VERSION ""

NS_ :

BS_:

BU_: SHVU_CCS_FD ARS_FD WPC_FD WPC2_FD SCM_FD SHVU_FRNT_FD FLLR_FD GW_SAU_DRV_FD ATS_FD PSB_FD GW_PSU_RR_FD SHVU_RL_FD RWPC_FD CGW_CCU OHCL_FD SHVU_REAR_FD BLTN_CAM_FD GW_PSU_DRV_FD FCS_FD GW_PSU_AST_FD GW_PSU_3RD_FD RCS_FD GW_PSU_RL_FD SHVU_3RD_FD SHVU_RR_FD RCM_FD DCM_FD SGU_FD vFD_B2

BO_ 977 BDC_FD_02_200ms: 32 CGW_CCU
 SG_ BCM_Ign2InSta_Copy_0 : 24|2@1+ (1,0) [0|0] ""  ARS_FD,ATS_FD,BLTN_CAM_FD,DCM_FD,FCS_FD,FLLR_FD,GW_PSU_3RD_FD,GW_PSU_AST_FD,GW_PSU_DRV_FD,GW_PSU_RL_FD,GW_PSU_RR_FD,GW_SAU_DRV_FD,OHCL_FD,PSB_FD,RCM_FD,RCS_FD,RWPC_FD,SCM_FD,SGU_FD,SHVU_3RD_FD,SHVU_CCS_FD,SHVU_FRNT_FD,SHVU_REAR_FD,SHVU_RL_FD,SHVU_RR_FD,vFD_B2,WPC2_FD,WPC_FD
 SG_ BCM_Ign1InSta_Copy_0 : 26|2@1+ (1,0) [0|0] ""  ARS_FD,ATS_FD,BLTN_CAM_FD,DCM_FD,FCS_FD,FLLR_FD,GW_PSU_3RD_FD,GW_PSU_AST_FD,GW_PSU_DRV_FD,GW_PSU_RL_FD,GW_PSU_RR_FD,GW_SAU_DRV_FD,OHCL_FD,PSB_FD,RCM_FD,RCS_FD,RWPC_FD,SCM_FD,SGU_FD,SHVU_3RD_FD,SHVU_CCS_FD,SHVU_FRNT_FD,SHVU_REAR_FD,SHVU_RL_FD,SHVU_RR_FD,vFD_B2,WPC2_FD,WPC_FD
 SG_ BCM_AccInSta_Copy_0 : 28|2@1+ (1,0) [0|0] ""  ARS_FD,ATS_FD,BLTN_CAM_FD,DCM_FD,FCS_FD,FLLR_FD,GW_PSU_3RD_FD,GW_PSU_AST_FD,GW_PSU_DRV_FD,GW_PSU_RL_FD,GW_PSU_RR_FD,GW_SAU_DRV_FD,OHCL_FD,PSB_FD,RCM_FD,RCS_FD,RWPC_FD,SCM_FD,SGU_FD,SHVU_3RD_FD,SHVU_CCS_FD,SHVU_FRNT_FD,SHVU_REAR_FD,SHVU_RL_FD,SHVU_RR_FD,vFD_B2,WPC2_FD,WPC_FD
 SG_ BCM_KeyInSta_Copy_0 : 30|2@1+ (1,0) [0|0] ""  ARS_FD,ATS_FD,BLTN_CAM_FD,DCM_FD,FCS_FD,FLLR_FD,GW_PSU_3RD_FD,GW_PSU_AST_FD,GW_PSU_DRV_FD,GW_PSU_RL_FD,GW_PSU_RR_FD,GW_SAU_DRV_FD,OHCL_FD,PSB_FD,RCM_FD,RCS_FD,RWPC_FD,SCM_FD,SGU_FD,SHVU_3RD_FD,SHVU_CCS_FD,SHVU_FRNT_FD,SHVU_REAR_FD,SHVU_RL_FD,SHVU_RR_FD,vFD_B2,WPC2_FD,WPC_FD

BO_ 1941 dummy_GST_BLTN_CAM: 8 CGW_CCU
 SG_ dummy_GST_BLTN_CAM_Byte : 0|64@1+ (1,0) [0|0] ""  BLTN_CAM_FD

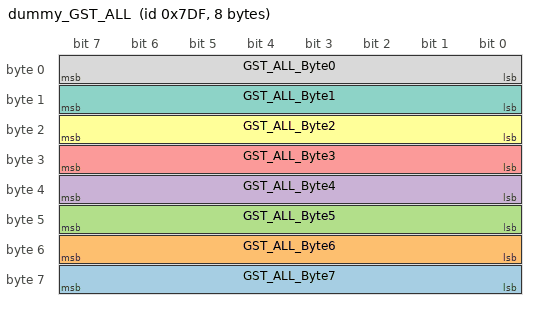
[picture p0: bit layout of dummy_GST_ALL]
BO_ 2015 dummy_GST_ALL: 8 CGW_CCU
 SG_ GST_ALL_Byte7 : 56|8@1+ (1,0) [0|0] ""  ARS_FD,ATS_FD,BLTN_CAM_FD,DCM_FD,FCS_FD,FLLR_FD,GW_PSU_3RD_FD,GW_PSU_AST_FD,GW_PSU_DRV_FD,GW_PSU_RL_FD,GW_PSU_RR_FD,GW_SAU_DRV_FD,OHCL_FD,PSB_FD,RCM_FD,RCS_FD,RWPC_FD,SCM_FD,SGU_FD,SHVU_3RD_FD,SHVU_CCS_FD,SHVU_FRNT_FD,SHVU_REAR_FD,SHVU_RL_FD,SHVU_RR_FD,vFD_B2,WPC2_FD,WPC_FD
 SG_ GST_ALL_Byte6 : 48|8@1+ (1,0) [0|0] ""  ARS_FD,ATS_FD,BLTN_CAM_FD,DCM_FD,FCS_FD,FLLR_FD,GW_PSU_3RD_FD,GW_PSU_AST_FD,GW_PSU_DRV_FD,GW_PSU_RL_FD,GW_PSU_RR_FD,GW_SAU_DRV_FD,OHCL_FD,PSB_FD,RCM_FD,RCS_FD,RWPC_FD,SCM_FD,SGU_FD,SHVU_3RD_FD,SHVU_CCS_FD,SHVU_FRNT_FD,SHVU_REAR_FD,SHVU_RL_FD,SHVU_RR_FD,vFD_B2,WPC2_FD,WPC_FD
 SG_ GST_ALL_Byte5 : 40|8@1+ (1,0) [0|0] ""  ARS_FD,ATS_FD,BLTN_CAM_FD,DCM_FD,FCS_FD,FLLR_FD,GW_PSU_3RD_FD,GW_PSU_AST_FD,GW_PSU_DRV_FD,GW_PSU_RL_FD,GW_PSU_RR_FD,GW_SAU_DRV_FD,OHCL_FD,PSB_FD,RCM_FD,RCS_FD,RWPC_FD,SCM_FD,SGU_FD,SHVU_3RD_FD,SHVU_CCS_FD,SHVU_FRNT_FD,SHVU_REAR_FD,SHVU_RL_FD,SHVU_RR_FD,vFD_B2,WPC2_FD,WPC_FD
 SG_ GST_ALL_Byte4 : 32|8@1+ (1,0) [0|0] ""  ARS_FD,ATS_FD,BLTN_CAM_FD,DCM_FD,FCS_FD,FLLR_FD,GW_PSU_3RD_FD,GW_PSU_AST_FD,GW_PSU_DRV_FD,GW_PSU_RL_FD,GW_PSU_RR_FD,GW_SAU_DRV_FD,OHCL_FD,PSB_FD,RCM_FD,RCS_FD,RWPC_FD,SCM_FD,SGU_FD,SHVU_3RD_FD,SHVU_CCS_FD,SHVU_FRNT_FD,SHVU_REAR_FD,SHVU_RL_FD,SHVU_RR_FD,vFD_B2,WPC2_FD,WPC_FD
 SG_ GST_ALL_Byte3 : 24|8@1+ (1,0) [0|0] ""  ARS_FD,ATS_FD,BLTN_CAM_FD,DCM_FD,FCS_FD,FLLR_FD,GW_PSU_3RD_FD,GW_PSU_AST_FD,GW_PSU_DRV_FD,GW_PSU_RL_FD,GW_PSU_RR_FD,GW_SAU_DRV_FD,OHCL_FD,PSB_FD,RCM_FD,RCS_FD,RWPC_FD,SCM_FD,SGU_FD,SHVU_3RD_FD,SHVU_CCS_FD,SHVU_FRNT_FD,SHVU_REAR_FD,SHVU_RL_FD,SHVU_RR_FD,vFD_B2,WPC2_FD,WPC_FD
 SG_ GST_ALL_Byte2 : 16|8@1+ (1,0) [0|0] ""  ARS_FD,ATS_FD,BLTN_CAM_FD,DCM_FD,FCS_FD,FLLR_FD,GW_PSU_3RD_FD,GW_PSU_AST_FD,GW_PSU_DRV_FD,GW_PSU_RL_FD,GW_PSU_RR_FD,GW_SAU_DRV_FD,OHCL_FD,PSB_FD,RCM_FD,RCS_FD,RWPC_FD,SCM_FD,SGU_FD,SHVU_3RD_FD,SHVU_CCS_FD,SHVU_FRNT_FD,SHVU_REAR_FD,SHVU_RL_FD,SHVU_RR_FD,vFD_B2,WPC2_FD,WPC_FD
 SG_ GST_ALL_Byte1 : 8|8@1+ (1,0) [0|0] ""  ARS_FD,ATS_FD,BLTN_CAM_FD,DCM_FD,FCS_FD,FLLR_FD,GW_PSU_3RD_FD,GW_PSU_AST_FD,GW_PSU_DRV_FD,GW_PSU_RL_FD,GW_PSU_RR_FD,GW_SAU_DRV_FD,OHCL_FD,PSB_FD,RCM_FD,RCS_FD,RWPC_FD,SCM_FD,SGU_FD,SHVU_3RD_FD,SHVU_CCS_FD,SHVU_FRNT_FD,SHVU_REAR_FD,SHVU_RL_FD,SHVU_RR_FD,vFD_B2,WPC2_FD,WPC_FD
 SG_ GST_ALL_Byte0 : 0|8@1+ (1,0) [0|0] ""  ARS_FD,ATS_FD,BLTN_CAM_FD,DCM_FD,FCS_FD,FLLR_FD,GW_PSU_3RD_FD,GW_PSU_AST_FD,GW_PSU_DRV_FD,GW_PSU_RL_FD,GW_PSU_RR_FD,GW_SAU_DRV_FD,OHCL_FD,PSB_FD,RCM_FD,RCS_FD,RWPC_FD,SCM_FD,SGU_FD,SHVU_3RD_FD,SHVU_CCS_FD,SHVU_FRNT_FD,SHVU_REAR_FD,SHVU_RL_FD,SHVU_RR_FD,vFD_B2,WPC2_FD,WPC_FD

BO_ 1949 dummy_BLTN_CAM_GST: 8 BLTN_CAM_FD
 SG_ dummy_BLTN_CAM_GST_Byte : 0|64@1- (1,0) [0|0] "" Vector__XXX

BO_ 956 BLTN_CAM_FD_02_200ms: 24 BLTN_CAM_FD
 SG_ BLTN_CAM_FD_Crc2Val : 0|16@1+ (1,0) [0|0] "" Vector__XXX
 SG_ BLTN_CAM_Set_EV_BfrTime : 102|5@1+ (1,0) [0|0] ""  CGW_CCU
 SG_ BLTN_CAM_Set_EV_AftTime : 107|5@1+ (1,0) [0|0] ""  CGW_CCU
 SG_ BLTN_CAM_Set_Drv_TML_Int : 112|4@1+ (1,0) [0|0] ""  CGW_CCU
 SG_ BLTN_CAM_SenSet_DEV : 116|4@1+ (1,0) [0|0] ""  CGW_CCU
 SG_ BLTN_CAM_SenSet_PEV : 120|4@1+ (1,0) [0|0] ""  CGW_CCU
 SG_ BLTN_CAM_Set_FR_Ver_Pos : 128|5@1+ (1,0) [0|0] ""  CGW_CCU
 SG_ BLTN_CAM_Set_RR_Ver_Pos : 133|5@1+ (1,0) [0|0] ""  CGW_CCU
 SG_ BLTN_CAM_Set_PEV_AppNoti : 138|2@1+ (1,0) [0|0] ""  CGW_CCU
 SG_ BLTN_CAM_Set_WiFi_AutoOn : 140|2@1+ (1,0) [0|0] ""  CGW_CCU
 SG_ BLTN_CAM_StrgPropSet : 142|4@1+ (1,0) [0|0] ""  CGW_CCU
 SG_ BLTN_CAM_File_DEL_CPY_Op_State : 146|4@1+ (1,0) [0|0] ""  CGW_CCU
 SG_ BLTN_CAM_File_DEL_CPY_NumTot : 150|16@1+ (1,0) [0|0] ""  CGW_CCU
 SG_ BLTN_CAM_FD_AlvCnt2Val : 16|8@1+ (1,0) [0|0] "" Vector__XXX
 SG_ BLTN_CAM_File_DEL_CPYed_Num : 166|16@1+ (1,0) [0|0] ""  CGW_CCU
 SG_ VAPI_BltnCamInsideSwEnable_Get : 182|2@1+ (1,0) [0|0] ""  CGW_CCU
 SG_ BLTN_CAM_Set_PMD : 24|2@1+ (1,0) [0|0] ""  CGW_CCU
 SG_ BLTN_CAM_Set_PMDEV : 26|2@1+ (1,0) [0|0] ""  CGW_CCU
 SG_ BLTN_CAM_RanSet_PMDR : 28|4@1+ (1,0) [0|0] ""  CGW_CCU
 SG_ BLTN_CAM_MaxRanSet_PMDR : 32|4@1+ (1,0) [0|0] ""  CGW_CCU
 SG_ BLTN_CAM_Set_PMDTime : 36|8@1+ (1,0) [0|0] ""  CGW_CCU
 SG_ BLTN_CAM_Set_BPR_TM : 44|3@1+ (1,0) [0|0] ""  CGW_CCU
 SG_ BLTN_CAM_Set_BPR_RE : 47|3@1+ (1,0) [0|0] ""  CGW_CCU
 SG_ BLTN_CAM_BPR_SndRec_Set : 50|2@1+ (1,0) [0|0] ""  CGW_CCU
 SG_ BLTN_CAM_BPR_AutRec_Set : 52|2@1+ (1,0) [0|0] ""  CGW_CCU
 SG_ BLTN_CAM_RecSet_LPE : 54|2@1+ (1,0) [0|0] ""  CGW_CCU
 SG_ BLTN_CAM_Set_Distort_Correct : 56|2@1+ (1,0) [0|0] ""  CGW_CCU
 SG_ BLTN_CAM_Set_Pollution_Warn : 58|2@1+ (1,0) [0|0] ""  CGW_CCU
 SG_ BLTN_CAM_Set_Crash_Pos : 60|2@1+ (1,0) [0|0] ""  CGW_CCU
 SG_ BLTN_CAM_Stm_all : 62|2@1+ (1,0) [0|0] ""  CGW_CCU
 SG_ BLTN_CAM_RecSet_OWD : 64|2@1+ (1,0) [0|0] ""  CGW_CCU
 SG_ BLTN_CAM_RecSet_DEV : 66|2@1+ (1,0) [0|0] ""  CGW_CCU
 SG_ BLTN_CAM_RecSet_OWP : 68|2@1+ (1,0) [0|0] ""  CGW_CCU
 SG_ BLTN_CAM_RecSet_PEV : 70|2@1+ (1,0) [0|0] ""  CGW_CCU
 SG_ BLTN_CAM_AudRec_Set : 72|2@1+ (1,0) [0|0] ""  CGW_CCU
 SG_ BLTN_CAM_Set_Tim_Stm : 74|2@1+ (1,0) [0|0] ""  CGW_CCU
 SG_ BLTN_CAM_Set_Spd_Stm : 76|2@1+ (1,0) [0|0] ""  CGW_CCU
 SG_ BLTN_CAM_Set_Locatn_Stm : 78|2@1+ (1,0) [0|0] ""  CGW_CCU
 SG_ BLTN_CAM_Set_TrnSig_Stm : 80|2@1+ (1,0) [0|0] ""  CGW_CCU
 SG_ BLTN_CAM_Set_AclBrk_Stm : 82|2@1+ (1,0) [0|0] ""  CGW_CCU
 SG_ BLTN_CAM_Set_GearPos_Stm : 84|2@1+ (1,0) [0|0] ""  CGW_CCU
 SG_ BLTN_CAM_Set_EVSen_Stm : 86|2@1+ (1,0) [0|0] ""  CGW_CCU
 SG_ BLTN_CAM_Set_StrAngl_Stm : 88|2@1+ (1,0) [0|0] ""  CGW_CCU
 SG_ BLTN_CAM_Set_EV_RecMaxTime : 90|2@1+ (1,0) [0|0] ""  CGW_CCU
 SG_ BLTN_CAM_RecSet_STRM : 92|2@1+ (1,0) [0|0] ""  CGW_CCU
 SG_ BLTN_CAM_Set_PrkTime : 94|8@1+ (1,0) [0|0] "Hour"  CGW_CCU

BO_ 957 BLTN_CAM_FD_STAT_01_200ms: 24 BLTN_CAM_FD
 SG_ BLTN_CAM_FD_STAT_Crc1Val : 0|16@1+ (1,0) [0|0] "" Vector__XXX
 SG_ BLTN_CAM_Prk_Oprable_Time : 100|8@1+ (1,0) [0|0] "Hour"  CGW_CCU
 SG_ BLTN_CAM_Prk_Oprable_Time_Max : 108|8@1+ (1,0) [0|0] "Hour"  CGW_CCU
 SG_ BLTN_CAM_AuxBat_Conn_State : 116|2@1+ (1,0) [0|0] ""  CGW_CCU
 SG_ BLTN_CAM_AuxBat_CapPer : 118|7@1+ (1,0) [0|0] "%"  CGW_CCU
 SG_ BLTN_CAM_ResetOpSta : 125|2@1+ (1,0) [0|0] "" Vector__XXX
 SG_ BLTN_CAM_SWVerMajor : 128|7@1+ (1,0) [0|0] ""  CGW_CCU
 SG_ BLTN_CAM_SWVerMinor1 : 136|7@1+ (1,0) [0|0] ""  CGW_CCU
 SG_ BLTN_CAM_SWVerMinor2 : 144|7@1+ (1,0) [0|0] ""  CGW_CCU
 SG_ BLTN_CAM_SWVerMinor3 : 152|7@1+ (1,0) [0|0] ""  CGW_CCU
 SG_ BLTN_CAM_FD_STAT_AlvCnt1Val : 16|8@1+ (1,0) [0|0] "" Vector__XXX
 SG_ BLTN_CAM_SD_Card_Manufacturer : 160|3@1+ (1,0) [0|0] ""  CGW_CCU
 SG_ BLTN_CAM_SD_Card_Cap_Class : 163|3@1+ (1,0) [0|0] ""  CGW_CCU
 SG_ BltnCamPlatformStatus : 166|4@1+ (1,0) [0|0] ""  CGW_CCU
 SG_ BLTN_CAM_CHInfo : 170|4@1+ (1,0) [0|0] ""  CGW_CCU
 SG_ BLTN_CAM_FoDInfo : 174|4@1+ (1,0) [0|0] ""  CGW_CCU
 SG_ BLTN_CAM_WiFi_Info_QR : 178|2@1+ (1,0) [0|0] ""  CGW_CCU
 SG_ BLTN_CAM_WiFi_Info_IP : 180|3@1+ (1,0) [0|0] ""  CGW_CCU
 SG_ BLTN_CAM_DistributeInfo1 : 183|5@1+ (1,0) [0|0] ""  CGW_CCU
 SG_ BltnCamSTRM_ServiceStatus : 188|3@1+ (1,0) [0|0] ""  CGW_CCU
 SG_ BLTN_CAM_PMD_Oprable_Time : 24|8@1+ (1,0) [0|0] ""  CGW_CCU
 SG_ BLTN_CAM_PMD_Oprable_Time_Max : 32|8@1+ (1,0) [0|0] ""  CGW_CCU
 SG_ BLTN_CAM_RecSta_PMD : 40|2@1+ (1,0) [0|0] ""  CGW_CCU
 SG_ BLTN_CAM_RecSta_BPR : 42|2@1+ (1,0) [0|0] ""  CGW_CCU
 SG_ BLTN_CAM_BPR_Spprt_Info : 44|2@1+ (1,0) [0|0] ""  CGW_CCU
 SG_ BLTN_CAM_PDC_Reset_Opt : 46|2@1+ (1,0) [0|0] ""  CGW_CCU
 SG_ BLTN_CAM_RecSta_LPE : 48|2@1+ (1,0) [0|0] ""  CGW_CCU
 SG_ BLTN_CAM_DistributeInfo : 50|6@1+ (1,0) [0|0] ""  CGW_CCU
 SG_ BLTN_CAM_Sta_STRM : 56|4@1+ (1,0) [0|0] ""  CGW_CCU
 SG_ BLTN_CAM_LPE_Option : 60|2@1+ (1,0) [0|0] ""  CGW_CCU
 SG_ BLTN_CAM_State : 64|4@1+ (1,0) [0|0] ""  CGW_CCU
 SG_ BLTN_CAM_SD_Card_State : 68|4@1+ (1,0) [0|0] ""  CGW_CCU
 SG_ BLTN_CAM_RecSta_OWD : 72|2@1+ (1,0) [0|0] ""  CGW_CCU
 SG_ BLTN_CAM_RecSta_DEV : 74|2@1+ (1,0) [0|0] ""  CGW_CCU
 SG_ BLTN_CAM_RecSta_MAR : 76|2@1+ (1,0) [0|0] ""  CGW_CCU
 SG_ BLTN_CAM_RecSta_TML : 78|2@1+ (1,0) [0|0] ""  CGW_CCU
 SG_ BLTN_CAM_RecSta_OWP : 80|2@1+ (1,0) [0|0] ""  CGW_CCU
 SG_ BLTN_CAM_RecSta_PEV : 82|2@1+ (1,0) [0|0] ""  CGW_CCU
 SG_ BLTN_CAM_Prk_EV_Cnt : 84|8@1+ (1,0) [0|0] ""  CGW_CCU
 SG_ BLTN_CAM_Prk_Oped_Time : 92|8@1+ (1,0) [0|0] "Hour"  CGW_CCU

BO_ 686 HU_Car_01_200ms: 16 CGW_CCU
 SG_ HU_Car_Crc1Val : 0|16@1+ (1,0) [0|0] "" Vector__XXX
 SG_ HU_Car_AlvCnt1Val : 16|8@1+ (1,0) [0|0] "" Vector__XXX
 SG_ HU_IncomingCallState : 24|3@1+ (1,0) [0|0] "" Vector__XXX
 SG_ HU_HardReset_Available : 27|1@1+ (1,0) [0|0] "" Vector__XXX
 SG_ HU_MKBD_ModeSwitch : 66|2@1+ (1,0) [0|0] "" Vector__XXX
 SG_ HU_VehiclePwr : 68|4@1+ (1,0) [0|0] ""  BLTN_CAM_FD,SGU_FD
 SG_ HU_BtnShowReq : 72|3@1+ (1,0) [0|0] "" Vector__XXX
 SG_ HU_ADMSettingState : 75|3@1+ (1,0) [0|0] "" Vector__XXX
 SG_ HU_PwrState : 80|4@1+ (1,0) [0|0] ""  BLTN_CAM_FD
 SG_ HU_LCDState : 84|3@1+ (1,0) [0|0] "" Vector__XXX

BO_ 274 HU_USM_02_00ms: 32 CGW_CCU
 SG_ HU_USM_Crc2Val : 0|16@1+ (1,0) [0|0] ""  GW_PSU_DRV_FD
 SG_ CF_AVN_CluRheostatLvl : 113|5@1+ (1,0) [0|0] "" Vector__XXX
 SG_ CF_AVN_EVReset : 118|2@1+ (1,0) [0|0] "" Vector__XXX
 SG_ CF_AVN_UnitReset : 120|2@1+ (1,0) [0|0] "" Vector__XXX
 SG_ CF_AVN_IcyRoadWarn : 122|2@1+ (1,0) [0|0] "" Vector__XXX
 SG_ CF_AVN_CluServiceReminderReset : 124|2@1+ (1,0) [0|0] "" Vector__XXX
 SG_ CF_AVN_CluUSMReset : 126|2@1+ (1,0) [0|0] ""  ARS_FD,ATS_FD,BLTN_CAM_FD,GW_PSU_3RD_FD,GW_PSU_AST_FD,GW_PSU_DRV_FD,GW_PSU_RL_FD,GW_PSU_RR_FD,GW_SAU_DRV_FD,RCM_FD,RWPC_FD,SGU_FD,SHVU_FRNT_FD,SHVU_REAR_FD,SHVU_RL_FD,SHVU_RR_FD,WPC2_FD,WPC_FD
 SG_ C_HCIMSWeightNValueSet : 128|4@1+ (1,0) [0|0] "" Vector__XXX
 SG_ C_HCIMSHeightNvalueSet : 132|4@1+ (1,0) [0|0] "" Vector__XXX
 SG_ CF_AVN_HCIMSButtonCommand : 136|4@1+ (1,0) [0|0] "" Vector__XXX
 SG_ C_HCIMSSitHeightNValueSet : 140|4@1+ (1,0) [0|0] "" Vector__XXX
 SG_ CF_AVN_BodySpprtSet : 152|2@1+ (1,0) [0|0] ""  GW_PSU_DRV_FD,GW_SAU_DRV_FD
 SG_ HU_USM_AlvCnt2Val : 16|8@1+ (1,0) [0|0] ""  GW_PSU_DRV_FD
 SG_ CF_AVN_AirSptTimeNValueSet : 161|3@1+ (1,0) [0|0] ""  GW_SAU_DRV_FD
 SG_ CF_AVN_AirSptStrNValue : 164|2@1+ (1,0) [0|0] ""  GW_SAU_DRV_FD
 SG_ CF_AVN_SeatDrvModNValueSet : 166|2@1+ (1,0) [0|0] ""  GW_PSU_DRV_FD,GW_SAU_DRV_FD
 SG_ C_SmrtSldngDrNValueSet : 176|3@1+ (1,0) [0|0] "" Vector__XXX
 SG_ CF_AVN_TurboPressureUnit : 179|3@1+ (1,0) [0|0] "" Vector__XXX
 SG_ CF_AVN_CluTorqueUnit : 182|2@1+ (1,0) [0|0] "" Vector__XXX
 SG_ CF_AVN_MoodLpRedNValueSet : 192|10@1+ (1,0) [0|0] "" Vector__XXX
 SG_ CF_AVN_MoodLpGreenNValueSet : 202|10@1+ (1,0) [0|0] "" Vector__XXX
 SG_ CF_AVN_MoodLpBlueNValueSet : 212|10@1+ (1,0) [0|0] "" Vector__XXX
 SG_ CF_AVN_MoodLpBrightNValueSet : 223|9@1+ (1,0) [0|0] "" Vector__XXX
 SG_ CF_AVN_HBANValueSet : 232|2@1+ (1,0) [0|0] "" Vector__XXX
 SG_ CF_AVN_IFSActVehSpd_Set : 234|4@1+ (1,0) [0|0] "" Vector__XXX
 SG_ C_MoodLpDrivingNValue : 238|2@1+ (1,0) [0|0] "" Vector__XXX
 SG_ HU_DrivingPostureAssistUSMSet : 24|4@1+ (1,0) [0|0] "" Vector__XXX
 SG_ C_MoodLPDrivemodeNValue : 240|2@1+ (1,0) [0|0] "" Vector__XXX
 SG_ CF_AVN_SVMAutoOnNvalueSet : 242|2@1+ (1,0) [0|0] "" Vector__XXX
 SG_ CF_AVN_DAW_LVDANValueSet : 244|2@1+ (1,0) [0|0] "" Vector__XXX
 SG_ CF_AVN_Clu3dDepthSet : 248|3@1+ (1,0) [0|0] "" Vector__XXX
 SG_ C_MoodLpFadeNValue : 251|2@1+ (1,0) [0|0] ""  ATS_FD
 SG_ HU_DrvCushAirSprtUSMSet : 28|3@1+ (1,0) [0|0] "" Vector__XXX
 SG_ HU_AstCushAirSprtUSMSet : 31|3@1+ (1,0) [0|0] "" Vector__XXX
 SG_ HU_DrvStrchMassageSwSet : 34|2@1+ (1,0) [0|0] "" Vector__XXX
 SG_ HU_DrvStrchMassageModeUSMSet : 36|3@1+ (1,0) [0|0] "" Vector__XXX
 SG_ HU_DrvStrchMassageStrengthUSMSet : 39|3@1+ (1,0) [0|0] "" Vector__XXX
 SG_ HU_DrvStrchMassageTimeUSMSet : 42|3@1+ (1,0) [0|0] "" Vector__XXX
 SG_ HU_AstStrchMassageSwSet : 45|2@1+ (1,0) [0|0] "" Vector__XXX
 SG_ HU_AstStrchMassageModeUSMSet : 47|3@1+ (1,0) [0|0] "" Vector__XXX
 SG_ HU_AstStrchMassageStrengthUSMSet : 50|3@1+ (1,0) [0|0] "" Vector__XXX
 SG_ HU_AstStrchMassageTimeUSMSet : 53|3@1+ (1,0) [0|0] "" Vector__XXX
 SG_ HU_DrvMsgPulseUSMSet : 56|2@1+ (1,0) [0|0] "" Vector__XXX
 SG_ HU_AstMsgPulseUSMSet : 58|2@1+ (1,0) [0|0] "" Vector__XXX
 SG_ HU_RLMsgPulseUSMSet : 60|2@1+ (1,0) [0|0] "" Vector__XXX
 SG_ HU_RRMsgPulseUSMSet : 62|2@1+ (1,0) [0|0] "" Vector__XXX
 SG_ CF_AVN_CluWelcomeSnd : 64|2@1+ (1,0) [0|0] "" Vector__XXX
 SG_ CF_AVN_CluServiceReminderSet : 72|2@1+ (1,0) [0|0] "" Vector__XXX
 SG_ CF_AVN_CluTransmissionDisp : 74|2@1+ (1,0) [0|0] "" Vector__XXX
 SG_ CF_AVN_CluWiperLight : 76|2@1+ (1,0) [0|0] "" Vector__XXX
 SG_ CF_AVN_CluRoadInfoGuide : 78|2@1+ (1,0) [0|0] "" Vector__XXX
 SG_ CF_AVN_CluUserSettingPeriod : 81|7@1+ (1,0) [0|0] "" Vector__XXX
 SG_ CF_AVN_CluFuelEconUnit_mi : 91|2@1+ (1,0) [0|0] "" Vector__XXX
 SG_ CF_AVN_CluFuelEconUnit_km : 93|2@1+ (1,0) [0|0] "" Vector__XXX
 SG_ CF_AVN_CluUserSettingDistance : 95|17@1+ (1,0) [0|0] "" Vector__XXX

BO_ 685 HU_BLTN_CAM_02_200ms: 16 CGW_CCU
 SG_ HU_BLTN_CAM_Crc2Val : 0|16@1+ (1,0) [0|0] "" Vector__XXX
 SG_ HU_BLTN_CAM_AlvCnt2Val : 16|8@1+ (1,0) [0|0] "" Vector__XXX
 SG_ HU_WiFi_State : 24|4@1+ (1,0) [0|0] ""  BLTN_CAM_FD
 SG_ HU_BLTN_CAM_UI_Mode : 64|4@1+ (1,0) [0|0] ""  BLTN_CAM_FD
 SG_ HU_BLTN_CAM_Display : 68|3@1+ (1,0) [0|0] ""  BLTN_CAM_FD

BO_ 138 HU_GW_01_00ms: 32 CGW_CCU
 SG_ HU_GW_Crc1Val : 0|16@1+ (1,0) [0|0] ""  GW_PSU_DRV_FD
 SG_ HU_TgSoc_QcChg_Set : 104|8@1+ (0.5,0) [0|100] "%" Vector__XXX
 SG_ HU_UserApproval : 120|4@1+ (1,0) [0|0] "" Vector__XXX
 SG_ HU_OtaInfomationReq : 124|4@1+ (1,0) [0|0] "" Vector__XXX
 SG_ HU_ICU_RearDefSet : 152|2@1+ (1,0) [0|0] "" Vector__XXX
 SG_ HU_CDMOpenCmd : 156|2@1+ (1,0) [0|0] "" Vector__XXX
 SG_ C_PreCrankReq : 158|2@1+ (1,0) [0|0] ""  BLTN_CAM_FD
 SG_ HU_GW_AlvCnt1Val : 16|8@1+ (1,0) [0|0] ""  GW_PSU_DRV_FD
 SG_ C_TeleAstSeatOpCmdIBOX : 160|4@1+ (1,0) [0|0] ""  GW_PSU_AST_FD,SHVU_FRNT_FD
 SG_ C_TeleDrvSeatOpCmdIBOX : 164|4@1+ (1,0) [0|0] ""  GW_PSU_AST_FD,GW_PSU_DRV_FD,SHVU_FRNT_FD
 SG_ C_TeleRRSeatOpCmdIBOX : 168|4@1+ (1,0) [0|0] ""  ATS_FD,GW_PSU_RL_FD,GW_PSU_RR_FD,SHVU_FRNT_FD,SHVU_REAR_FD,SHVU_RR_FD
 SG_ C_TeleRLSeatOpCmdIBOX : 172|4@1+ (1,0) [0|0] ""  ATS_FD,GW_PSU_RL_FD,GW_PSU_RR_FD,SHVU_FRNT_FD,SHVU_REAR_FD,SHVU_RL_FD
 SG_ C_DrvPSDCloseRlyIBOX : 184|2@1+ (1,0) [0|0] "" Vector__XXX
 SG_ C_DrvPSDOpenRlyIBOX : 186|2@1+ (1,0) [0|0] "" Vector__XXX
 SG_ C_AstPSDCloseRlyIBOX : 188|2@1+ (1,0) [0|0] "" Vector__XXX
 SG_ C_AstPSDOpenRlyIBOX : 190|2@1+ (1,0) [0|0] "" Vector__XXX
 SG_ HU_StrgWhlHeatingSet_VR : 195|3@1+ (1,0) [0|0] "" Vector__XXX
 SG_ AVN_VGS_SET : 200|2@1+ (1,0) [0|0] "" Vector__XXX
 SG_ MODE_VCU_SET2 : 202|3@1+ (1,0) [0|0] "" Vector__XXX
 SG_ AVN_DriftMode_SET : 205|3@1+ (1,0) [0|0] "" Vector__XXX
 SG_ AVN_NduranceRace_SET : 208|3@1+ (1,0) [0|0] "" Vector__XXX
 SG_ AVN_MaxRange_SET : 211|3@1+ (1,0) [0|0] "" Vector__XXX
 SG_ HU_MKBD_TouchSensSet : 217|3@1+ (1,0) [0|0] "" Vector__XXX
 SG_ AVN_NTDBalance_SET : 220|4@1+ (1,0) [0|0] "" Vector__XXX
 SG_ LaunchControl_Activate_EV : 224|2@1+ (1,0) [0|0] "" Vector__XXX
 SG_ LaunchControl_GripLevel_Reset : 226|2@1+ (1,0) [0|0] "" Vector__XXX
 SG_ LaunchControl_GripLevel_Set : 228|3@1+ (1,0) [0|0] "" Vector__XXX
 SG_ MODE_Drift_TCS_SET : 232|4@1+ (1,0) [0|0] "" Vector__XXX
 SG_ MODE_Drift_VDC_SET : 236|3@1+ (1,0) [0|0] "" Vector__XXX
 SG_ HU_Popupdown_Req : 24|2@1+ (1,0) [0|0] "" Vector__XXX
 SG_ MODE_Drift_MDPS_SET : 240|2@1+ (1,0) [0|0] "" Vector__XXX
 SG_ MODE_Drift_ECS_SET : 242|2@1+ (1,0) [0|0] "" Vector__XXX
 SG_ MODE_Drift_ELSD_SET : 244|2@1+ (1,0) [0|0] "" Vector__XXX
 SG_ HU_NCond_DragSet : 246|2@1+ (1,0) [0|0] "" Vector__XXX
 SG_ HU_NCond_TrackSet : 248|2@1+ (1,0) [0|0] "" Vector__XXX
 SG_ AVN_Npedal_SET : 250|3@1+ (1,0) [0|0] "" Vector__XXX
 SG_ AVN_NTD_SET : 253|3@1+ (1,0) [0|0] "" Vector__XXX
 SG_ HU_PopupAgreement_Push : 26|2@1+ (1,0) [0|0] "" Vector__XXX
 SG_ HU_StayModeStartReq : 30|3@1+ (1,0) [0|0] "" Vector__XXX
 SG_ HU_StayModeReservationReq : 33|3@1+ (1,0) [0|0] "" Vector__XXX
 SG_ HU_StayModeExtensionReq : 36|3@1+ (1,0) [0|0] "" Vector__XXX
 SG_ HU_StayModeSetReq : 39|3@1+ (1,0) [0|0] "" Vector__XXX
 SG_ HU_StayModeIdleTimeSetReq : 42|4@1+ (1,0) [0|0] "" Vector__XXX
 SG_ HU_StayModeMaxTimeSetReq : 46|4@1+ (1,0) [0|0] "" Vector__XXX
 SG_ MODE_Drift_VDC_Level_SET : 50|4@1+ (1,0) [0|0] "" Vector__XXX
 SG_ MODE_Drift_RTO_Level_SET : 54|3@1+ (1,0) [0|0] "" Vector__XXX
 SG_ HU_SafetyModeReq : 57|2@1+ (1,0) [0|0] "" Vector__XXX
 SG_ HU_DriveConfirmPopup : 59|2@1+ (1,0) [0|0] "" Vector__XXX
 SG_ HU_LghtDnSafetyModReq : 61|2@1+ (1,0) [0|0] "" Vector__XXX
 SG_ SWRC_Sensitivity_SET : 66|2@1+ (1,0) [0|0] "" Vector__XXX
 SG_ HU_ChgInCurrModSet : 75|3@1+ (1,0) [0|0] "" Vector__XXX
 SG_ HU_EV_WinterMode : 86|2@1+ (1,0) [0|0] "" Vector__XXX
 SG_ HU_TgSoc_ScChg_Set : 96|8@1+ (0.5,0) [0|100] "%" Vector__XXX

CM_ BO_ 956 "[PE] Periodic and On Event";
CM_ SG_ 956 BLTN_CAM_FD_Crc2Val "BLTN_CAM_FD_CyclicRedundancyCheck2Value";
CM_ SG_ 956 BLTN_CAM_Set_EV_BfrTime "Driving Event Time Setting - Before, Resolution : sec";
CM_ SG_ 956 BLTN_CAM_Set_EV_AftTime "Driving Event Time Setting - After, Resolution : sec";
CM_ SG_ 956 BLTN_CAM_Set_Drv_TML_Int "Record Set of Time-lapse Interval, Resolution : sec";
CM_ SG_ 956 BLTN_CAM_SenSet_DEV "Set of Event  Detection Sensitivity of Driving Mode";
CM_ SG_ 956 BLTN_CAM_SenSet_PEV "Set of Event  Detection Sensitivity of Parking Mode";
CM_ SG_ 956 BLTN_CAM_Set_FR_Ver_Pos "Front Camera Vertical position setting value.";
CM_ SG_ 956 BLTN_CAM_Set_RR_Ver_Pos "Rear Camera Vertical position setting value.";
CM_ SG_ 956 BLTN_CAM_Set_PEV_AppNoti "Parked Event notification to Connectivity Phone App. On/Off";
CM_ SG_ 956 BLTN_CAM_Set_WiFi_AutoOn "Wifi On/Off User setting";
CM_ SG_ 956 BLTN_CAM_StrgPropSet "Propotion of built-in Cam SD card Propotion set of the Recording Categories";
CM_ SG_ 956 BLTN_CAM_File_DEL_CPY_Op_State "Bulil in Cam Fily copy and delete operating state.";
CM_ SG_ 956 BLTN_CAM_File_DEL_CPY_NumTot "Number of Copied or Deleted files.";
CM_ SG_ 956 BLTN_CAM_FD_AlvCnt2Val "BLTN_CAM_FD_AliveCounter2Value";
CM_ SG_ 956 BLTN_CAM_File_DEL_CPYed_Num "Total number of the copy or delete file.";
CM_ SG_ 956 VAPI_BltnCamInsideSwEnable_Get "0x0:Default,0x1:Enable,0x2:Disable,0x3:Error indicator";
CM_ SG_ 956 BLTN_CAM_Set_PMD "Parked Motion Detection Record Mode On/Off Set";
CM_ SG_ 956 BLTN_CAM_Set_PMDEV "Parked Motion Detection Event Record On/Off Set";
CM_ SG_ 956 BLTN_CAM_RanSet_PMDR "Set of Range level of Parked Motion Detection Record Mode";
CM_ SG_ 956 BLTN_CAM_MaxRanSet_PMDR "Set Level Range of Parked Motion Detection Record Mode";
CM_ SG_ 956 BLTN_CAM_Set_PMDTime "Set the hours of Parked Motion Detection Mode";
CM_ SG_ 956 BLTN_CAM_Set_BPR_TM "Built-inCAM Performance Recorder Track Mode Set";
CM_ SG_ 956 BLTN_CAM_Set_BPR_RE "Built-inCAM Performance Recorder Resolution Set";
CM_ SG_ 956 BLTN_CAM_BPR_SndRec_Set "Built-inCAM Performance Recorder Sound Recording Set";
CM_ SG_ 956 BLTN_CAM_BPR_AutRec_Set "Built-inCAM Performance Recorder Automatic Record Set";
CM_ SG_ 956 BLTN_CAM_RecSet_LPE "Setting Information(On/Off) of Low Power Recording Mode";
CM_ SG_ 956 BLTN_CAM_Set_Distort_Correct "Setting Information(On/Off) of Side view Distortion Calibration";
CM_ SG_ 956 BLTN_CAM_Set_Pollution_Warn "Setting Information(On/Off) of CAM Lens Pollution Warning";
CM_ SG_ 956 BLTN_CAM_Set_Crash_Pos "Setting Information(On/Off) of Crashing Direction Display";
CM_ SG_ 956 BLTN_CAM_Stm_all "Setting Information(On/Off) of Stamping";
CM_ SG_ 956 BLTN_CAM_RecSet_OWD "Record On/Off Set of On While Driving";
CM_ SG_ 956 BLTN_CAM_RecSet_DEV "Record On/Off Set of Driving Event";
CM_ SG_ 956 BLTN_CAM_RecSet_OWP "Record On/Off Set of On While Parked, 0x0(Default) : Parking recording function not supported";
CM_ SG_ 956 BLTN_CAM_RecSet_PEV "Record Set of Parked Event, 0x0(Default) : Parking recording function not supported";
CM_ SG_ 956 BLTN_CAM_AudRec_Set "Audio Record On/Off Set";
CM_ SG_ 956 BLTN_CAM_Set_Tim_Stm "Record Set of Date and Time Stamp";
CM_ SG_ 956 BLTN_CAM_Set_Spd_Stm "Record Set of Speed Stamp";
CM_ SG_ 956 BLTN_CAM_Set_Locatn_Stm "Record Set of Location Stamp";
CM_ SG_ 956 BLTN_CAM_Set_TrnSig_Stm "Record Set of Turn Signal Stamp";
CM_ SG_ 956 BLTN_CAM_Set_AclBrk_Stm "Record Set of Accelerator Brake Stamp";
CM_ SG_ 956 BLTN_CAM_Set_GearPos_Stm "Record Set of Gear Position Stamp";
CM_ SG_ 956 BLTN_CAM_Set_EVSen_Stm "Record Set of Event Sensitivity Stamp";
CM_ SG_ 956 BLTN_CAM_Set_StrAngl_Stm "Record Set of Steering Angle Stamp";
CM_ SG_ 956 BLTN_CAM_Set_EV_RecMaxTime "Record Set of  EV Parking Rec Max Time On/Off";
CM_ SG_ 956 BLTN_CAM_RecSet_STRM "0x0:Default 0x1:Off 0x2:On 0x3:Invalid";
CM_ SG_ 956 BLTN_CAM_Set_PrkTime "Parking Operation Setting Time, Resolution : hr";
CM_ BO_ 957 "[PE] Periodic and On Event";
CM_ SG_ 957 BLTN_CAM_FD_STAT_Crc1Val "BLTN_CAM_FD_STAT_CyclicRedundancyCheck1Value";
CM_ SG_ 957 BLTN_CAM_Prk_Oprable_Time "The hours of Park Mode Operatable, the time is limited by user max oper. Set.";
CM_ SG_ 957 BLTN_CAM_Prk_Oprable_Time_Max "The hours of Park Mode Operatable, the time has no limit.";
CM_ SG_ 957 BLTN_CAM_AuxBat_Conn_State "0x0 : Default / 0x1 : Auxiliary Battery is connected.(P-LBM or B-LBM) / 0x2 : Auxiliary Battery Is not connected. - Auxiliary Battery applicable on this vehicle model / 0x3:  Auxiliary Battery is not connected. ? Auxiliary Battery not applicable on this vehicle model";
CM_ SG_ 957 BLTN_CAM_AuxBat_CapPer "The percentage of Aux. Bat.";
CM_ SG_ 957 BLTN_CAM_ResetOpSta "This signal indicates whether the reset operation has been completed or not";
CM_ SG_ 957 BLTN_CAM_SWVerMajor "First Word(ASCII) in Built-in Cam S/W Ver";
CM_ SG_ 957 BLTN_CAM_SWVerMinor1 "Minor1 in Built-in Cam S/W Ver";
CM_ SG_ 957 BLTN_CAM_SWVerMinor2 "Minor2 in Built-in Cam S/W Ver";
CM_ SG_ 957 BLTN_CAM_SWVerMinor3 "Minor3 in Built-in Cam S/W Ver";
CM_ SG_ 957 BLTN_CAM_FD_STAT_AlvCnt1Val "BLTN_CAM_FD_STAT_AliveCounter1Value";
CM_ SG_ 957 BLTN_CAM_SD_Card_Manufacturer "0x0(SD Card not found), 0x1(Micron-Genuine part), 0x2~0x5(Reserved), 0x6(Unknown), 0x7(Invalid)";
CM_ SG_ 957 BLTN_CAM_SD_Card_Cap_Class "0x0(SD Card not found), 0x1(64Gbyte Class), 0x2(128Gbyte Class), 0x3(256Gbyte Class), 0x4(512Gbyte Class), 0x5(1Tbyte Class), 0x6(2Tbyte Class), 0x7(Invalid)";
CM_ SG_ 957 BltnCamPlatformStatus "0x0 : DEFAULT // UNKNOWN status for initialization 0x1 : AVAILABLE - BLTN_CAM 2 or BLTN_CAM 2 Plus available 0x2 : AVAILABLE _BLTN_CAM 3 available 0x3 ~ 0xE : Reserved 0xF : Inavalid";
CM_ SG_ 957 BLTN_CAM_CHInfo "0x0:Default,  0x1:2CH Front, Rear,  0x2 : 4CH Fron,Rear,SideLeft,,SideRight,  0x3~0xE : Reserved.  0xF : Invalid";
CM_ SG_ 957 BLTN_CAM_FoDInfo "0x0:Default, 0x1:FoD Cloud Activated(Applied), 0x2 : FoD Deactivated(Not Applied), 0x2~ 0xE : Reserved, 0xF : Invalid";
CM_ SG_ 957 BLTN_CAM_WiFi_Info_QR "Default  = 0   // Unknown     QR_Not_Support = 1     QR_Support = 2";
CM_ SG_ 957 BLTN_CAM_WiFi_Info_IP "0x0: Unknown 0x1: IP: 192.168.x.1 (x : 1 or 2 or 3) 0x2: IP: 192.168.128.200 0x3 ~ 0x6: Reserved 0x7: Invalid";
CM_ SG_ 957 BLTN_CAM_DistributeInfo1 "DEFAULT = 0   // Default (Korea) Type     KOR = 1   // Korea (KOR) Type    GENERAL = 2 // General Type    MES = 3 //Middle East (MES) Type    EUR = 4 // Europe (EUR) Type    AUS = 5 //Australia (AUS) Type    CAN = 6 // Canada(CAN) Type    NA = 7 // North America?(NA) Type    CHN = 8 // China?(CHN) Type    JAP = 9 // Japan (JAP)";
CM_ SG_ 957 BltnCamSTRM_ServiceStatus "0x0 : Default, UNKNOWN status for initialization or NONE 0x1 : Standard Quality 0x2 : Premium Quility 0x3 ~ 0x6 : Reserved 0x7 : Inavlid";
CM_ SG_ 957 BLTN_CAM_PMD_Oprable_Time "the hours of Parked Motion Detection Mode Operatable";
CM_ SG_ 957 BLTN_CAM_PMD_Oprable_Time_Max "the hours of Parked Motion Detection Mode Operatable Max";
CM_ SG_ 957 BLTN_CAM_RecSta_PMD "This Signal inform recording status of Parked Motion Detection.";
CM_ SG_ 957 BLTN_CAM_RecSta_BPR "Record Status of Built-inCAM Performance Recorder";
CM_ SG_ 957 BLTN_CAM_BPR_Spprt_Info "Built-inCAM Performance Record Support information";
CM_ SG_ 957 BLTN_CAM_PDC_Reset_Opt "0x0:NotApplied/0x1:Applied /0x2: RESERVED /0x3:Invalid";
CM_ SG_ 957 BLTN_CAM_RecSta_LPE "Operation status of Low Power Event Recording mode while parking";
CM_ SG_ 957 BLTN_CAM_DistributeInfo "0x00:Default (Korea) 0x01:Korea (KOR) Type 0x02:General Type 0x03:Middle East (MES) Type 0x04:Europe (EUR) Type 0x05:Australia (AUS) Type 0x06:Canada Type 0x07:North America?(NA) Type  0x08:China?(CHN) Type 0x09:Japan (JAP) Type 0x0A:Russia?(RUS) Type 0x0B~0x3E:RESERVED 0x3F:Invalid";
CM_ SG_ 957 BLTN_CAM_Sta_STRM "0x0 : Not Support 0x1 : Available 0x2 : Sessioning (세션닝 중)  0x3 : Streaming (스트리밍 중) 0x4 ~ 0x9 : Reserved 0xA : Not Available - DashCam Error 0xB: Not Available - Daily time of use exceeded 0xC: Not Available - Daily Number of uses exceeded 0xD: Not Available - Monthly time of use exceeded 0xE: Not Available - Monthly Number of use";
CM_ SG_ 957 BLTN_CAM_LPE_Option "0x0:Default, 0x1:Applied(ICE/HEV), 0x2 : Not Applied(EV or No LPE Function), 0x3 : Invalid";
CM_ SG_ 957 BLTN_CAM_State "This Signal is for cluster warning popup.";
CM_ SG_ 957 BLTN_CAM_SD_Card_State "This Signal is for SD card Status in Built-in App menu and CCS Phone App.";
CM_ SG_ 957 BLTN_CAM_RecSta_OWD "This Signal inform recording status of On While Driving.";
CM_ SG_ 957 BLTN_CAM_RecSta_DEV "This Signal inform recording status of Driving Event.";
CM_ SG_ 957 BLTN_CAM_RecSta_MAR "This Signal inform recording status of Manual Recording.";
CM_ SG_ 957 BLTN_CAM_RecSta_TML "This Signal inform recording status of Time-lapse.";
CM_ SG_ 957 BLTN_CAM_RecSta_OWP "This Signal inform recording status of On While Parked.";
CM_ SG_ 957 BLTN_CAM_RecSta_PEV "This Signal inform recording status of Parked Event.";
CM_ SG_ 957 BLTN_CAM_Prk_EV_Cnt "The count number of a parked Event.";
CM_ SG_ 957 BLTN_CAM_Prk_Oped_Time "The Parked Opreated time ingormation";
CM_ BO_ 686 "[PE] Periodic and On Event";
CM_ SG_ 686 HU_Car_Crc1Val "HU_Car_CyclicRedundancyCheck1Value";
CM_ SG_ 686 HU_Car_AlvCnt1Val "HU_Car_AliveCounter1Value";
CM_ SG_ 686 HU_MKBD_ModeSwitch "This signal is used for the 'AVNT/Climate Switching Keyboard' to switch the display of buttons.";
CM_ SG_ 686 HU_VehiclePwr "Information for the H/U power status for ADM(Accessary Delay Mode)";
CM_ SG_ 686 HU_ADMSettingState "Information for ADM(Accessry Delay Mode) Setting Vaule in HU / Made at 2021.1.25";
CM_ BO_ 274 "[EC] On Event and On Change";
CM_ SG_ 274 HU_USM_Crc2Val "HU_USM_CyclicRedundancyCheck2Value";
CM_ SG_ 274 CF_AVN_CluRheostatLvl "Request to set CLU rheostat level";
CM_ SG_ 274 CF_AVN_EVReset "Request to reset EV Service (0x1 : EV USM Reset)";
CM_ SG_ 274 CF_AVN_UnitReset "Request to reset Unit setting";
CM_ SG_ 274 CF_AVN_IcyRoadWarn "Request to set CLU icy road warning";
CM_ SG_ 274 CF_AVN_CluServiceReminderReset "Request to reset CLU service reminder";
CM_ SG_ 274 CF_AVN_CluUSMReset "Request to reset all USM service";
CM_ SG_ 274 C_HCIMSWeightNValueSet "This signal is used for Healthcare IMS to input user's weight";
CM_ SG_ 274 C_HCIMSHeightNvalueSet "This signal is used for Healthcare IMS to input user's height";
CM_ SG_ 274 CF_AVN_HCIMSButtonCommand "User's input value in healthcare IMS mode";
CM_ SG_ 274 C_HCIMSSitHeightNValueSet "This signal is used for Healthcare IMS to input user's sitting height";
CM_ SG_ 274 CF_AVN_BodySpprtSet "This signal is for the seat body support USM";
CM_ SG_ 274 HU_USM_AlvCnt2Val "HU_USM_AliveCounter2Value";
CM_ SG_ 274 CF_AVN_AirSptTimeNValueSet "This signal is for the seat massage function time setting";
CM_ SG_ 274 CF_AVN_AirSptStrNValue "This signal is for the seat massage intensity USM";
CM_ SG_ 274 CF_AVN_SeatDrvModNValueSet "This signal is for the auto seat-drivemode user setting menu";
CM_ SG_ 274 CF_AVN_MoodLpRedNValueSet "Request for mood lamp color(Red)";
CM_ SG_ 274 CF_AVN_MoodLpGreenNValueSet "Request for mood lamp color(Green)";
CM_ SG_ 274 CF_AVN_MoodLpBlueNValueSet "Request for mood lamp color(Blue)";
CM_ SG_ 274 CF_AVN_MoodLpBrightNValueSet "Request for mood lamp bright";
CM_ SG_ 274 CF_AVN_HBANValueSet "USM Request for High Beam Assist";
CM_ SG_ 274 CF_AVN_IFSActVehSpd_Set "USM Request for Intelligent Front Lighting System";
CM_ SG_ 274 C_MoodLpDrivingNValue "USM Request value for mood lamp drivng interlock";
CM_ SG_ 274 C_MoodLPDrivemodeNValue "USM request for Mood Lamp color with Drive Mode";
CM_ SG_ 274 CF_AVN_SVMAutoOnNvalueSet "Request for SVM Auto On";
CM_ SG_ 274 CF_AVN_DAW_LVDANValueSet "Request for Front Vehicle Departure Alert";
CM_ SG_ 274 CF_AVN_Clu3dDepthSet "This signal is used for request to set the depth of 3D";
CM_ SG_ 274 C_MoodLpFadeNValue "This signal indicates MLM Fade in/out control.";
CM_ SG_ 274 CF_AVN_CluWelcomeSnd "Request to set CLU welcome soun";
CM_ SG_ 274 CF_AVN_CluServiceReminderSet "Request to set CLU service notification";
CM_ SG_ 274 CF_AVN_CluTransmissionDisp "Request to set CLU transmission display";
CM_ SG_ 274 CF_AVN_CluWiperLight "Request to set CLU wiper & light mode";
CM_ SG_ 274 CF_AVN_CluRoadInfoGuide "Request to set CLU road info guidance";
CM_ SG_ 274 CF_AVN_CluUserSettingPeriod "Request to set CLU sservice period set by user";
CM_ SG_ 274 CF_AVN_CluFuelEconUnit_mi "Cluster setting status for cluster Fuel Economy Unit (mile)";
CM_ SG_ 274 CF_AVN_CluFuelEconUnit_km "Cluster setting status for cluster Fuel Economy unit (km)";
CM_ SG_ 274 CF_AVN_CluUserSettingDistance "Request to set CLU service distance set by user";
CM_ BO_ 685 "[PE] Periodic and On Event";
CM_ SG_ 685 HU_BLTN_CAM_Crc2Val "HU_BLTN_CAM_CyclicRedundancyCheck2Value";
CM_ SG_ 685 HU_BLTN_CAM_AlvCnt2Val "HU_BLTN_CAM_AliveCounter2Value";
CM_ SG_ 685 HU_WiFi_State "Send HU Wifi Connection State to Built-in CAM";
CM_ SG_ 685 HU_BLTN_CAM_UI_Mode "Display control of Built-in Cam UI mode. This Signal for Ethernet Type Built-in Cam.";
CM_ SG_ 685 HU_BLTN_CAM_Display "Display control of Built-in Cam UI mode. This Signal for CAN Type Built-in Cam.(with Standard 5th Wide AVNT)";
CM_ BO_ 138 "[EC] On Event and On Change";
CM_ SG_ 138 HU_GW_Crc1Val "HU_GW_CyclicRedundancyCheck1Value";
CM_ SG_ 138 HU_TgSoc_QcChg_Set "<For after OS/DE/SK3 EV>
Target SOC user setting value for fast charger(QC/DC).
- For EV only";
CM_ SG_ 138 HU_ICU_RearDefSet "Rear window defog control";
CM_ SG_ 138 HU_CDMOpenCmd "Command for CDM open/close";
CM_ SG_ 138 C_PreCrankReq "Command for B-CAN wake up signal
(Need to send this signal before other remote commands)";
CM_ SG_ 138 HU_GW_AlvCnt1Val "HU_GW_AliveCounter1Value";
CM_ SG_ 138 C_TeleAstSeatOpCmdIBOX "Command for Remote Seat Heat/Vent control (Passenger)";
CM_ SG_ 138 C_TeleDrvSeatOpCmdIBOX "Command for Remote Seat Heat/Vent control (Driver)";
CM_ SG_ 138 C_TeleRRSeatOpCmdIBOX "Command for Remote Seat Heat/Vent control (Rear Right)";
CM_ SG_ 138 C_TeleRLSeatOpCmdIBOX "Command for Remote Seat Heat/Vent control (Rear Left)";
CM_ SG_ 138 HU_StrgWhlHeatingSet_VR "Command for VR Heating Control (Steering Wheel 1/2step)";
CM_ SG_ 138 MODE_VCU_SET2 "Set the VCU setting in custom mode 2";
CM_ SG_ 138 HU_SafetyModeReq "Safety Mode On/Off Request";
CM_ SG_ 138 HU_DriveConfirmPopup "Drive Ready Confirm Signal";
CM_ SG_ 138 SWRC_Sensitivity_SET "SWRC_OpticalSwtich_Sensitivity_Setting";
CM_ SG_ 138 HU_ChgInCurrModSet "Charge current set signal";
CM_ SG_ 138 HU_EV_WinterMode "<For after OS/DE/SK3 EV/AE PE EV>

EV Battery temp. up setting on/off 
- setting signal : CR_Bms_WinterMode";
CM_ SG_ 138 HU_TgSoc_ScChg_Set "<For after OS/DE/SK3 EV>
Target SOC user setting value for slow charger(SC/AC).
- For EV only";
BA_DEF_ BO_  "GenMsgEVName" STRING ;
BA_DEF_ BU_  "NmAsrNodeIdentifier" HEX 0 255;
BA_DEF_ BU_  "NmAsrCanMsgReducedTime" INT 0 1000;
BA_DEF_  "NmAsrWaitBusSleepTime" INT 0 100000;
BA_DEF_  "NmAsrTimeoutTime" INT 0 100000;
BA_DEF_  "NmAsrRepeatMessageTime" INT 0 100000;
BA_DEF_  "NmAsrMessageCount" INT 0 255;
BA_DEF_  "NmAsrCanMsgCycleTime" INT 0 100;
BA_DEF_  "NmAsrBaseAddress" HEX 0 536870911;
BA_DEF_ BO_  "NmAsrMessage" ENUM  "No","Yes";
BA_DEF_ BO_  "DiagState" ENUM  "No","Yes";
BA_DEF_ BO_  "DiagRequest" ENUM  "No","Yes";
BA_DEF_ BO_  "TpMessage" ENUM  "No","Yes";
BA_DEF_ BO_  "UsrMsgIDSforwardDeviation" INT 0 100;
BA_DEF_ BO_  "UsrMsgIDSbackwardDeviation" INT 50 1000;
BA_DEF_  "BusType" STRING ;
BA_DEF_  "DBName" STRING ;
BA_DEF_  "Baudrate" INT 50000 1000000;
BA_DEF_  "BRS" INT 0 1;
BA_DEF_  "GenEnvVarEndingDsp" STRING ;
BA_DEF_  "GenEnvVarEndingSnd" STRING ;
BA_DEF_  "GenEnvVarPrefix" STRING ;
BA_DEF_  "GenNWMApBusSleep" STRING ;
BA_DEF_  "GenNWMApCanNormal" STRING ;
BA_DEF_  "GenNWMApCanOff" STRING ;
BA_DEF_  "GenNWMApCanOn" STRING ;
BA_DEF_  "GenNWMApCanSleep" STRING ;
BA_DEF_  "GenNWMApCanWakeUp" STRING ;
BA_DEF_  "GenNWMGotoMode_Awake" STRING ;
BA_DEF_  "GenNWMGotoMode_BusSleep" STRING ;
BA_DEF_  "GenNWMSleepTime" INT 1375 1650;
BA_DEF_  "GenNWMTalkNM" STRING ;
BA_DEF_  "Manufacturer" STRING ;
BA_DEF_  "NmBaseAddress" HEX 0 2047;
BA_DEF_  "NmMessageCount" INT 0 128;
BA_DEF_  "NmType" STRING ;
BA_DEF_  "SamplePointMax" INT 50 85;
BA_DEF_  "SamplePointMin" INT 55 85;
BA_DEF_  "SyncJumpWidthMax" INT 1 8;
BA_DEF_  "SyncJumpWidthMin" INT 1 4;
BA_DEF_  "VersionDay" INT 1 31;
BA_DEF_  "VersionMonth" INT 1 12;
BA_DEF_  "VersionNumber" INT 0 999999;
BA_DEF_  "VersionNumberInternal" INT 0 9999;
BA_DEF_  "VersionWeek" INT 1 53;
BA_DEF_  "VersionYear" INT 0 9999;
BA_DEF_ BU_  "NmStationAddress" HEX 0 255;
BA_DEF_ BU_  "NmNode" ENUM  "No","Yes";
BA_DEF_ BU_  "GenNodSleepTime" INT 1375 1650;
BA_DEF_ BU_  "ILUsed" ENUM  "No","Yes";
BA_DEF_ BU_  "NmCAN" INT 1 2;
BA_DEF_ BU_  "NodeLayerModules" STRING ;
BA_DEF_ BU_  "NWM_Knoten" ENUM  "No","Yes";
BA_DEF_ BO_  "GenMsgCycleTime" INT 0 2000;
BA_DEF_ BO_  "GenMsgStartDelayTime" INT 0 2000;
BA_DEF_ BO_  "GenMsgSendType" ENUM  "Cyclic","NoMsgSendType";
BA_DEF_ BO_  "GenMsgCycleTimeFast" INT 0 500;
BA_DEF_ BO_  "GenMsgDelayTime" INT 0 20;
BA_DEF_ BO_  "GenMsgILSupport" ENUM  "No","Yes";
BA_DEF_ BO_  "GenMsgNrOfRepetition" INT 0 3;
BA_DEF_ BO_  "VFrameFormat" ENUM  "StandardCAN","ExtendedCAN","reserved","reserved","reserved","reserved","reserved","reserved","reserved","reserved","reserved","reserved","reserved","reserved","StandardCAN_FD","ExtendedCAN_FD";
BA_DEF_ SG_  "UserSigValidity" ENUM  "B+","ACC","IG","IG1","IG2","IG3","IG1 or IG2","IG1 or IG3","Undef";
BA_DEF_ SG_  "TimeoutValue" STRING ;
BA_DEF_ SG_  "UsrSigPurpose" ENUM  "Undef","FN","DIAG","DIAG(Req)","DIAG(Res)","DIAG(Func)","DEV","CCP","NM","TP";
BA_DEF_ SG_  "GenSigStartValue" INT 0 1215752192;
BA_DEF_ SG_  "NetworkRequest" ENUM  "Yes","No";
BA_DEF_ SG_  "NetworkRequestHoldingTime" INT 0 65535;
BA_DEF_ SG_  "Description" STRING ;
BA_DEF_ SG_  "Version" STRING ;
BA_DEF_ SG_  "GenSigEnvVarType" ENUM  "Int","Float","Undef";
BA_DEF_ SG_  "GenSigSendType" ENUM  "Cyclic","OnWrite","OnWriteWithRepetition","OnChange","OnChangeWithRepetition","IfActive","IfActiveWithRepetition","NoSigSendType","OnChangeAndIfActive","OnChangeAndIfActiveWithRepetition";
BA_DEF_ SG_  "GwSigLatencyTime" INT 0 65536;
BA_DEF_ SG_  "GwSigMissingSourceType" ENUM  "Undef","OldValue","DefaultValue","InitialValue";
BA_DEF_ SG_  "NWM-WakeupAllowed" ENUM  "<n.a.>";
BA_DEF_ SG_  "RoutingFactor" INT 1 1215752192;
BA_DEF_  "Datarate" INT 1000000 8000000;
BA_DEF_ SG_  "SystemSignalLongSymbol" STRING ;
BA_DEF_REL_ BU_SG_REL_  "GenSigTimeoutTime" INT 0 7000;
BA_DEF_DEF_  "GenMsgEVName" "@Signame";
BA_DEF_DEF_  "NmAsrNodeIdentifier" 0;
BA_DEF_DEF_  "NmAsrCanMsgReducedTime" 1000;
BA_DEF_DEF_  "NmAsrWaitBusSleepTime" 1500;
BA_DEF_DEF_  "NmAsrTimeoutTime" 1000;
BA_DEF_DEF_  "NmAsrRepeatMessageTime" 1200;
BA_DEF_DEF_  "NmAsrMessageCount" 255;
BA_DEF_DEF_  "NmAsrCanMsgCycleTime" 100;
BA_DEF_DEF_  "NmAsrBaseAddress" 402391040;
BA_DEF_DEF_  "NmAsrMessage" "No";
BA_DEF_DEF_  "DiagState" "No";
BA_DEF_DEF_  "DiagRequest" "No";
BA_DEF_DEF_  "TpMessage" "No";
BA_DEF_DEF_  "UsrMsgIDSforwardDeviation" 10;
BA_DEF_DEF_  "UsrMsgIDSbackwardDeviation" 100;
BA_DEF_DEF_  "BusType" "CAN FD";
BA_DEF_DEF_  "DBName" "";
BA_DEF_DEF_  "Baudrate" 500000;
BA_DEF_DEF_  "BRS" 1;
BA_DEF_DEF_  "GenEnvVarEndingDsp" "Dsp_";
BA_DEF_DEF_  "GenEnvVarEndingSnd" "_";
BA_DEF_DEF_  "GenEnvVarPrefix" "Env";
BA_DEF_DEF_  "GenNWMApBusSleep" "AppNmCanBusSleep()";
BA_DEF_DEF_  "GenNWMApCanNormal" "AppNmCanNormal()";
BA_DEF_DEF_  "GenNWMApCanOff" "ApplCanOffline()";
BA_DEF_DEF_  "GenNWMApCanOn" "ApplCanOnline()";
BA_DEF_DEF_  "GenNWMApCanSleep" "ApplNmCanSleep()";
BA_DEF_DEF_  "GenNWMApCanWakeUp" "ApplCanWakeUp()";
BA_DEF_DEF_  "GenNWMGotoMode_Awake" "GotoMode_Awake()";
BA_DEF_DEF_  "GenNWMGotoMode_BusSleep" "GotoMode_BusSleep()";
BA_DEF_DEF_  "GenNWMSleepTime" 1500;
BA_DEF_DEF_  "GenNWMTalkNM" "TalkNM()";
BA_DEF_DEF_  "Manufacturer" "HMC";
BA_DEF_DEF_  "NmBaseAddress" 1280;
BA_DEF_DEF_  "NmMessageCount" 128;
BA_DEF_DEF_  "NmType" "AsrNm";
BA_DEF_DEF_  "SamplePointMax" 80;
BA_DEF_DEF_  "SamplePointMin" 80;
BA_DEF_DEF_  "SyncJumpWidthMax" 3;
BA_DEF_DEF_  "SyncJumpWidthMin" 2;
BA_DEF_DEF_  "VersionDay" 1;
BA_DEF_DEF_  "VersionMonth" 1;
BA_DEF_DEF_  "VersionNumber" 0;
BA_DEF_DEF_  "VersionNumberInternal" 0;
BA_DEF_DEF_  "VersionWeek" 1;
BA_DEF_DEF_  "VersionYear" 0;
BA_DEF_DEF_  "NmStationAddress" 0;
BA_DEF_DEF_  "NmNode" "No";
BA_DEF_DEF_  "GenNodSleepTime" 1500;
BA_DEF_DEF_  "ILUsed" "Yes";
BA_DEF_DEF_  "NmCAN" 1;
BA_DEF_DEF_  "NodeLayerModules" "AsrNM33.DLL,CANoeILNLVector.DLL";
BA_DEF_DEF_  "NWM_Knoten" "Yes";
BA_DEF_DEF_  "GenMsgCycleTime" 200;
BA_DEF_DEF_  "GenMsgStartDelayTime" 0;
BA_DEF_DEF_  "GenMsgSendType" "NoMsgSendType";
BA_DEF_DEF_  "GenMsgCycleTimeFast" 40;
BA_DEF_DEF_  "GenMsgDelayTime" 20;
BA_DEF_DEF_  "GenMsgILSupport" "Yes";
BA_DEF_DEF_  "GenMsgNrOfRepetition" 3;
BA_DEF_DEF_  "VFrameFormat" "StandardCAN";
BA_DEF_DEF_  "UserSigValidity" "IG";
BA_DEF_DEF_  "TimeoutValue" "";
BA_DEF_DEF_  "UsrSigPurpose" "FN";
BA_DEF_DEF_  "GenSigStartValue" 0;
BA_DEF_DEF_  "NetworkRequest" "No";
BA_DEF_DEF_  "NetworkRequestHoldingTime" 0;
BA_DEF_DEF_  "Description" "";
BA_DEF_DEF_  "Version" "";
BA_DEF_DEF_  "GenSigEnvVarType" "Undef";
BA_DEF_DEF_  "GenSigSendType" "NoSigSendType";
BA_DEF_DEF_  "GwSigLatencyTime" 40;
BA_DEF_DEF_  "GwSigMissingSourceType" "Undef";
BA_DEF_DEF_  "NWM-WakeupAllowed" "<n.a.>";
BA_DEF_DEF_  "RoutingFactor" 1;
BA_DEF_DEF_  "Datarate" 1000000;
BA_DEF_DEF_REL_ "GenSigTimeoutTime" 500;
BA_DEF_DEF_  "SystemSignalLongSymbol" "";
BA_ "VersionYear" 1;
BA_ "VersionNumber" 250801;
BA_ "DBName" "FD_B2";
BA_ "NmStationAddress" BU_ SHVU_CCS_FD 101;
BA_ "NmNode" BU_ SHVU_CCS_FD 1;
BA_ "NmAsrNodeIdentifier" BU_ SHVU_CCS_FD 101;
BA_ "NmStationAddress" BU_ ARS_FD 138;
BA_ "NmNode" BU_ ARS_FD 1;
BA_ "NmAsrNodeIdentifier" BU_ ARS_FD 138;
BA_ "NmStationAddress" BU_ WPC_FD 158;
BA_ "NmNode" BU_ WPC_FD 1;
BA_ "NmAsrNodeIdentifier" BU_ WPC_FD 158;
BA_ "NmStationAddress" BU_ WPC2_FD 149;
BA_ "NmNode" BU_ WPC2_FD 1;
BA_ "NmAsrNodeIdentifier" BU_ WPC2_FD 149;
BA_ "NmStationAddress" BU_ SCM_FD 135;
BA_ "NmNode" BU_ SCM_FD 1;
BA_ "NmAsrNodeIdentifier" BU_ SCM_FD 135;
BA_ "NmStationAddress" BU_ SHVU_FRNT_FD 170;
BA_ "NmNode" BU_ SHVU_FRNT_FD 1;
BA_ "NmAsrNodeIdentifier" BU_ SHVU_FRNT_FD 170;
BA_ "NmStationAddress" BU_ FLLR_FD 62;
BA_ "NmNode" BU_ FLLR_FD 1;
BA_ "NmAsrNodeIdentifier" BU_ FLLR_FD 62;
BA_ "NmStationAddress" BU_ GW_SAU_DRV_FD 217;
BA_ "NmNode" BU_ GW_SAU_DRV_FD 1;
BA_ "NmAsrNodeIdentifier" BU_ GW_SAU_DRV_FD 217;
BA_ "NmStationAddress" BU_ ATS_FD 208;
BA_ "NmNode" BU_ ATS_FD 1;
BA_ "NmAsrNodeIdentifier" BU_ ATS_FD 208;
BA_ "NmStationAddress" BU_ PSB_FD 193;
BA_ "NmNode" BU_ PSB_FD 1;
BA_ "NmAsrNodeIdentifier" BU_ PSB_FD 193;
BA_ "NmStationAddress" BU_ GW_PSU_RR_FD 157;
BA_ "NmNode" BU_ GW_PSU_RR_FD 1;
BA_ "NmAsrNodeIdentifier" BU_ GW_PSU_RR_FD 157;
BA_ "NmStationAddress" BU_ SHVU_RL_FD 180;
BA_ "NmNode" BU_ SHVU_RL_FD 1;
BA_ "NmAsrNodeIdentifier" BU_ SHVU_RL_FD 180;
BA_ "NmStationAddress" BU_ RWPC_FD 159;
BA_ "NmNode" BU_ RWPC_FD 1;
BA_ "NmAsrNodeIdentifier" BU_ RWPC_FD 159;
BA_ "NmStationAddress" BU_ CGW_CCU 112;
BA_ "NmNode" BU_ CGW_CCU 1;
BA_ "NmAsrNodeIdentifier" BU_ CGW_CCU 112;
BA_ "NmStationAddress" BU_ OHCL_FD 212;
BA_ "NmNode" BU_ OHCL_FD 1;
BA_ "NmAsrNodeIdentifier" BU_ OHCL_FD 212;
BA_ "NmStationAddress" BU_ SHVU_REAR_FD 171;
BA_ "NmNode" BU_ SHVU_REAR_FD 1;
BA_ "NmAsrNodeIdentifier" BU_ SHVU_REAR_FD 171;
BA_ "NmStationAddress" BU_ BLTN_CAM_FD 200;
BA_ "NmNode" BU_ BLTN_CAM_FD 1;
BA_ "NmAsrNodeIdentifier" BU_ BLTN_CAM_FD 200;
BA_ "NmStationAddress" BU_ GW_PSU_DRV_FD 184;
BA_ "NmNode" BU_ GW_PSU_DRV_FD 1;
BA_ "NmAsrNodeIdentifier" BU_ GW_PSU_DRV_FD 184;
BA_ "NmStationAddress" BU_ FCS_FD 161;
BA_ "NmNode" BU_ FCS_FD 1;
BA_ "NmAsrNodeIdentifier" BU_ FCS_FD 161;
BA_ "NmStationAddress" BU_ GW_PSU_AST_FD 177;
BA_ "NmNode" BU_ GW_PSU_AST_FD 1;
BA_ "NmAsrNodeIdentifier" BU_ GW_PSU_AST_FD 177;
BA_ "NmStationAddress" BU_ GW_PSU_3RD_FD 173;
BA_ "NmNode" BU_ GW_PSU_3RD_FD 1;
BA_ "NmAsrNodeIdentifier" BU_ GW_PSU_3RD_FD 173;
BA_ "NmStationAddress" BU_ RCS_FD 198;
BA_ "NmNode" BU_ RCS_FD 1;
BA_ "NmAsrNodeIdentifier" BU_ RCS_FD 198;
BA_ "NmStationAddress" BU_ GW_PSU_RL_FD 156;
BA_ "NmNode" BU_ GW_PSU_RL_FD 1;
BA_ "NmAsrNodeIdentifier" BU_ GW_PSU_RL_FD 156;
BA_ "NmStationAddress" BU_ SHVU_3RD_FD 82;
BA_ "NmNode" BU_ SHVU_3RD_FD 1;
BA_ "NmAsrNodeIdentifier" BU_ SHVU_3RD_FD 82;
BA_ "NmStationAddress" BU_ SHVU_RR_FD 181;
BA_ "NmNode" BU_ SHVU_RR_FD 1;
BA_ "NmAsrNodeIdentifier" BU_ SHVU_RR_FD 181;
BA_ "NmStationAddress" BU_ RCM_FD 189;
BA_ "NmNode" BU_ RCM_FD 1;
BA_ "NmAsrNodeIdentifier" BU_ RCM_FD 189;
BA_ "NmStationAddress" BU_ DCM_FD 41;
BA_ "NmNode" BU_ DCM_FD 1;
BA_ "NmAsrNodeIdentifier" BU_ DCM_FD 41;
BA_ "NmStationAddress" BU_ SGU_FD 190;
BA_ "NmNode" BU_ SGU_FD 1;
BA_ "NmAsrNodeIdentifier" BU_ SGU_FD 190;
BA_ "GenMsgSendType" BO_ 977 0;
BA_ "VFrameFormat" BO_ 977 14;
BA_ "VFrameFormat" BO_ 1941 14;
BA_ "DiagState" BO_ 2015 1;
BA_ "TpMessage" BO_ 2015 1;
BA_ "GenMsgCycleTime" BO_ 2015 0;
BA_ "GenMsgCycleTimeFast" BO_ 2015 0;
BA_ "GenMsgILSupport" BO_ 2015 0;
BA_ "VFrameFormat" BO_ 2015 14;
BA_ "DiagRequest" BO_ 1949 1;
BA_ "TpMessage" BO_ 1949 1;
BA_ "GenMsgCycleTime" BO_ 1949 0;
BA_ "GenMsgCycleTimeFast" BO_ 1949 0;
BA_ "GenMsgILSupport" BO_ 1949 0;
BA_ "GenMsgNrOfRepetition" BO_ 1949 0;
BA_ "VFrameFormat" BO_ 1949 14;
BA_ "GenMsgSendType" BO_ 956 0;
BA_ "VFrameFormat" BO_ 956 14;
BA_ "GenMsgSendType" BO_ 957 0;
BA_ "GenMsgStartDelayTime" BO_ 957 10;
BA_ "VFrameFormat" BO_ 957 14;
BA_ "GenMsgSendType" BO_ 686 0;
BA_ "GenMsgStartDelayTime" BO_ 686 30;
BA_ "VFrameFormat" BO_ 686 14;
BA_ "GenMsgCycleTime" BO_ 274 0;
BA_ "VFrameFormat" BO_ 274 14;
BA_ "GenMsgSendType" BO_ 685 0;
BA_ "GenMsgStartDelayTime" BO_ 685 30;
BA_ "VFrameFormat" BO_ 685 14;
BA_ "GenMsgCycleTime" BO_ 138 0;
BA_ "VFrameFormat" BO_ 138 14;
BA_ "GenSigSendType" SG_ 977 BCM_Ign2InSta_Copy_0 4;
BA_ "NetworkRequestHoldingTime" SG_ 977 BCM_Ign2InSta_Copy_0 5000;
BA_ "NetworkRequest" SG_ 977 BCM_Ign2InSta_Copy_0 0;
BA_ "UserSigValidity" SG_ 977 BCM_Ign2InSta_Copy_0 0;
BA_ "GenSigSendType" SG_ 977 BCM_Ign1InSta_Copy_0 4;
BA_ "NetworkRequestHoldingTime" SG_ 977 BCM_Ign1InSta_Copy_0 5000;
BA_ "NetworkRequest" SG_ 977 BCM_Ign1InSta_Copy_0 0;
BA_ "UserSigValidity" SG_ 977 BCM_Ign1InSta_Copy_0 0;
BA_ "GenSigSendType" SG_ 977 BCM_AccInSta_Copy_0 4;
BA_ "NetworkRequestHoldingTime" SG_ 977 BCM_AccInSta_Copy_0 5000;
BA_ "NetworkRequest" SG_ 977 BCM_AccInSta_Copy_0 0;
BA_ "UserSigValidity" SG_ 977 BCM_AccInSta_Copy_0 0;
BA_ "GenSigSendType" SG_ 977 BCM_KeyInSta_Copy_0 4;
BA_ "NetworkRequestHoldingTime" SG_ 977 BCM_KeyInSta_Copy_0 5000;
BA_ "NetworkRequest" SG_ 977 BCM_KeyInSta_Copy_0 0;
BA_ "UserSigValidity" SG_ 977 BCM_KeyInSta_Copy_0 0;
BA_ "UserSigValidity" SG_ 2015 GST_ALL_Byte7 0;
BA_ "UsrSigPurpose" SG_ 2015 GST_ALL_Byte7 5;
BA_ "NetworkRequest" SG_ 2015 GST_ALL_Byte7 0;
BA_ "NetworkRequestHoldingTime" SG_ 2015 GST_ALL_Byte7 5000;
BA_ "Description" SG_ 2015 GST_ALL_Byte7 "TP Index : 0";
BA_ "Version" SG_ 2015 GST_ALL_Byte7 "22.06.01";
BA_ "UserSigValidity" SG_ 2015 GST_ALL_Byte6 0;
BA_ "UsrSigPurpose" SG_ 2015 GST_ALL_Byte6 5;
BA_ "NetworkRequest" SG_ 2015 GST_ALL_Byte6 0;
BA_ "NetworkRequestHoldingTime" SG_ 2015 GST_ALL_Byte6 5000;
BA_ "Description" SG_ 2015 GST_ALL_Byte6 "TP Index : 0";
BA_ "Version" SG_ 2015 GST_ALL_Byte6 "22.06.01";
BA_ "UserSigValidity" SG_ 2015 GST_ALL_Byte5 0;
BA_ "UsrSigPurpose" SG_ 2015 GST_ALL_Byte5 5;
BA_ "NetworkRequest" SG_ 2015 GST_ALL_Byte5 0;
BA_ "NetworkRequestHoldingTime" SG_ 2015 GST_ALL_Byte5 5000;
BA_ "Description" SG_ 2015 GST_ALL_Byte5 "TP Index : 0";
BA_ "Version" SG_ 2015 GST_ALL_Byte5 "22.06.01";
BA_ "UserSigValidity" SG_ 2015 GST_ALL_Byte4 0;
BA_ "UsrSigPurpose" SG_ 2015 GST_ALL_Byte4 5;
BA_ "NetworkRequest" SG_ 2015 GST_ALL_Byte4 0;
BA_ "NetworkRequestHoldingTime" SG_ 2015 GST_ALL_Byte4 5000;
BA_ "Description" SG_ 2015 GST_ALL_Byte4 "TP Index : 0";
BA_ "Version" SG_ 2015 GST_ALL_Byte4 "22.06.01";
BA_ "UserSigValidity" SG_ 2015 GST_ALL_Byte3 0;
BA_ "UsrSigPurpose" SG_ 2015 GST_ALL_Byte3 5;
BA_ "NetworkRequest" SG_ 2015 GST_ALL_Byte3 0;
BA_ "NetworkRequestHoldingTime" SG_ 2015 GST_ALL_Byte3 5000;
BA_ "Description" SG_ 2015 GST_ALL_Byte3 "TP Index : 0";
BA_ "Version" SG_ 2015 GST_ALL_Byte3 "22.06.01";
BA_ "UserSigValidity" SG_ 2015 GST_ALL_Byte2 0;
BA_ "UsrSigPurpose" SG_ 2015 GST_ALL_Byte2 5;
BA_ "NetworkRequest" SG_ 2015 GST_ALL_Byte2 0;
BA_ "NetworkRequestHoldingTime" SG_ 2015 GST_ALL_Byte2 5000;
BA_ "Description" SG_ 2015 GST_ALL_Byte2 "TP Index : 0";
BA_ "Version" SG_ 2015 GST_ALL_Byte2 "22.06.01";
BA_ "UserSigValidity" SG_ 2015 GST_ALL_Byte1 0;
BA_ "UsrSigPurpose" SG_ 2015 GST_ALL_Byte1 5;
BA_ "NetworkRequest" SG_ 2015 GST_ALL_Byte1 0;
BA_ "NetworkRequestHoldingTime" SG_ 2015 GST_ALL_Byte1 5000;
BA_ "Description" SG_ 2015 GST_ALL_Byte1 "TP Index : 0";
BA_ "Version" SG_ 2015 GST_ALL_Byte1 "22.06.01";
BA_ "UserSigValidity" SG_ 2015 GST_ALL_Byte0 0;
BA_ "UsrSigPurpose" SG_ 2015 GST_ALL_Byte0 5;
BA_ "NetworkRequest" SG_ 2015 GST_ALL_Byte0 0;
BA_ "NetworkRequestHoldingTime" SG_ 2015 GST_ALL_Byte0 5000;
BA_ "Description" SG_ 2015 GST_ALL_Byte0 "TP Index : 0";
BA_ "Version" SG_ 2015 GST_ALL_Byte0 "22.06.01";
BA_ "Description" SG_ 956 BLTN_CAM_FD_Crc2Val "The data area for CRC calculation is based on the data length (DLC) of the message DB.

The CRC shall be calculated over the entire data block (excluding the CRC bytes) including the user data, alive counter and Data ID



- CRC Polynomial (0x1021) , Ini";
BA_ "GenSigSendType" SG_ 956 BLTN_CAM_FD_Crc2Val 4;
BA_ "GenSigStartValue" SG_ 956 BLTN_CAM_FD_Crc2Val 65535;
BA_ "UserSigValidity" SG_ 956 BLTN_CAM_FD_Crc2Val 3;
BA_ "Version" SG_ 956 BLTN_CAM_FD_Crc2Val "22.11.04";
BA_ "Description" SG_ 956 BLTN_CAM_Set_EV_BfrTime "Driving Event Time Setting - Before, Resolution : sec";
BA_ "GenSigSendType" SG_ 956 BLTN_CAM_Set_EV_BfrTime 4;
BA_ "UserSigValidity" SG_ 956 BLTN_CAM_Set_EV_BfrTime 0;
BA_ "Version" SG_ 956 BLTN_CAM_Set_EV_BfrTime "21.05.02";
BA_ "Description" SG_ 956 BLTN_CAM_Set_EV_AftTime "Driving Event Time Setting - After, Resolution : sec";
BA_ "GenSigSendType" SG_ 956 BLTN_CAM_Set_EV_AftTime 4;
BA_ "UserSigValidity" SG_ 956 BLTN_CAM_Set_EV_AftTime 0;
BA_ "Version" SG_ 956 BLTN_CAM_Set_EV_AftTime "21.05.02";
BA_ "Description" SG_ 956 BLTN_CAM_Set_Drv_TML_Int "Record Set of Time-lapse Interval, Resolution : sec";
BA_ "GenSigSendType" SG_ 956 BLTN_CAM_Set_Drv_TML_Int 4;
BA_ "UserSigValidity" SG_ 956 BLTN_CAM_Set_Drv_TML_Int 0;
BA_ "Version" SG_ 956 BLTN_CAM_Set_Drv_TML_Int "21.05.02";
BA_ "Description" SG_ 956 BLTN_CAM_SenSet_DEV "Set of Event  Detection Sensitivity of Driving Mode";
BA_ "GenSigSendType" SG_ 956 BLTN_CAM_SenSet_DEV 4;
BA_ "UserSigValidity" SG_ 956 BLTN_CAM_SenSet_DEV 0;
BA_ "Version" SG_ 956 BLTN_CAM_SenSet_DEV "21.05.02";
BA_ "Description" SG_ 956 BLTN_CAM_SenSet_PEV "Set of Event  Detection Sensitivity of Parking Mode";
BA_ "GenSigSendType" SG_ 956 BLTN_CAM_SenSet_PEV 4;
BA_ "UserSigValidity" SG_ 956 BLTN_CAM_SenSet_PEV 0;
BA_ "Version" SG_ 956 BLTN_CAM_SenSet_PEV "21.05.02";
BA_ "Description" SG_ 956 BLTN_CAM_Set_FR_Ver_Pos "Front Camera Vertical position setting value.";
BA_ "GenSigSendType" SG_ 956 BLTN_CAM_Set_FR_Ver_Pos 4;
BA_ "UserSigValidity" SG_ 956 BLTN_CAM_Set_FR_Ver_Pos 0;
BA_ "Version" SG_ 956 BLTN_CAM_Set_FR_Ver_Pos "22.07.06";
BA_ "Description" SG_ 956 BLTN_CAM_Set_RR_Ver_Pos "Rear Camera Vertical position setting value.";
BA_ "GenSigSendType" SG_ 956 BLTN_CAM_Set_RR_Ver_Pos 4;
BA_ "UserSigValidity" SG_ 956 BLTN_CAM_Set_RR_Ver_Pos 0;
BA_ "Version" SG_ 956 BLTN_CAM_Set_RR_Ver_Pos "22.07.06";
BA_ "Description" SG_ 956 BLTN_CAM_Set_PEV_AppNoti "Parked Event notification to Connectivity Phone App. On/Off";
BA_ "GenSigSendType" SG_ 956 BLTN_CAM_Set_PEV_AppNoti 4;
BA_ "UserSigValidity" SG_ 956 BLTN_CAM_Set_PEV_AppNoti 0;
BA_ "Version" SG_ 956 BLTN_CAM_Set_PEV_AppNoti "21.05.02";
BA_ "Description" SG_ 956 BLTN_CAM_Set_WiFi_AutoOn "Wifi On/Off User setting";
BA_ "GenSigSendType" SG_ 956 BLTN_CAM_Set_WiFi_AutoOn 4;
BA_ "UserSigValidity" SG_ 956 BLTN_CAM_Set_WiFi_AutoOn 0;
BA_ "Version" SG_ 956 BLTN_CAM_Set_WiFi_AutoOn "21.05.02";
BA_ "Description" SG_ 956 BLTN_CAM_StrgPropSet "Propotion of built-in Cam SD card Propotion set of the Recording Categories";
BA_ "GenSigSendType" SG_ 956 BLTN_CAM_StrgPropSet 4;
BA_ "UserSigValidity" SG_ 956 BLTN_CAM_StrgPropSet 0;
BA_ "Version" SG_ 956 BLTN_CAM_StrgPropSet "21.05.02";
BA_ "Description" SG_ 956 BLTN_CAM_File_DEL_CPY_Op_State "Bulil in Cam Fily copy and delete operating state.";
BA_ "GenSigSendType" SG_ 956 BLTN_CAM_File_DEL_CPY_Op_State 4;
BA_ "UserSigValidity" SG_ 956 BLTN_CAM_File_DEL_CPY_Op_State 0;
BA_ "Version" SG_ 956 BLTN_CAM_File_DEL_CPY_Op_State "21.05.02";
BA_ "Description" SG_ 956 BLTN_CAM_File_DEL_CPY_NumTot "Number of Copied or Deleted files.";
BA_ "GenSigSendType" SG_ 956 BLTN_CAM_File_DEL_CPY_NumTot 4;
BA_ "UserSigValidity" SG_ 956 BLTN_CAM_File_DEL_CPY_NumTot 0;
BA_ "Version" SG_ 956 BLTN_CAM_File_DEL_CPY_NumTot "21.05.02";
BA_ "Description" SG_ 956 BLTN_CAM_FD_AlvCnt2Val "For the first transmission request for a data element the counter shall be initialized with 0 and shall be incremented by 1 for every subsequent send request. 

When the counter reaches the maximum value(0xFF), then it shall restart with 0 for the next s";
BA_ "GenSigSendType" SG_ 956 BLTN_CAM_FD_AlvCnt2Val 4;
BA_ "UserSigValidity" SG_ 956 BLTN_CAM_FD_AlvCnt2Val 3;
BA_ "Version" SG_ 956 BLTN_CAM_FD_AlvCnt2Val "22.11.04";
BA_ "Description" SG_ 956 BLTN_CAM_File_DEL_CPYed_Num "Total number of the copy or delete file.";
BA_ "GenSigSendType" SG_ 956 BLTN_CAM_File_DEL_CPYed_Num 4;
BA_ "UserSigValidity" SG_ 956 BLTN_CAM_File_DEL_CPYed_Num 0;
BA_ "Version" SG_ 956 BLTN_CAM_File_DEL_CPYed_Num "21.05.02";
BA_ "Description" SG_ 956 VAPI_BltnCamInsideSwEnable_Get "Built-in Cam Manual Button Status";
BA_ "GenSigSendType" SG_ 956 VAPI_BltnCamInsideSwEnable_Get 4;
BA_ "UserSigValidity" SG_ 956 VAPI_BltnCamInsideSwEnable_Get 0;
BA_ "Version" SG_ 956 VAPI_BltnCamInsideSwEnable_Get "25.07.04";
BA_ "Description" SG_ 956 BLTN_CAM_Set_PMD "Parked Motion Detection Record Mode On/Off Set";
BA_ "GenSigSendType" SG_ 956 BLTN_CAM_Set_PMD 4;
BA_ "UserSigValidity" SG_ 956 BLTN_CAM_Set_PMD 0;
BA_ "Version" SG_ 956 BLTN_CAM_Set_PMD "24.01.05";
BA_ "Description" SG_ 956 BLTN_CAM_Set_PMDEV "Parked Motion Detection Event Record On/Off Set";
BA_ "GenSigSendType" SG_ 956 BLTN_CAM_Set_PMDEV 4;
BA_ "UserSigValidity" SG_ 956 BLTN_CAM_Set_PMDEV 0;
BA_ "Version" SG_ 956 BLTN_CAM_Set_PMDEV "24.01.05";
BA_ "Description" SG_ 956 BLTN_CAM_RanSet_PMDR "Set of Range level of Parked Motion Detection Record Mode";
BA_ "GenSigSendType" SG_ 956 BLTN_CAM_RanSet_PMDR 4;
BA_ "UserSigValidity" SG_ 956 BLTN_CAM_RanSet_PMDR 0;
BA_ "Version" SG_ 956 BLTN_CAM_RanSet_PMDR "24.01.05";
BA_ "Description" SG_ 956 BLTN_CAM_MaxRanSet_PMDR "Set Level Range of Parked Motion Detection Record Mode";
BA_ "GenSigSendType" SG_ 956 BLTN_CAM_MaxRanSet_PMDR 4;
BA_ "UserSigValidity" SG_ 956 BLTN_CAM_MaxRanSet_PMDR 0;
BA_ "Version" SG_ 956 BLTN_CAM_MaxRanSet_PMDR "24.01.05";
BA_ "Description" SG_ 956 BLTN_CAM_Set_PMDTime "Set the hours of Parked Motion Detection Mode";
BA_ "GenSigSendType" SG_ 956 BLTN_CAM_Set_PMDTime 4;
BA_ "GenSigStartValue" SG_ 956 BLTN_CAM_Set_PMDTime 1;
BA_ "UserSigValidity" SG_ 956 BLTN_CAM_Set_PMDTime 0;
BA_ "Version" SG_ 956 BLTN_CAM_Set_PMDTime "24.01.05";
BA_ "Description" SG_ 956 BLTN_CAM_Set_BPR_TM "Built-inCAM Performance Recorder Track Mode Set";
BA_ "GenSigSendType" SG_ 956 BLTN_CAM_Set_BPR_TM 4;
BA_ "UserSigValidity" SG_ 956 BLTN_CAM_Set_BPR_TM 0;
BA_ "Version" SG_ 956 BLTN_CAM_Set_BPR_TM "24.04.03";
BA_ "Description" SG_ 956 BLTN_CAM_Set_BPR_RE "Built-inCAM Performance Recorder Resolution Set";
BA_ "GenSigSendType" SG_ 956 BLTN_CAM_Set_BPR_RE 4;
BA_ "UserSigValidity" SG_ 956 BLTN_CAM_Set_BPR_RE 0;
BA_ "Version" SG_ 956 BLTN_CAM_Set_BPR_RE "24.04.03";
BA_ "Description" SG_ 956 BLTN_CAM_BPR_SndRec_Set "Built-inCAM Performance Recorder Sound Recording Set";
BA_ "GenSigSendType" SG_ 956 BLTN_CAM_BPR_SndRec_Set 4;
BA_ "UserSigValidity" SG_ 956 BLTN_CAM_BPR_SndRec_Set 0;
BA_ "Version" SG_ 956 BLTN_CAM_BPR_SndRec_Set "24.04.03";
BA_ "Description" SG_ 956 BLTN_CAM_BPR_AutRec_Set "Built-inCAM Performance Recorder Automatic Record Set";
BA_ "GenSigSendType" SG_ 956 BLTN_CAM_BPR_AutRec_Set 4;
BA_ "UserSigValidity" SG_ 956 BLTN_CAM_BPR_AutRec_Set 0;
BA_ "Version" SG_ 956 BLTN_CAM_BPR_AutRec_Set "24.04.03";
BA_ "Description" SG_ 956 BLTN_CAM_RecSet_LPE "Setting Information(On/Off) of Low Power Recording Mode";
BA_ "GenSigSendType" SG_ 956 BLTN_CAM_RecSet_LPE 4;
BA_ "UserSigValidity" SG_ 956 BLTN_CAM_RecSet_LPE 0;
BA_ "Version" SG_ 956 BLTN_CAM_RecSet_LPE "25.01.00";
BA_ "Description" SG_ 956 BLTN_CAM_Set_Distort_Correct "Setting Information(On/Off) of Side view Distortion Calibration";
BA_ "GenSigSendType" SG_ 956 BLTN_CAM_Set_Distort_Correct 4;
BA_ "UserSigValidity" SG_ 956 BLTN_CAM_Set_Distort_Correct 0;
BA_ "Version" SG_ 956 BLTN_CAM_Set_Distort_Correct "25.01.00";
BA_ "Description" SG_ 956 BLTN_CAM_Set_Pollution_Warn "Setting Information(On/Off) of CAM Lens Pollution Warning";
BA_ "GenSigSendType" SG_ 956 BLTN_CAM_Set_Pollution_Warn 4;
BA_ "UserSigValidity" SG_ 956 BLTN_CAM_Set_Pollution_Warn 0;
BA_ "Version" SG_ 956 BLTN_CAM_Set_Pollution_Warn "25.01.00";
BA_ "Description" SG_ 956 BLTN_CAM_Set_Crash_Pos "Setting Information(On/Off) of Crashing Direction Display";
BA_ "GenSigSendType" SG_ 956 BLTN_CAM_Set_Crash_Pos 4;
BA_ "UserSigValidity" SG_ 956 BLTN_CAM_Set_Crash_Pos 0;
BA_ "Version" SG_ 956 BLTN_CAM_Set_Crash_Pos "25.01.00";
BA_ "Description" SG_ 956 BLTN_CAM_Stm_all "Setting Information(On/Off) of Stamping";
BA_ "GenSigSendType" SG_ 956 BLTN_CAM_Stm_all 4;
BA_ "UserSigValidity" SG_ 956 BLTN_CAM_Stm_all 0;
BA_ "Version" SG_ 956 BLTN_CAM_Stm_all "25.01.00";
BA_ "Description" SG_ 956 BLTN_CAM_RecSet_OWD "Record On/Off Set of On While Driving";
BA_ "GenSigSendType" SG_ 956 BLTN_CAM_RecSet_OWD 4;
BA_ "UserSigValidity" SG_ 956 BLTN_CAM_RecSet_OWD 0;
BA_ "Version" SG_ 956 BLTN_CAM_RecSet_OWD "21.05.02";
BA_ "Description" SG_ 956 BLTN_CAM_RecSet_DEV "Record On/Off Set of Driving Event";
BA_ "GenSigSendType" SG_ 956 BLTN_CAM_RecSet_DEV 4;
BA_ "UserSigValidity" SG_ 956 BLTN_CAM_RecSet_DEV 0;
BA_ "Version" SG_ 956 BLTN_CAM_RecSet_DEV "21.05.02";
BA_ "Description" SG_ 956 BLTN_CAM_RecSet_OWP "Record On/Off Set of On While Parked, 0x0(Default) : Parking recording function not supported";
BA_ "GenSigSendType" SG_ 956 BLTN_CAM_RecSet_OWP 4;
BA_ "UserSigValidity" SG_ 956 BLTN_CAM_RecSet_OWP 0;
BA_ "Version" SG_ 956 BLTN_CAM_RecSet_OWP "21.05.02";
BA_ "Description" SG_ 956 BLTN_CAM_RecSet_PEV "Record Set of Parked Event, 0x0(Default) : Parking recording function not supported";
BA_ "GenSigSendType" SG_ 956 BLTN_CAM_RecSet_PEV 4;
BA_ "UserSigValidity" SG_ 956 BLTN_CAM_RecSet_PEV 0;
BA_ "Version" SG_ 956 BLTN_CAM_RecSet_PEV "21.05.02";
BA_ "Description" SG_ 956 BLTN_CAM_AudRec_Set "Audio Record On/Off Set";
BA_ "GenSigSendType" SG_ 956 BLTN_CAM_AudRec_Set 4;
BA_ "UserSigValidity" SG_ 956 BLTN_CAM_AudRec_Set 0;
BA_ "Version" SG_ 956 BLTN_CAM_AudRec_Set "21.05.02";
BA_ "Description" SG_ 956 BLTN_CAM_Set_Tim_Stm "Record Set of Date and Time Stamp";
BA_ "GenSigSendType" SG_ 956 BLTN_CAM_Set_Tim_Stm 4;
BA_ "UserSigValidity" SG_ 956 BLTN_CAM_Set_Tim_Stm 0;
BA_ "Version" SG_ 956 BLTN_CAM_Set_Tim_Stm "21.05.02";
BA_ "Description" SG_ 956 BLTN_CAM_Set_Spd_Stm "Record Set of Speed Stamp";
BA_ "GenSigSendType" SG_ 956 BLTN_CAM_Set_Spd_Stm 4;
BA_ "UserSigValidity" SG_ 956 BLTN_CAM_Set_Spd_Stm 0;
BA_ "Version" SG_ 956 BLTN_CAM_Set_Spd_Stm "21.11.07";
BA_ "Description" SG_ 956 BLTN_CAM_Set_Locatn_Stm "Record Set of Location Stamp";
BA_ "GenSigSendType" SG_ 956 BLTN_CAM_Set_Locatn_Stm 4;
BA_ "UserSigValidity" SG_ 956 BLTN_CAM_Set_Locatn_Stm 0;
BA_ "Version" SG_ 956 BLTN_CAM_Set_Locatn_Stm "21.05.02";
BA_ "Description" SG_ 956 BLTN_CAM_Set_TrnSig_Stm "Record Set of Turn Signal Stamp";
BA_ "GenSigSendType" SG_ 956 BLTN_CAM_Set_TrnSig_Stm 4;
BA_ "UserSigValidity" SG_ 956 BLTN_CAM_Set_TrnSig_Stm 0;
BA_ "Version" SG_ 956 BLTN_CAM_Set_TrnSig_Stm "21.05.02";
BA_ "Description" SG_ 956 BLTN_CAM_Set_AclBrk_Stm "Record Set of Accelerator Brake Stamp";
BA_ "GenSigSendType" SG_ 956 BLTN_CAM_Set_AclBrk_Stm 4;
BA_ "UserSigValidity" SG_ 956 BLTN_CAM_Set_AclBrk_Stm 0;
BA_ "Version" SG_ 956 BLTN_CAM_Set_AclBrk_Stm "21.11.07";
BA_ "Description" SG_ 956 BLTN_CAM_Set_GearPos_Stm "Record Set of Gear Position Stamp";
BA_ "GenSigSendType" SG_ 956 BLTN_CAM_Set_GearPos_Stm 4;
BA_ "UserSigValidity" SG_ 956 BLTN_CAM_Set_GearPos_Stm 0;
BA_ "Version" SG_ 956 BLTN_CAM_Set_GearPos_Stm "21.05.02";
BA_ "Description" SG_ 956 BLTN_CAM_Set_EVSen_Stm "Record Set of Event Sensitivity Stamp";
BA_ "GenSigSendType" SG_ 956 BLTN_CAM_Set_EVSen_Stm 4;
BA_ "UserSigValidity" SG_ 956 BLTN_CAM_Set_EVSen_Stm 0;
BA_ "Version" SG_ 956 BLTN_CAM_Set_EVSen_Stm "21.05.02";
BA_ "Description" SG_ 956 BLTN_CAM_Set_StrAngl_Stm "Record Set of Steering Angle Stamp";
BA_ "GenSigSendType" SG_ 956 BLTN_CAM_Set_StrAngl_Stm 4;
BA_ "UserSigValidity" SG_ 956 BLTN_CAM_Set_StrAngl_Stm 0;
BA_ "Version" SG_ 956 BLTN_CAM_Set_StrAngl_Stm "21.07.05";
BA_ "Description" SG_ 956 BLTN_CAM_Set_EV_RecMaxTime "BLTN_CAM Set EV Parking Rec Max Time";
BA_ "GenSigSendType" SG_ 956 BLTN_CAM_Set_EV_RecMaxTime 4;
BA_ "UserSigValidity" SG_ 956 BLTN_CAM_Set_EV_RecMaxTime 0;
BA_ "Version" SG_ 956 BLTN_CAM_Set_EV_RecMaxTime "23.02.02";
BA_ "Description" SG_ 956 BLTN_CAM_RecSet_STRM "Built-in Cam Live Video Streaming On/Off Set";
BA_ "GenSigSendType" SG_ 956 BLTN_CAM_RecSet_STRM 4;
BA_ "UserSigValidity" SG_ 956 BLTN_CAM_RecSet_STRM 0;
BA_ "Version" SG_ 956 BLTN_CAM_RecSet_STRM "25.04.01";
BA_ "Description" SG_ 956 BLTN_CAM_Set_PrkTime "Parking Operation Setting Time, Resolution : hr";
BA_ "GenSigSendType" SG_ 956 BLTN_CAM_Set_PrkTime 4;
BA_ "UserSigValidity" SG_ 956 BLTN_CAM_Set_PrkTime 0;
BA_ "Version" SG_ 956 BLTN_CAM_Set_PrkTime "25.01.01";
BA_ "Description" SG_ 957 BLTN_CAM_FD_STAT_Crc1Val "The data area for CRC calculation is based on the data length (DLC) of the message DB.

The CRC shall be calculated over the entire data block (excluding the CRC bytes) including the user data, alive counter and Data ID



- CRC Polynomial (0x1021) , Ini";
BA_ "GenSigSendType" SG_ 957 BLTN_CAM_FD_STAT_Crc1Val 4;
BA_ "GenSigStartValue" SG_ 957 BLTN_CAM_FD_STAT_Crc1Val 65535;
BA_ "UserSigValidity" SG_ 957 BLTN_CAM_FD_STAT_Crc1Val 3;
BA_ "Version" SG_ 957 BLTN_CAM_FD_STAT_Crc1Val "22.11.04";
BA_ "Description" SG_ 957 BLTN_CAM_Prk_Oprable_Time "The hours of Park Mode Operatable, the time is limited by user max oper. Set.";
BA_ "GenSigSendType" SG_ 957 BLTN_CAM_Prk_Oprable_Time 4;
BA_ "UserSigValidity" SG_ 957 BLTN_CAM_Prk_Oprable_Time 1;
BA_ "Version" SG_ 957 BLTN_CAM_Prk_Oprable_Time "25.01.01";
BA_ "Description" SG_ 957 BLTN_CAM_Prk_Oprable_Time_Max "The hours of Park Mode Operatable, the time has no limit.";
BA_ "GenSigSendType" SG_ 957 BLTN_CAM_Prk_Oprable_Time_Max 4;
BA_ "UserSigValidity" SG_ 957 BLTN_CAM_Prk_Oprable_Time_Max 1;
BA_ "Version" SG_ 957 BLTN_CAM_Prk_Oprable_Time_Max "24.07.05";
BA_ "Description" SG_ 957 BLTN_CAM_AuxBat_Conn_State "The auxiliary Battery conntction information.";
BA_ "GenSigSendType" SG_ 957 BLTN_CAM_AuxBat_Conn_State 4;
BA_ "UserSigValidity" SG_ 957 BLTN_CAM_AuxBat_Conn_State 0;
BA_ "Version" SG_ 957 BLTN_CAM_AuxBat_Conn_State "24.07.05";
BA_ "Description" SG_ 957 BLTN_CAM_AuxBat_CapPer "The percentage of Aux. Bat.";
BA_ "GenSigSendType" SG_ 957 BLTN_CAM_AuxBat_CapPer 4;
BA_ "UserSigValidity" SG_ 957 BLTN_CAM_AuxBat_CapPer 1;
BA_ "Version" SG_ 957 BLTN_CAM_AuxBat_CapPer "21.05.02";
BA_ "Description" SG_ 957 BLTN_CAM_ResetOpSta "This signal indicates whether the reset operation has been completed or not";
BA_ "GenSigSendType" SG_ 957 BLTN_CAM_ResetOpSta 4;
BA_ "UserSigValidity" SG_ 957 BLTN_CAM_ResetOpSta 0;
BA_ "Version" SG_ 957 BLTN_CAM_ResetOpSta "24.05.04";
BA_ "Description" SG_ 957 BLTN_CAM_SWVerMajor "Indicate the Built-in Cam software version as follows:

- The software version is displayed in seven digits.

- The Major, Minor1, Minor2, Minor3 digits are separated by '.'

- Major Signal value is transmitted to ASCII codes.

- Minor1/Minor2/Minor2 Sig";
BA_ "GenSigSendType" SG_ 957 BLTN_CAM_SWVerMajor 4;
BA_ "UserSigValidity" SG_ 957 BLTN_CAM_SWVerMajor 0;
BA_ "Version" SG_ 957 BLTN_CAM_SWVerMajor "21.07.05";
BA_ "Description" SG_ 957 BLTN_CAM_SWVerMinor1 "Indicate the Built-in Cam software version as follows:

- The software version is displayed in seven digits.

- The Major, Minor1, Minor2, Minor3 digits are separated by '.'

- Major Signal value is transmitted to ASCII codes.

- Minor1/Minor2/Minor2 Sig";
BA_ "GenSigSendType" SG_ 957 BLTN_CAM_SWVerMinor1 4;
BA_ "UserSigValidity" SG_ 957 BLTN_CAM_SWVerMinor1 0;
BA_ "Version" SG_ 957 BLTN_CAM_SWVerMinor1 "21.07.05";
BA_ "Description" SG_ 957 BLTN_CAM_SWVerMinor2 "Indicate the Built-in Cam software version as follows:

- The software version is displayed in seven digits.

- The Major, Minor1, Minor2, Minor3 digits are separated by '.'

- Major Signal value is transmitted to ASCII codes.

- Minor1/Minor2/Minor2 Sig";
BA_ "GenSigSendType" SG_ 957 BLTN_CAM_SWVerMinor2 4;
BA_ "UserSigValidity" SG_ 957 BLTN_CAM_SWVerMinor2 0;
BA_ "Version" SG_ 957 BLTN_CAM_SWVerMinor2 "21.07.05";
BA_ "Description" SG_ 957 BLTN_CAM_SWVerMinor3 "Indicate the Built-in Cam software version as follows:

- The software version is displayed in seven digits.

- The Major, Minor1, Minor2, Minor3 digits are separated by '.'

- Major Signal value is transmitted to ASCII codes.

- Minor1/Minor2/Minor2 Sig";
BA_ "GenSigSendType" SG_ 957 BLTN_CAM_SWVerMinor3 4;
BA_ "UserSigValidity" SG_ 957 BLTN_CAM_SWVerMinor3 0;
BA_ "Version" SG_ 957 BLTN_CAM_SWVerMinor3 "21.07.05";
BA_ "Description" SG_ 957 BLTN_CAM_FD_STAT_AlvCnt1Val "For the first transmission request for a data element the counter shall be initialized with 0 and shall be incremented by 1 for every subsequent send request. 

When the counter reaches the maximum value(0xFF), then it shall restart with 0 for the next s";
BA_ "GenSigSendType" SG_ 957 BLTN_CAM_FD_STAT_AlvCnt1Val 4;
BA_ "UserSigValidity" SG_ 957 BLTN_CAM_FD_STAT_AlvCnt1Val 3;
BA_ "Version" SG_ 957 BLTN_CAM_FD_STAT_AlvCnt1Val "22.11.04";
BA_ "Description" SG_ 957 BLTN_CAM_SD_Card_Manufacturer "Built-in Cam SD Card Manufacturer Information";
BA_ "GenSigSendType" SG_ 957 BLTN_CAM_SD_Card_Manufacturer 4;
BA_ "UserSigValidity" SG_ 957 BLTN_CAM_SD_Card_Manufacturer 0;
BA_ "Version" SG_ 957 BLTN_CAM_SD_Card_Manufacturer "22.07.05";
BA_ "Description" SG_ 957 BLTN_CAM_SD_Card_Cap_Class "SD Card Storage Capacity Class";
BA_ "GenSigSendType" SG_ 957 BLTN_CAM_SD_Card_Cap_Class 4;
BA_ "UserSigValidity" SG_ 957 BLTN_CAM_SD_Card_Cap_Class 0;
BA_ "Version" SG_ 957 BLTN_CAM_SD_Card_Cap_Class "25.03.01";
BA_ "Description" SG_ 957 BltnCamPlatformStatus "Provides Built-in Cam Platform generation information.

 ‘AVAILABLE’ and ‘AVAILABLE_BLTN_CAM_2 are same meaning.";
BA_ "GenSigSendType" SG_ 957 BltnCamPlatformStatus 4;
BA_ "UserSigValidity" SG_ 957 BltnCamPlatformStatus 0;
BA_ "Version" SG_ 957 BltnCamPlatformStatus "25.07.05";
BA_ "Description" SG_ 957 BLTN_CAM_CHInfo "Provides Built-in Cam Camera record channel information.";
BA_ "GenSigSendType" SG_ 957 BLTN_CAM_CHInfo 4;
BA_ "UserSigValidity" SG_ 957 BLTN_CAM_CHInfo 0;
BA_ "Version" SG_ 957 BLTN_CAM_CHInfo "25.07.04";
BA_ "Description" SG_ 957 BLTN_CAM_FoDInfo "Provides Built-in Cam FoD information";
BA_ "GenSigSendType" SG_ 957 BLTN_CAM_FoDInfo 4;
BA_ "UserSigValidity" SG_ 957 BLTN_CAM_FoDInfo 0;
BA_ "Version" SG_ 957 BLTN_CAM_FoDInfo "25.07.04";
BA_ "Description" SG_ 957 BLTN_CAM_WiFi_Info_QR "Provides Built-in Cam WiFi QR information.";
BA_ "GenSigSendType" SG_ 957 BLTN_CAM_WiFi_Info_QR 4;
BA_ "UserSigValidity" SG_ 957 BLTN_CAM_WiFi_Info_QR 0;
BA_ "Version" SG_ 957 BLTN_CAM_WiFi_Info_QR "25.07.05";
BA_ "Description" SG_ 957 BLTN_CAM_WiFi_Info_IP "Provides Built-in Cam WiFi IP information";
BA_ "GenSigSendType" SG_ 957 BLTN_CAM_WiFi_Info_IP 4;
BA_ "UserSigValidity" SG_ 957 BLTN_CAM_WiFi_Info_IP 0;
BA_ "Version" SG_ 957 BLTN_CAM_WiFi_Info_IP "25.07.05";
BA_ "Description" SG_ 957 BLTN_CAM_DistributeInfo1 "Provides Built-in Cam Distribution information.";
BA_ "GenSigSendType" SG_ 957 BLTN_CAM_DistributeInfo1 4;
BA_ "UserSigValidity" SG_ 957 BLTN_CAM_DistributeInfo1 0;
BA_ "Version" SG_ 957 BLTN_CAM_DistributeInfo1 "25.07.04";
BA_ "Description" SG_ 957 BltnCamSTRM_ServiceStatus "Provides Built-in Cam Streaming information";
BA_ "GenSigSendType" SG_ 957 BltnCamSTRM_ServiceStatus 4;
BA_ "UserSigValidity" SG_ 957 BltnCamSTRM_ServiceStatus 0;
BA_ "Version" SG_ 957 BltnCamSTRM_ServiceStatus "25.07.04";
BA_ "Description" SG_ 957 BLTN_CAM_PMD_Oprable_Time "the hours of Parked Motion Detection Mode Operatable";
BA_ "GenSigSendType" SG_ 957 BLTN_CAM_PMD_Oprable_Time 4;
BA_ "UserSigValidity" SG_ 957 BLTN_CAM_PMD_Oprable_Time 0;
BA_ "Version" SG_ 957 BLTN_CAM_PMD_Oprable_Time "24.01.05";
BA_ "Description" SG_ 957 BLTN_CAM_PMD_Oprable_Time_Max "the hours of Parked Motion Detection Mode Operatable Max";
BA_ "GenSigSendType" SG_ 957 BLTN_CAM_PMD_Oprable_Time_Max 4;
BA_ "UserSigValidity" SG_ 957 BLTN_CAM_PMD_Oprable_Time_Max 0;
BA_ "Version" SG_ 957 BLTN_CAM_PMD_Oprable_Time_Max "24.01.05";
BA_ "Description" SG_ 957 BLTN_CAM_RecSta_PMD "This Signal inform recording status of Parked Motion Detection.";
BA_ "GenSigSendType" SG_ 957 BLTN_CAM_RecSta_PMD 4;
BA_ "UserSigValidity" SG_ 957 BLTN_CAM_RecSta_PMD 0;
BA_ "Version" SG_ 957 BLTN_CAM_RecSta_PMD "25.07.04";
BA_ "Description" SG_ 957 BLTN_CAM_RecSta_BPR "Record Status of Built-inCAM Performance Recorder";
BA_ "GenSigSendType" SG_ 957 BLTN_CAM_RecSta_BPR 4;
BA_ "UserSigValidity" SG_ 957 BLTN_CAM_RecSta_BPR 0;
BA_ "Version" SG_ 957 BLTN_CAM_RecSta_BPR "24.04.03";
BA_ "Description" SG_ 957 BLTN_CAM_BPR_Spprt_Info "Built-inCAM Performance Record Support information";
BA_ "GenSigSendType" SG_ 957 BLTN_CAM_BPR_Spprt_Info 4;
BA_ "UserSigValidity" SG_ 957 BLTN_CAM_BPR_Spprt_Info 0;
BA_ "Version" SG_ 957 BLTN_CAM_BPR_Spprt_Info "24.04.03";
BA_ "Description" SG_ 957 BLTN_CAM_PDC_Reset_Opt "Built-in Cam PDC Reset Option Information";
BA_ "GenSigSendType" SG_ 957 BLTN_CAM_PDC_Reset_Opt 4;
BA_ "UserSigValidity" SG_ 957 BLTN_CAM_PDC_Reset_Opt 0;
BA_ "Version" SG_ 957 BLTN_CAM_PDC_Reset_Opt "24.07.01";
BA_ "Description" SG_ 957 BLTN_CAM_RecSta_LPE "Operation status of Low Power Event Recording mode while parking";
BA_ "GenSigSendType" SG_ 957 BLTN_CAM_RecSta_LPE 4;
BA_ "UserSigValidity" SG_ 957 BLTN_CAM_RecSta_LPE 0;
BA_ "Version" SG_ 957 BLTN_CAM_RecSta_LPE "25.07.04";
BA_ "Description" SG_ 957 BLTN_CAM_DistributeInfo "Information is required to classify the specifications of the related controller according to the occurrence of spec derivation by country in which the built-in cam is deployed (AVN, etc.)";
BA_ "GenSigSendType" SG_ 957 BLTN_CAM_DistributeInfo 4;
BA_ "UserSigValidity" SG_ 957 BLTN_CAM_DistributeInfo 0;
BA_ "Version" SG_ 957 BLTN_CAM_DistributeInfo "25.03.01";
BA_ "Description" SG_ 957 BLTN_CAM_Sta_STRM "Built-in Cam Live Video Streaming state";
BA_ "GenSigSendType" SG_ 957 BLTN_CAM_Sta_STRM 4;
BA_ "UserSigValidity" SG_ 957 BLTN_CAM_Sta_STRM 0;
BA_ "Version" SG_ 957 BLTN_CAM_Sta_STRM "25.04.01";
BA_ "Description" SG_ 957 BLTN_CAM_LPE_Option "Provides Built-in Cam Low Power Event function information.

enumeration";
BA_ "GenSigSendType" SG_ 957 BLTN_CAM_LPE_Option 4;
BA_ "UserSigValidity" SG_ 957 BLTN_CAM_LPE_Option 0;
BA_ "Version" SG_ 957 BLTN_CAM_LPE_Option "25.07.04";
BA_ "Description" SG_ 957 BLTN_CAM_State "This Signal is for cluster warning popup.";
BA_ "GenSigSendType" SG_ 957 BLTN_CAM_State 4;
BA_ "UserSigValidity" SG_ 957 BLTN_CAM_State 1;
BA_ "Version" SG_ 957 BLTN_CAM_State "21.05.02";
BA_ "Description" SG_ 957 BLTN_CAM_SD_Card_State "This Signal is for SD card Status in Built-in App menu and CCS Phone App.



0x4: Insufficient SD card capacity spec (BLTN_CAM 2/2.5 : 64GB or higher, BLTN_CAM 3 : 128GB or higher)";
BA_ "GenSigSendType" SG_ 957 BLTN_CAM_SD_Card_State 4;
BA_ "UserSigValidity" SG_ 957 BLTN_CAM_SD_Card_State 0;
BA_ "NetworkRequest" SG_ 957 BLTN_CAM_SD_Card_State 0;
BA_ "NetworkRequestHoldingTime" SG_ 957 BLTN_CAM_SD_Card_State 1000;
BA_ "Version" SG_ 957 BLTN_CAM_SD_Card_State "25.04.01";
BA_ "Description" SG_ 957 BLTN_CAM_RecSta_OWD "This Signal inform recording status of On While Driving.";
BA_ "GenSigSendType" SG_ 957 BLTN_CAM_RecSta_OWD 4;
BA_ "UserSigValidity" SG_ 957 BLTN_CAM_RecSta_OWD 1;
BA_ "Version" SG_ 957 BLTN_CAM_RecSta_OWD "21.05.02";
BA_ "Description" SG_ 957 BLTN_CAM_RecSta_DEV "This Signal inform recording status of Driving Event.";
BA_ "GenSigSendType" SG_ 957 BLTN_CAM_RecSta_DEV 4;
BA_ "UserSigValidity" SG_ 957 BLTN_CAM_RecSta_DEV 1;
BA_ "Version" SG_ 957 BLTN_CAM_RecSta_DEV "21.05.02";
BA_ "Description" SG_ 957 BLTN_CAM_RecSta_MAR "This Signal inform recording status of Manual Recording.";
BA_ "GenSigSendType" SG_ 957 BLTN_CAM_RecSta_MAR 4;
BA_ "UserSigValidity" SG_ 957 BLTN_CAM_RecSta_MAR 1;
BA_ "Version" SG_ 957 BLTN_CAM_RecSta_MAR "21.05.02";
BA_ "Description" SG_ 957 BLTN_CAM_RecSta_TML "This Signal inform recording status of Time-lapse.";
BA_ "GenSigSendType" SG_ 957 BLTN_CAM_RecSta_TML 4;
BA_ "UserSigValidity" SG_ 957 BLTN_CAM_RecSta_TML 1;
BA_ "Version" SG_ 957 BLTN_CAM_RecSta_TML "21.05.02";
BA_ "Description" SG_ 957 BLTN_CAM_RecSta_OWP "This Signal inform recording status of On While Parked.";
BA_ "GenSigSendType" SG_ 957 BLTN_CAM_RecSta_OWP 4;
BA_ "UserSigValidity" SG_ 957 BLTN_CAM_RecSta_OWP 1;
BA_ "Version" SG_ 957 BLTN_CAM_RecSta_OWP "21.05.02";
BA_ "Description" SG_ 957 BLTN_CAM_RecSta_PEV "This Signal inform recording status of Parked Event.";
BA_ "GenSigSendType" SG_ 957 BLTN_CAM_RecSta_PEV 4;
BA_ "UserSigValidity" SG_ 957 BLTN_CAM_RecSta_PEV 1;
BA_ "Version" SG_ 957 BLTN_CAM_RecSta_PEV "21.05.02";
BA_ "Description" SG_ 957 BLTN_CAM_Prk_EV_Cnt "The count number of a parked Event.";
BA_ "GenSigSendType" SG_ 957 BLTN_CAM_Prk_EV_Cnt 4;
BA_ "UserSigValidity" SG_ 957 BLTN_CAM_Prk_EV_Cnt 1;
BA_ "Version" SG_ 957 BLTN_CAM_Prk_EV_Cnt "21.05.02";
BA_ "Description" SG_ 957 BLTN_CAM_Prk_Oped_Time "The Parked Opreated time ingormation";
BA_ "GenSigSendType" SG_ 957 BLTN_CAM_Prk_Oped_Time 4;
BA_ "UserSigValidity" SG_ 957 BLTN_CAM_Prk_Oped_Time 1;
BA_ "Version" SG_ 957 BLTN_CAM_Prk_Oped_Time "22.07.05";
BA_ "Description" SG_ 686 HU_Car_Crc1Val "The data area for CRC calculation is based on the data length (DLC) of the message DB.

The CRC shall be calculated over the entire data block (excluding the CRC bytes) including the user data, alive counter and Data ID



- CRC Polynomial (0x1021) , Ini";
BA_ "GenSigSendType" SG_ 686 HU_Car_Crc1Val 4;
BA_ "GenSigStartValue" SG_ 686 HU_Car_Crc1Val 65535;
BA_ "UserSigValidity" SG_ 686 HU_Car_Crc1Val 3;
BA_ "Version" SG_ 686 HU_Car_Crc1Val "22.10.20";
BA_ "Description" SG_ 686 HU_Car_AlvCnt1Val "For the first transmission request for a data element the counter shall be initialized with 0 and shall be incremented by 1 for every subsequent send request. 

When the counter reaches the maximum value(0xFF), then it shall restart with 0 for the next s";
BA_ "GenSigSendType" SG_ 686 HU_Car_AlvCnt1Val 4;
BA_ "UserSigValidity" SG_ 686 HU_Car_AlvCnt1Val 3;
BA_ "Version" SG_ 686 HU_Car_AlvCnt1Val "22.10.20";
BA_ "GenSigSendType" SG_ 686 HU_IncomingCallState 4;
BA_ "GenSigStartValue" SG_ 686 HU_IncomingCallState 7;
BA_ "UserSigValidity" SG_ 686 HU_IncomingCallState 3;
BA_ "Version" SG_ 686 HU_IncomingCallState "24.05.04";
BA_ "Description" SG_ 686 HU_HardReset_Available "send signal whether hardware reset is available or not.";
BA_ "GenSigSendType" SG_ 686 HU_HardReset_Available 4;
BA_ "UserSigValidity" SG_ 686 HU_HardReset_Available 0;
BA_ "Version" SG_ 686 HU_HardReset_Available "24.10.03";
BA_ "Description" SG_ 686 HU_MKBD_ModeSwitch "This signal is used for the 'AVNT/Climate Switching Keyboard' to switch the display of buttons.";
BA_ "GenSigSendType" SG_ 686 HU_MKBD_ModeSwitch 4;
BA_ "GenSigStartValue" SG_ 686 HU_MKBD_ModeSwitch 3;
BA_ "UserSigValidity" SG_ 686 HU_MKBD_ModeSwitch 1;
BA_ "Version" SG_ 686 HU_MKBD_ModeSwitch "20.12.04";
BA_ "Description" SG_ 686 HU_VehiclePwr "* Use HU_PwrState (@HU_Car_PE_01) in new ECU or Logic related with HU power state";
BA_ "GenSigSendType" SG_ 686 HU_VehiclePwr 4;
BA_ "UserSigValidity" SG_ 686 HU_VehiclePwr 0;
BA_ "NetworkRequest" SG_ 686 HU_VehiclePwr 0;
BA_ "NetworkRequestHoldingTime" SG_ 686 HU_VehiclePwr 5000;
BA_ "Version" SG_ 686 HU_VehiclePwr "22.05.02";
BA_ "Description" SG_ 686 HU_BtnShowReq "This signal indicates requesting turn on/off button light for H/Unit related buttons.";
BA_ "GenSigSendType" SG_ 686 HU_BtnShowReq 4;
BA_ "GenSigStartValue" SG_ 686 HU_BtnShowReq 7;
BA_ "UserSigValidity" SG_ 686 HU_BtnShowReq 0;
BA_ "NetworkRequest" SG_ 686 HU_BtnShowReq 0;
BA_ "NetworkRequestHoldingTime" SG_ 686 HU_BtnShowReq 5000;
BA_ "Version" SG_ 686 HU_BtnShowReq "19.11.01";
BA_ "Description" SG_ 686 HU_ADMSettingState "The signal transfers ADM Setting Value(On/Off) from HU to other module.";
BA_ "GenSigSendType" SG_ 686 HU_ADMSettingState 4;
BA_ "UserSigValidity" SG_ 686 HU_ADMSettingState 0;
BA_ "NetworkRequest" SG_ 686 HU_ADMSettingState 0;
BA_ "NetworkRequestHoldingTime" SG_ 686 HU_ADMSettingState 5000;
BA_ "Version" SG_ 686 HU_ADMSettingState "21.01.07";
BA_ "Description" SG_ 686 HU_PwrState "Information for the H/U power status



* Do not use HU_VehiclePwr (@HU_Car_PE_01) in new ECU or Logic related with HU power state";
BA_ "GenSigSendType" SG_ 686 HU_PwrState 4;
BA_ "UserSigValidity" SG_ 686 HU_PwrState 0;
BA_ "Version" SG_ 686 HU_PwrState "22.05.02";
BA_ "Description" SG_ 686 HU_LCDState "Information for H/U LCD (Monitor) On/Off Status";
BA_ "GenSigSendType" SG_ 686 HU_LCDState 4;
BA_ "UserSigValidity" SG_ 686 HU_LCDState 0;
BA_ "Version" SG_ 686 HU_LCDState "22.05.02";
BA_ "Description" SG_ 274 HU_USM_Crc2Val "The data area for CRC calculation is based on the data length (DLC) of the message DB.

The CRC shall be calculated over the entire data block (excluding the CRC bytes) including the user data, alive counter and Data ID



- CRC Polynomial (0x1021) , Ini";
BA_ "GenSigSendType" SG_ 274 HU_USM_Crc2Val 4;
BA_ "GenSigStartValue" SG_ 274 HU_USM_Crc2Val 65535;
BA_ "UserSigValidity" SG_ 274 HU_USM_Crc2Val 3;
BA_ "Version" SG_ 274 HU_USM_Crc2Val "22.10.20";
BA_ "GenSigSendType" SG_ 274 CF_AVN_CluRheostatLvl 4;
BA_ "GenSigStartValue" SG_ 274 CF_AVN_CluRheostatLvl 31;
BA_ "UserSigValidity" SG_ 274 CF_AVN_CluRheostatLvl 3;
BA_ "Version" SG_ 274 CF_AVN_CluRheostatLvl "18.06.04";
BA_ "GenSigSendType" SG_ 274 CF_AVN_EVReset 4;
BA_ "UserSigValidity" SG_ 274 CF_AVN_EVReset 7;
BA_ "Version" SG_ 274 CF_AVN_EVReset "18.09.04";
BA_ "GenSigSendType" SG_ 274 CF_AVN_UnitReset 4;
BA_ "UserSigValidity" SG_ 274 CF_AVN_UnitReset 3;
BA_ "Version" SG_ 274 CF_AVN_UnitReset "18.09.04";
BA_ "GenSigSendType" SG_ 274 CF_AVN_IcyRoadWarn 4;
BA_ "UserSigValidity" SG_ 274 CF_AVN_IcyRoadWarn 3;
BA_ "Version" SG_ 274 CF_AVN_IcyRoadWarn "18.04.02";
BA_ "GenSigSendType" SG_ 274 CF_AVN_CluServiceReminderReset 4;
BA_ "UserSigValidity" SG_ 274 CF_AVN_CluServiceReminderReset 3;
BA_ "Version" SG_ 274 CF_AVN_CluServiceReminderReset "18.04.02";
BA_ "GenSigSendType" SG_ 274 CF_AVN_CluUSMReset 4;
BA_ "UserSigValidity" SG_ 274 CF_AVN_CluUSMReset 3;
BA_ "Version" SG_ 274 CF_AVN_CluUSMReset "21.01.08";
BA_ "GenSigSendType" SG_ 274 C_HCIMSWeightNValueSet 4;
BA_ "UserSigValidity" SG_ 274 C_HCIMSWeightNValueSet 3;
BA_ "Version" SG_ 274 C_HCIMSWeightNValueSet "18.09.04";
BA_ "GenSigSendType" SG_ 274 C_HCIMSHeightNvalueSet 4;
BA_ "UserSigValidity" SG_ 274 C_HCIMSHeightNvalueSet 3;
BA_ "Version" SG_ 274 C_HCIMSHeightNvalueSet "18.09.04";
BA_ "GenSigSendType" SG_ 274 CF_AVN_HCIMSButtonCommand 4;
BA_ "UserSigValidity" SG_ 274 CF_AVN_HCIMSButtonCommand 3;
BA_ "Version" SG_ 274 CF_AVN_HCIMSButtonCommand "18.09.04";
BA_ "GenSigSendType" SG_ 274 C_HCIMSSitHeightNValueSet 4;
BA_ "UserSigValidity" SG_ 274 C_HCIMSSitHeightNValueSet 3;
BA_ "Version" SG_ 274 C_HCIMSSitHeightNValueSet "18.09.04";
BA_ "GenSigSendType" SG_ 274 CF_AVN_BodySpprtSet 4;
BA_ "GenSigStartValue" SG_ 274 CF_AVN_BodySpprtSet 3;
BA_ "UserSigValidity" SG_ 274 CF_AVN_BodySpprtSet 3;
BA_ "Version" SG_ 274 CF_AVN_BodySpprtSet "18.11.01";
BA_ "Description" SG_ 274 HU_USM_AlvCnt2Val "For the first transmission request for a data element the counter shall be initialized with 0 and shall be incremented by 1 for every subsequent send request. 

When the counter reaches the maximum value(0xFF), then it shall restart with 0 for the next s";
BA_ "GenSigSendType" SG_ 274 HU_USM_AlvCnt2Val 4;
BA_ "UserSigValidity" SG_ 274 HU_USM_AlvCnt2Val 3;
BA_ "Version" SG_ 274 HU_USM_AlvCnt2Val "22.10.20";
BA_ "GenSigSendType" SG_ 274 CF_AVN_AirSptTimeNValueSet 4;
BA_ "GenSigStartValue" SG_ 274 CF_AVN_AirSptTimeNValueSet 7;
BA_ "UserSigValidity" SG_ 274 CF_AVN_AirSptTimeNValueSet 3;
BA_ "Version" SG_ 274 CF_AVN_AirSptTimeNValueSet "18.09.04";
BA_ "GenSigSendType" SG_ 274 CF_AVN_AirSptStrNValue 4;
BA_ "GenSigStartValue" SG_ 274 CF_AVN_AirSptStrNValue 3;
BA_ "UserSigValidity" SG_ 274 CF_AVN_AirSptStrNValue 3;
BA_ "Version" SG_ 274 CF_AVN_AirSptStrNValue "18.09.04";
BA_ "GenSigSendType" SG_ 274 CF_AVN_SeatDrvModNValueSet 4;
BA_ "GenSigStartValue" SG_ 274 CF_AVN_SeatDrvModNValueSet 3;
BA_ "UserSigValidity" SG_ 274 CF_AVN_SeatDrvModNValueSet 3;
BA_ "Version" SG_ 274 CF_AVN_SeatDrvModNValueSet "18.09.04";
BA_ "Description" SG_ 274 C_SmrtSldngDrNValueSet "USM request for Smart Sliding Door";
BA_ "GenSigSendType" SG_ 274 C_SmrtSldngDrNValueSet 4;
BA_ "UserSigValidity" SG_ 274 C_SmrtSldngDrNValueSet 3;
BA_ "Version" SG_ 274 C_SmrtSldngDrNValueSet "19.01.10";
BA_ "Description" SG_ 274 CF_AVN_TurboPressureUnit "USM Request for Turbo Boost Pressure Unit";
BA_ "GenSigSendType" SG_ 274 CF_AVN_TurboPressureUnit 4;
BA_ "UserSigValidity" SG_ 274 CF_AVN_TurboPressureUnit 3;
BA_ "Version" SG_ 274 CF_AVN_TurboPressureUnit "19.06.02";
BA_ "Description" SG_ 274 CF_AVN_CluTorqueUnit "USM Request for Torque Unit Setting";
BA_ "GenSigSendType" SG_ 274 CF_AVN_CluTorqueUnit 4;
BA_ "UserSigValidity" SG_ 274 CF_AVN_CluTorqueUnit 3;
BA_ "Version" SG_ 274 CF_AVN_CluTorqueUnit "19.06.02";
BA_ "GenSigSendType" SG_ 274 CF_AVN_MoodLpRedNValueSet 4;
BA_ "GenSigStartValue" SG_ 274 CF_AVN_MoodLpRedNValueSet 512;
BA_ "UserSigValidity" SG_ 274 CF_AVN_MoodLpRedNValueSet 3;
BA_ "NetworkRequest" SG_ 274 CF_AVN_MoodLpRedNValueSet 0;
BA_ "NetworkRequestHoldingTime" SG_ 274 CF_AVN_MoodLpRedNValueSet 200;
BA_ "Version" SG_ 274 CF_AVN_MoodLpRedNValueSet "20.08.06";
BA_ "GenSigSendType" SG_ 274 CF_AVN_MoodLpGreenNValueSet 4;
BA_ "GenSigStartValue" SG_ 274 CF_AVN_MoodLpGreenNValueSet 512;
BA_ "UserSigValidity" SG_ 274 CF_AVN_MoodLpGreenNValueSet 3;
BA_ "NetworkRequest" SG_ 274 CF_AVN_MoodLpGreenNValueSet 0;
BA_ "NetworkRequestHoldingTime" SG_ 274 CF_AVN_MoodLpGreenNValueSet 200;
BA_ "Version" SG_ 274 CF_AVN_MoodLpGreenNValueSet "20.08.06";
BA_ "GenSigSendType" SG_ 274 CF_AVN_MoodLpBlueNValueSet 4;
BA_ "GenSigStartValue" SG_ 274 CF_AVN_MoodLpBlueNValueSet 512;
BA_ "UserSigValidity" SG_ 274 CF_AVN_MoodLpBlueNValueSet 3;
BA_ "NetworkRequest" SG_ 274 CF_AVN_MoodLpBlueNValueSet 0;
BA_ "NetworkRequestHoldingTime" SG_ 274 CF_AVN_MoodLpBlueNValueSet 200;
BA_ "Version" SG_ 274 CF_AVN_MoodLpBlueNValueSet "20.08.06";
BA_ "GenSigSendType" SG_ 274 CF_AVN_MoodLpBrightNValueSet 4;
BA_ "UserSigValidity" SG_ 274 CF_AVN_MoodLpBrightNValueSet 3;
BA_ "NetworkRequest" SG_ 274 CF_AVN_MoodLpBrightNValueSet 0;
BA_ "NetworkRequestHoldingTime" SG_ 274 CF_AVN_MoodLpBrightNValueSet 200;
BA_ "Version" SG_ 274 CF_AVN_MoodLpBrightNValueSet "20.08.06";
BA_ "GenSigSendType" SG_ 274 CF_AVN_HBANValueSet 4;
BA_ "UserSigValidity" SG_ 274 CF_AVN_HBANValueSet 3;
BA_ "Version" SG_ 274 CF_AVN_HBANValueSet "18.09.04";
BA_ "GenSigSendType" SG_ 274 CF_AVN_IFSActVehSpd_Set 4;
BA_ "UserSigValidity" SG_ 274 CF_AVN_IFSActVehSpd_Set 3;
BA_ "Version" SG_ 274 CF_AVN_IFSActVehSpd_Set "18.09.04";
BA_ "GenSigSendType" SG_ 274 C_MoodLpDrivingNValue 4;
BA_ "UserSigValidity" SG_ 274 C_MoodLpDrivingNValue 3;
BA_ "Version" SG_ 274 C_MoodLpDrivingNValue "18.09.04";
BA_ "Description" SG_ 274 HU_DrivingPostureAssistUSMSet "Driving Posture Assist - USM set on/off Request (R2.0)";
BA_ "GenSigSendType" SG_ 274 HU_DrivingPostureAssistUSMSet 4;
BA_ "GenSigStartValue" SG_ 274 HU_DrivingPostureAssistUSMSet 15;
BA_ "UserSigValidity" SG_ 274 HU_DrivingPostureAssistUSMSet 1;
BA_ "Version" SG_ 274 HU_DrivingPostureAssistUSMSet "23.07.03";
BA_ "GenSigSendType" SG_ 274 C_MoodLPDrivemodeNValue 4;
BA_ "UserSigValidity" SG_ 274 C_MoodLPDrivemodeNValue 3;
BA_ "Version" SG_ 274 C_MoodLPDrivemodeNValue "18.12.03";
BA_ "GenSigSendType" SG_ 274 CF_AVN_SVMAutoOnNvalueSet 4;
BA_ "UserSigValidity" SG_ 274 CF_AVN_SVMAutoOnNvalueSet 3;
BA_ "Version" SG_ 274 CF_AVN_SVMAutoOnNvalueSet "18.09.04";
BA_ "GenSigSendType" SG_ 274 CF_AVN_DAW_LVDANValueSet 4;
BA_ "UserSigValidity" SG_ 274 CF_AVN_DAW_LVDANValueSet 3;
BA_ "Version" SG_ 274 CF_AVN_DAW_LVDANValueSet "18.09.04";
BA_ "Description" SG_ 274 CF_AVN_Clu3dDepthSet "This signal is used for request to set the depth of 3D";
BA_ "GenSigSendType" SG_ 274 CF_AVN_Clu3dDepthSet 4;
BA_ "UserSigValidity" SG_ 274 CF_AVN_Clu3dDepthSet 3;
BA_ "Version" SG_ 274 CF_AVN_Clu3dDepthSet "19.03.08";
BA_ "Description" SG_ 274 C_MoodLpFadeNValue "This signal is for Navigation speed warning related ambient light(MLM) control fucntion.

This signal indicates MLM Fade in/out control.";
BA_ "GenSigSendType" SG_ 274 C_MoodLpFadeNValue 4;
BA_ "UserSigValidity" SG_ 274 C_MoodLpFadeNValue 3;
BA_ "Version" SG_ 274 C_MoodLpFadeNValue "20.01.01";
BA_ "Description" SG_ 274 HU_DrvCushAirSprtUSMSet "Driver seat Cushion air support set On/Off request (R2.0)";
BA_ "GenSigSendType" SG_ 274 HU_DrvCushAirSprtUSMSet 4;
BA_ "GenSigStartValue" SG_ 274 HU_DrvCushAirSprtUSMSet 7;
BA_ "UserSigValidity" SG_ 274 HU_DrvCushAirSprtUSMSet 1;
BA_ "Version" SG_ 274 HU_DrvCushAirSprtUSMSet "23.07.03";
BA_ "Description" SG_ 274 HU_AstCushAirSprtUSMSet "Assist seat Cushion air support set On/Off request (R2.0)";
BA_ "GenSigSendType" SG_ 274 HU_AstCushAirSprtUSMSet 4;
BA_ "GenSigStartValue" SG_ 274 HU_AstCushAirSprtUSMSet 7;
BA_ "UserSigValidity" SG_ 274 HU_AstCushAirSprtUSMSet 1;
BA_ "Version" SG_ 274 HU_AstCushAirSprtUSMSet "23.07.03";
BA_ "Description" SG_ 274 HU_DrvStrchMassageSwSet "Driver Seat massage operation set on/off request (R2.0)";
BA_ "GenSigSendType" SG_ 274 HU_DrvStrchMassageSwSet 4;
BA_ "GenSigStartValue" SG_ 274 HU_DrvStrchMassageSwSet 3;
BA_ "UserSigValidity" SG_ 274 HU_DrvStrchMassageSwSet 1;
BA_ "Version" SG_ 274 HU_DrvStrchMassageSwSet "23.07.03";
BA_ "Description" SG_ 274 HU_DrvStrchMassageModeUSMSet "Driver Seat massage Mode set request (R2.0)";
BA_ "GenSigSendType" SG_ 274 HU_DrvStrchMassageModeUSMSet 4;
BA_ "GenSigStartValue" SG_ 274 HU_DrvStrchMassageModeUSMSet 7;
BA_ "UserSigValidity" SG_ 274 HU_DrvStrchMassageModeUSMSet 1;
BA_ "Version" SG_ 274 HU_DrvStrchMassageModeUSMSet "23.07.03";
BA_ "Description" SG_ 274 HU_DrvStrchMassageStrengthUSMSet "Driver Seat massage Strength set request (R2.0)";
BA_ "GenSigSendType" SG_ 274 HU_DrvStrchMassageStrengthUSMSet 4;
BA_ "GenSigStartValue" SG_ 274 HU_DrvStrchMassageStrengthUSMSet 7;
BA_ "UserSigValidity" SG_ 274 HU_DrvStrchMassageStrengthUSMSet 1;
BA_ "Version" SG_ 274 HU_DrvStrchMassageStrengthUSMSet "23.07.03";
BA_ "Description" SG_ 274 HU_DrvStrchMassageTimeUSMSet "Driver Seat massage Time set request (R2.0)";
BA_ "GenSigSendType" SG_ 274 HU_DrvStrchMassageTimeUSMSet 4;
BA_ "GenSigStartValue" SG_ 274 HU_DrvStrchMassageTimeUSMSet 7;
BA_ "UserSigValidity" SG_ 274 HU_DrvStrchMassageTimeUSMSet 1;
BA_ "Version" SG_ 274 HU_DrvStrchMassageTimeUSMSet "23.07.03";
BA_ "Description" SG_ 274 HU_AstStrchMassageSwSet "Assist Seat massage operation set on/off request (R2.0)";
BA_ "GenSigSendType" SG_ 274 HU_AstStrchMassageSwSet 4;
BA_ "GenSigStartValue" SG_ 274 HU_AstStrchMassageSwSet 3;
BA_ "UserSigValidity" SG_ 274 HU_AstStrchMassageSwSet 1;
BA_ "Version" SG_ 274 HU_AstStrchMassageSwSet "23.07.03";
BA_ "Description" SG_ 274 HU_AstStrchMassageModeUSMSet "Assit Seat massage Mode set request (R2.0)";
BA_ "GenSigSendType" SG_ 274 HU_AstStrchMassageModeUSMSet 4;
BA_ "GenSigStartValue" SG_ 274 HU_AstStrchMassageModeUSMSet 7;
BA_ "UserSigValidity" SG_ 274 HU_AstStrchMassageModeUSMSet 1;
BA_ "Version" SG_ 274 HU_AstStrchMassageModeUSMSet "23.07.03";
BA_ "Description" SG_ 274 HU_AstStrchMassageStrengthUSMSet "Assist Seat massage Strength set request (R2.0)";
BA_ "GenSigSendType" SG_ 274 HU_AstStrchMassageStrengthUSMSet 4;
BA_ "GenSigStartValue" SG_ 274 HU_AstStrchMassageStrengthUSMSet 7;
BA_ "UserSigValidity" SG_ 274 HU_AstStrchMassageStrengthUSMSet 1;
BA_ "Version" SG_ 274 HU_AstStrchMassageStrengthUSMSet "23.07.03";
BA_ "Description" SG_ 274 HU_AstStrchMassageTimeUSMSet "Assist Seat massage Time set request (R2.0)";
BA_ "GenSigSendType" SG_ 274 HU_AstStrchMassageTimeUSMSet 4;
BA_ "GenSigStartValue" SG_ 274 HU_AstStrchMassageTimeUSMSet 7;
BA_ "UserSigValidity" SG_ 274 HU_AstStrchMassageTimeUSMSet 1;
BA_ "Version" SG_ 274 HU_AstStrchMassageTimeUSMSet "23.07.03";
BA_ "Description" SG_ 274 HU_DrvMsgPulseUSMSet "Request to set Diver Seat Massage Pulse";
BA_ "GenSigSendType" SG_ 274 HU_DrvMsgPulseUSMSet 4;
BA_ "UserSigValidity" SG_ 274 HU_DrvMsgPulseUSMSet 3;
BA_ "Version" SG_ 274 HU_DrvMsgPulseUSMSet "24.03.03";
BA_ "Description" SG_ 274 HU_AstMsgPulseUSMSet "Request to set Assit Seat Massage Pulse";
BA_ "GenSigSendType" SG_ 274 HU_AstMsgPulseUSMSet 4;
BA_ "UserSigValidity" SG_ 274 HU_AstMsgPulseUSMSet 3;
BA_ "Version" SG_ 274 HU_AstMsgPulseUSMSet "24.03.03";
BA_ "Description" SG_ 274 HU_RLMsgPulseUSMSet "Request to set Rear Left Seat Massage Pulse";
BA_ "GenSigSendType" SG_ 274 HU_RLMsgPulseUSMSet 4;
BA_ "UserSigValidity" SG_ 274 HU_RLMsgPulseUSMSet 3;
BA_ "Version" SG_ 274 HU_RLMsgPulseUSMSet "24.03.03";
BA_ "Description" SG_ 274 HU_RRMsgPulseUSMSet "Requset to set Rear Right Seat Massage Pulse";
BA_ "GenSigSendType" SG_ 274 HU_RRMsgPulseUSMSet 4;
BA_ "UserSigValidity" SG_ 274 HU_RRMsgPulseUSMSet 3;
BA_ "Version" SG_ 274 HU_RRMsgPulseUSMSet "24.03.03";
BA_ "GenSigSendType" SG_ 274 CF_AVN_CluWelcomeSnd 4;
BA_ "UserSigValidity" SG_ 274 CF_AVN_CluWelcomeSnd 3;
BA_ "Version" SG_ 274 CF_AVN_CluWelcomeSnd "18.04.02";
BA_ "GenSigSendType" SG_ 274 CF_AVN_CluServiceReminderSet 4;
BA_ "UserSigValidity" SG_ 274 CF_AVN_CluServiceReminderSet 3;
BA_ "Version" SG_ 274 CF_AVN_CluServiceReminderSet "18.04.02";
BA_ "GenSigSendType" SG_ 274 CF_AVN_CluTransmissionDisp 4;
BA_ "UserSigValidity" SG_ 274 CF_AVN_CluTransmissionDisp 3;
BA_ "Version" SG_ 274 CF_AVN_CluTransmissionDisp "18.04.02";
BA_ "GenSigSendType" SG_ 274 CF_AVN_CluWiperLight 4;
BA_ "UserSigValidity" SG_ 274 CF_AVN_CluWiperLight 3;
BA_ "Version" SG_ 274 CF_AVN_CluWiperLight "18.04.02";
BA_ "GenSigSendType" SG_ 274 CF_AVN_CluRoadInfoGuide 4;
BA_ "UserSigValidity" SG_ 274 CF_AVN_CluRoadInfoGuide 3;
BA_ "Version" SG_ 274 CF_AVN_CluRoadInfoGuide "18.04.02";
BA_ "GenSigSendType" SG_ 274 CF_AVN_CluUserSettingPeriod 4;
BA_ "GenSigStartValue" SG_ 274 CF_AVN_CluUserSettingPeriod 127;
BA_ "UserSigValidity" SG_ 274 CF_AVN_CluUserSettingPeriod 3;
BA_ "Version" SG_ 274 CF_AVN_CluUserSettingPeriod "19.01.10";
BA_ "GenSigSendType" SG_ 274 CF_AVN_CluFuelEconUnit_mi 4;
BA_ "UserSigValidity" SG_ 274 CF_AVN_CluFuelEconUnit_mi 3;
BA_ "Version" SG_ 274 CF_AVN_CluFuelEconUnit_mi "18.09.04";
BA_ "GenSigSendType" SG_ 274 CF_AVN_CluFuelEconUnit_km 4;
BA_ "UserSigValidity" SG_ 274 CF_AVN_CluFuelEconUnit_km 3;
BA_ "Version" SG_ 274 CF_AVN_CluFuelEconUnit_km "20.08.02";
BA_ "GenSigSendType" SG_ 274 CF_AVN_CluUserSettingDistance 4;
BA_ "GenSigStartValue" SG_ 274 CF_AVN_CluUserSettingDistance 131071;
BA_ "UserSigValidity" SG_ 274 CF_AVN_CluUserSettingDistance 3;
BA_ "Version" SG_ 274 CF_AVN_CluUserSettingDistance "19.01.10";
BA_ "Description" SG_ 685 HU_BLTN_CAM_Crc2Val "The data area for CRC calculation is based on the data length (DLC) of the message DB.

The CRC shall be calculated over the entire data block (excluding the CRC bytes) including the user data, alive counter and Data ID



- CRC Polynomial (0x1021) , Ini";
BA_ "GenSigSendType" SG_ 685 HU_BLTN_CAM_Crc2Val 4;
BA_ "GenSigStartValue" SG_ 685 HU_BLTN_CAM_Crc2Val 65535;
BA_ "UserSigValidity" SG_ 685 HU_BLTN_CAM_Crc2Val 3;
BA_ "Version" SG_ 685 HU_BLTN_CAM_Crc2Val "22.10.20";
BA_ "Description" SG_ 685 HU_BLTN_CAM_AlvCnt2Val "For the first transmission request for a data element the counter shall be initialized with 0 and shall be incremented by 1 for every subsequent send request. 

When the counter reaches the maximum value(0xFF), then it shall restart with 0 for the next s";
BA_ "GenSigSendType" SG_ 685 HU_BLTN_CAM_AlvCnt2Val 4;
BA_ "UserSigValidity" SG_ 685 HU_BLTN_CAM_AlvCnt2Val 3;
BA_ "Version" SG_ 685 HU_BLTN_CAM_AlvCnt2Val "22.10.20";
BA_ "Description" SG_ 685 HU_WiFi_State "Send HU Wifi Connection State to Built-in CAM";
BA_ "GenSigSendType" SG_ 685 HU_WiFi_State 4;
BA_ "UserSigValidity" SG_ 685 HU_WiFi_State 0;
BA_ "Version" SG_ 685 HU_WiFi_State "24.04.06";
BA_ "Description" SG_ 685 HU_BLTN_CAM_UI_Mode "Display control of Built-in Cam UI mode. This Signal for Ethernet Type Built-in Cam.";
BA_ "GenSigSendType" SG_ 685 HU_BLTN_CAM_UI_Mode 4;
BA_ "UserSigValidity" SG_ 685 HU_BLTN_CAM_UI_Mode 0;
BA_ "Version" SG_ 685 HU_BLTN_CAM_UI_Mode "24.04.03";
BA_ "Description" SG_ 685 HU_BLTN_CAM_Display "Display control of Built-in Cam UI mode. This Signal for CAN Type Built-in Cam.(with Standard 5th Wide AVNT)";
BA_ "GenSigSendType" SG_ 685 HU_BLTN_CAM_Display 4;
BA_ "UserSigValidity" SG_ 685 HU_BLTN_CAM_Display 1;
BA_ "Version" SG_ 685 HU_BLTN_CAM_Display "22.07.05";
BA_ "Description" SG_ 138 HU_GW_Crc1Val "The data area for CRC calculation is based on the data length (DLC) of the message DB.

The CRC shall be calculated over the entire data block (excluding the CRC bytes) including the user data, alive counter and Data ID



- CRC Polynomial (0x1021) , Ini";
BA_ "GenSigSendType" SG_ 138 HU_GW_Crc1Val 4;
BA_ "GenSigStartValue" SG_ 138 HU_GW_Crc1Val 65535;
BA_ "UserSigValidity" SG_ 138 HU_GW_Crc1Val 3;
BA_ "Version" SG_ 138 HU_GW_Crc1Val "22.10.20";
BA_ "GenSigSendType" SG_ 138 HU_TgSoc_QcChg_Set 4;
BA_ "GenSigStartValue" SG_ 138 HU_TgSoc_QcChg_Set 255;
BA_ "UserSigValidity" SG_ 138 HU_TgSoc_QcChg_Set 7;
BA_ "Version" SG_ 138 HU_TgSoc_QcChg_Set "18.09.04";
BA_ "Description" SG_ 138 HU_UserApproval "Signal to send user decision on OTA approval.";
BA_ "GenSigSendType" SG_ 138 HU_UserApproval 4;
BA_ "UserSigValidity" SG_ 138 HU_UserApproval 0;
BA_ "Version" SG_ 138 HU_UserApproval "23.02.02";
BA_ "Description" SG_ 138 HU_OtaInfomationReq "제어기 OTA 관련 필요 정보를 요청하는 신호 (SW 버전, What's New, Download 진행율, Update 진행율)";
BA_ "GenSigSendType" SG_ 138 HU_OtaInfomationReq 4;
BA_ "UserSigValidity" SG_ 138 HU_OtaInfomationReq 0;
BA_ "Version" SG_ 138 HU_OtaInfomationReq "19.12.01";
BA_ "Description" SG_ 138 HU_ICU_RearDefSet "Rear window defog control";
BA_ "GenSigSendType" SG_ 138 HU_ICU_RearDefSet 4;
BA_ "GenSigStartValue" SG_ 138 HU_ICU_RearDefSet 3;
BA_ "UserSigValidity" SG_ 138 HU_ICU_RearDefSet 3;
BA_ "Version" SG_ 138 HU_ICU_RearDefSet "20.01.02";
BA_ "Description" SG_ 138 HU_CDMOpenCmd "Command for CDM open/close";
BA_ "GenSigSendType" SG_ 138 HU_CDMOpenCmd 4;
BA_ "UserSigValidity" SG_ 138 HU_CDMOpenCmd 7;
BA_ "Version" SG_ 138 HU_CDMOpenCmd "20.01.02";
BA_ "GenSigSendType" SG_ 138 C_PreCrankReq 4;
BA_ "UserSigValidity" SG_ 138 C_PreCrankReq 0;
BA_ "NetworkRequest" SG_ 138 C_PreCrankReq 0;
BA_ "Version" SG_ 138 C_PreCrankReq "18.09.04";
BA_ "Description" SG_ 138 HU_GW_AlvCnt1Val "For the first transmission request for a data element the counter shall be initialized with 0 and shall be incremented by 1 for every subsequent send request. 

When the counter reaches the maximum value(0xFF), then it shall restart with 0 for the next s";
BA_ "GenSigSendType" SG_ 138 HU_GW_AlvCnt1Val 4;
BA_ "UserSigValidity" SG_ 138 HU_GW_AlvCnt1Val 3;
BA_ "Version" SG_ 138 HU_GW_AlvCnt1Val "22.10.20";
BA_ "GenSigSendType" SG_ 138 C_TeleAstSeatOpCmdIBOX 4;
BA_ "UserSigValidity" SG_ 138 C_TeleAstSeatOpCmdIBOX 3;
BA_ "Version" SG_ 138 C_TeleAstSeatOpCmdIBOX "18.09.04";
BA_ "GenSigSendType" SG_ 138 C_TeleDrvSeatOpCmdIBOX 4;
BA_ "UserSigValidity" SG_ 138 C_TeleDrvSeatOpCmdIBOX 3;
BA_ "Version" SG_ 138 C_TeleDrvSeatOpCmdIBOX "18.09.04";
BA_ "GenSigSendType" SG_ 138 C_TeleRRSeatOpCmdIBOX 4;
BA_ "UserSigValidity" SG_ 138 C_TeleRRSeatOpCmdIBOX 3;
BA_ "Version" SG_ 138 C_TeleRRSeatOpCmdIBOX "18.09.04";
BA_ "GenSigSendType" SG_ 138 C_TeleRLSeatOpCmdIBOX 4;
BA_ "UserSigValidity" SG_ 138 C_TeleRLSeatOpCmdIBOX 3;
BA_ "Version" SG_ 138 C_TeleRLSeatOpCmdIBOX "18.09.04";
BA_ "Description" SG_ 138 C_DrvPSDCloseRlyIBOX "Remote control left PSD close command";
BA_ "GenSigSendType" SG_ 138 C_DrvPSDCloseRlyIBOX 4;
BA_ "GenSigStartValue" SG_ 138 C_DrvPSDCloseRlyIBOX 3;
BA_ "UserSigValidity" SG_ 138 C_DrvPSDCloseRlyIBOX 0;
BA_ "NetworkRequest" SG_ 138 C_DrvPSDCloseRlyIBOX 0;
BA_ "NetworkRequestHoldingTime" SG_ 138 C_DrvPSDCloseRlyIBOX 2000;
BA_ "Version" SG_ 138 C_DrvPSDCloseRlyIBOX "19.12.08";
BA_ "Description" SG_ 138 C_DrvPSDOpenRlyIBOX "Remote control left PSD open command";
BA_ "GenSigSendType" SG_ 138 C_DrvPSDOpenRlyIBOX 4;
BA_ "GenSigStartValue" SG_ 138 C_DrvPSDOpenRlyIBOX 3;
BA_ "UserSigValidity" SG_ 138 C_DrvPSDOpenRlyIBOX 0;
BA_ "NetworkRequest" SG_ 138 C_DrvPSDOpenRlyIBOX 0;
BA_ "NetworkRequestHoldingTime" SG_ 138 C_DrvPSDOpenRlyIBOX 2000;
BA_ "Version" SG_ 138 C_DrvPSDOpenRlyIBOX "19.12.08";
BA_ "Description" SG_ 138 C_AstPSDCloseRlyIBOX "Remote control right PSD close command";
BA_ "GenSigSendType" SG_ 138 C_AstPSDCloseRlyIBOX 4;
BA_ "GenSigStartValue" SG_ 138 C_AstPSDCloseRlyIBOX 3;
BA_ "UserSigValidity" SG_ 138 C_AstPSDCloseRlyIBOX 0;
BA_ "NetworkRequest" SG_ 138 C_AstPSDCloseRlyIBOX 0;
BA_ "NetworkRequestHoldingTime" SG_ 138 C_AstPSDCloseRlyIBOX 2000;
BA_ "Version" SG_ 138 C_AstPSDCloseRlyIBOX "19.12.08";
BA_ "Description" SG_ 138 C_AstPSDOpenRlyIBOX "Remote control right PSD open command";
BA_ "GenSigSendType" SG_ 138 C_AstPSDOpenRlyIBOX 4;
BA_ "GenSigStartValue" SG_ 138 C_AstPSDOpenRlyIBOX 3;
BA_ "UserSigValidity" SG_ 138 C_AstPSDOpenRlyIBOX 0;
BA_ "NetworkRequest" SG_ 138 C_AstPSDOpenRlyIBOX 0;
BA_ "NetworkRequestHoldingTime" SG_ 138 C_AstPSDOpenRlyIBOX 2000;
BA_ "Version" SG_ 138 C_AstPSDOpenRlyIBOX "19.12.08";
BA_ "Description" SG_ 138 HU_StrgWhlHeatingSet_VR "Command for VR Heating Control (Steering Wheel 1/2step)";
BA_ "GenSigSendType" SG_ 138 HU_StrgWhlHeatingSet_VR 4;
BA_ "GenSigStartValue" SG_ 138 HU_StrgWhlHeatingSet_VR 7;
BA_ "UserSigValidity" SG_ 138 HU_StrgWhlHeatingSet_VR 7;
BA_ "NetworkRequest" SG_ 138 HU_StrgWhlHeatingSet_VR 0;
BA_ "NetworkRequestHoldingTime" SG_ 138 HU_StrgWhlHeatingSet_VR 2000;
BA_ "Version" SG_ 138 HU_StrgWhlHeatingSet_VR "21.12.00";
BA_ "Description" SG_ 138 AVN_VGS_SET "on/off setting of VGS";
BA_ "GenSigSendType" SG_ 138 AVN_VGS_SET 4;
BA_ "UserSigValidity" SG_ 138 AVN_VGS_SET 3;
BA_ "Version" SG_ 138 AVN_VGS_SET "21.11.07";
BA_ "Description" SG_ 138 MODE_VCU_SET2 "Set the VCU setting in custom mode 2";
BA_ "GenSigSendType" SG_ 138 MODE_VCU_SET2 4;
BA_ "GenSigStartValue" SG_ 138 MODE_VCU_SET2 7;
BA_ "UserSigValidity" SG_ 138 MODE_VCU_SET2 3;
BA_ "Version" SG_ 138 MODE_VCU_SET2 "25.01.00";
BA_ "Description" SG_ 138 AVN_DriftMode_SET "on/off setting of Drift Mode";
BA_ "GenSigSendType" SG_ 138 AVN_DriftMode_SET 4;
BA_ "UserSigValidity" SG_ 138 AVN_DriftMode_SET 3;
BA_ "Version" SG_ 138 AVN_DriftMode_SET "21.12.00";
BA_ "Description" SG_ 138 AVN_NduranceRace_SET "Track Optimizer on/off setting";
BA_ "GenSigSendType" SG_ 138 AVN_NduranceRace_SET 4;
BA_ "UserSigValidity" SG_ 138 AVN_NduranceRace_SET 3;
BA_ "Version" SG_ 138 AVN_NduranceRace_SET "23.02.02";
BA_ "Description" SG_ 138 AVN_MaxRange_SET "AVNT Performance Limit Extender on/off setting";
BA_ "GenSigSendType" SG_ 138 AVN_MaxRange_SET 4;
BA_ "UserSigValidity" SG_ 138 AVN_MaxRange_SET 3;
BA_ "Version" SG_ 138 AVN_MaxRange_SET "23.02.02";
BA_ "Description" SG_ 138 HU_MKBD_TouchSensSet "MKBD touch sensitivity set signal";
BA_ "GenSigSendType" SG_ 138 HU_MKBD_TouchSensSet 4;
BA_ "UserSigValidity" SG_ 138 HU_MKBD_TouchSensSet 1;
BA_ "Version" SG_ 138 HU_MKBD_TouchSensSet "23.02.10";
BA_ "Description" SG_ 138 AVN_NTDBalance_SET "Power balance setting. This value means front wheel power.";
BA_ "GenSigSendType" SG_ 138 AVN_NTDBalance_SET 4;
BA_ "UserSigValidity" SG_ 138 AVN_NTDBalance_SET 3;
BA_ "Version" SG_ 138 AVN_NTDBalance_SET "23.02.02";
BA_ "Description" SG_ 138 LaunchControl_Activate_EV "Launch control on/off setting for EV N vehicles";
BA_ "GenSigSendType" SG_ 138 LaunchControl_Activate_EV 4;
BA_ "UserSigValidity" SG_ 138 LaunchControl_Activate_EV 3;
BA_ "Version" SG_ 138 LaunchControl_Activate_EV "22.01.06";
BA_ "Description" SG_ 138 LaunchControl_GripLevel_Reset "Initialize grip level reset. When 0x2 value is transmitted from HU, VCU changes grip level setting to default value.";
BA_ "GenSigSendType" SG_ 138 LaunchControl_GripLevel_Reset 4;
BA_ "UserSigValidity" SG_ 138 LaunchControl_GripLevel_Reset 3;
BA_ "Version" SG_ 138 LaunchControl_GripLevel_Reset "22.01.06";
BA_ "Description" SG_ 138 LaunchControl_GripLevel_Set "Launch control grip level setting";
BA_ "GenSigSendType" SG_ 138 LaunchControl_GripLevel_Set 4;
BA_ "UserSigValidity" SG_ 138 LaunchControl_GripLevel_Set 3;
BA_ "Version" SG_ 138 LaunchControl_GripLevel_Set "22.01.06";
BA_ "Description" SG_ 138 MODE_Drift_TCS_SET "setting value for TCS of drift optimizer";
BA_ "GenSigSendType" SG_ 138 MODE_Drift_TCS_SET 4;
BA_ "UserSigValidity" SG_ 138 MODE_Drift_TCS_SET 3;
BA_ "Version" SG_ 138 MODE_Drift_TCS_SET "22.06.04";
BA_ "Description" SG_ 138 MODE_Drift_VDC_SET "setting value for VDC of drift optimizer";
BA_ "GenSigSendType" SG_ 138 MODE_Drift_VDC_SET 4;
BA_ "UserSigValidity" SG_ 138 MODE_Drift_VDC_SET 3;
BA_ "Version" SG_ 138 MODE_Drift_VDC_SET "22.06.04";
BA_ "Description" SG_ 138 HU_Popupdown_Req "Request for Monitor Pop-up/down control";
BA_ "GenSigSendType" SG_ 138 HU_Popupdown_Req 4;
BA_ "UserSigValidity" SG_ 138 HU_Popupdown_Req 1;
BA_ "Version" SG_ 138 HU_Popupdown_Req "23.07.02";
BA_ "Description" SG_ 138 MODE_Drift_MDPS_SET "setting value for MDPS of drift optimizer";
BA_ "GenSigSendType" SG_ 138 MODE_Drift_MDPS_SET 4;
BA_ "UserSigValidity" SG_ 138 MODE_Drift_MDPS_SET 3;
BA_ "Version" SG_ 138 MODE_Drift_MDPS_SET "22.06.04";
BA_ "Description" SG_ 138 MODE_Drift_ECS_SET "setting value for ECS of drift optimizer";
BA_ "GenSigSendType" SG_ 138 MODE_Drift_ECS_SET 4;
BA_ "UserSigValidity" SG_ 138 MODE_Drift_ECS_SET 3;
BA_ "Version" SG_ 138 MODE_Drift_ECS_SET "22.06.04";
BA_ "Description" SG_ 138 MODE_Drift_ELSD_SET "setting value for ELSD of drift optimizer";
BA_ "GenSigSendType" SG_ 138 MODE_Drift_ELSD_SET 4;
BA_ "UserSigValidity" SG_ 138 MODE_Drift_ELSD_SET 3;
BA_ "Version" SG_ 138 MODE_Drift_ELSD_SET "22.06.04";
BA_ "Description" SG_ 138 HU_NCond_DragSet "N conditioning drag on/off setting value";
BA_ "GenSigSendType" SG_ 138 HU_NCond_DragSet 4;
BA_ "UserSigValidity" SG_ 138 HU_NCond_DragSet 3;
BA_ "Version" SG_ 138 HU_NCond_DragSet "22.07.05";
BA_ "Description" SG_ 138 HU_NCond_TrackSet "N conditioning track on/off setting value";
BA_ "GenSigSendType" SG_ 138 HU_NCond_TrackSet 4;
BA_ "UserSigValidity" SG_ 138 HU_NCond_TrackSet 3;
BA_ "Version" SG_ 138 HU_NCond_TrackSet "22.07.05";
BA_ "Description" SG_ 138 AVN_Npedal_SET "N pedal on/off setting";
BA_ "GenSigSendType" SG_ 138 AVN_Npedal_SET 4;
BA_ "UserSigValidity" SG_ 138 AVN_Npedal_SET 3;
BA_ "Version" SG_ 138 AVN_Npedal_SET "22.10.20";
BA_ "Description" SG_ 138 AVN_NTD_SET "on/off setting of NTC";
BA_ "GenSigSendType" SG_ 138 AVN_NTD_SET 4;
BA_ "UserSigValidity" SG_ 138 AVN_NTD_SET 3;
BA_ "Version" SG_ 138 AVN_NTD_SET "23.02.02";
BA_ "Description" SG_ 138 HU_PopupAgreement_Push "Information for user agreement of monitor popup";
BA_ "GenSigSendType" SG_ 138 HU_PopupAgreement_Push 4;
BA_ "UserSigValidity" SG_ 138 HU_PopupAgreement_Push 1;
BA_ "Version" SG_ 138 HU_PopupAgreement_Push "23.07.02";
BA_ "Description" SG_ 138 HU_StayModeStartReq "Stay Mode Start Request";
BA_ "GenSigSendType" SG_ 138 HU_StayModeStartReq 4;
BA_ "GenSigStartValue" SG_ 138 HU_StayModeStartReq 7;
BA_ "UserSigValidity" SG_ 138 HU_StayModeStartReq 1;
BA_ "Version" SG_ 138 HU_StayModeStartReq "24.04.06";
BA_ "Description" SG_ 138 HU_StayModeReservationReq "Stay Mode Reservation Request";
BA_ "GenSigSendType" SG_ 138 HU_StayModeReservationReq 4;
BA_ "GenSigStartValue" SG_ 138 HU_StayModeReservationReq 7;
BA_ "UserSigValidity" SG_ 138 HU_StayModeReservationReq 1;
BA_ "Version" SG_ 138 HU_StayModeReservationReq "24.04.06";
BA_ "Description" SG_ 138 HU_StayModeExtensionReq "Stay Mode Extension Request";
BA_ "GenSigSendType" SG_ 138 HU_StayModeExtensionReq 4;
BA_ "GenSigStartValue" SG_ 138 HU_StayModeExtensionReq 7;
BA_ "UserSigValidity" SG_ 138 HU_StayModeExtensionReq 1;
BA_ "Version" SG_ 138 HU_StayModeExtensionReq "24.04.06";
BA_ "Description" SG_ 138 HU_StayModeSetReq "Stay Mode Setting Request";
BA_ "GenSigSendType" SG_ 138 HU_StayModeSetReq 4;
BA_ "GenSigStartValue" SG_ 138 HU_StayModeSetReq 7;
BA_ "UserSigValidity" SG_ 138 HU_StayModeSetReq 1;
BA_ "Version" SG_ 138 HU_StayModeSetReq "24.04.06";
BA_ "Description" SG_ 138 HU_StayModeIdleTimeSetReq "Stay Mode Idle Time Setting Request";
BA_ "GenSigSendType" SG_ 138 HU_StayModeIdleTimeSetReq 4;
BA_ "GenSigStartValue" SG_ 138 HU_StayModeIdleTimeSetReq 15;
BA_ "UserSigValidity" SG_ 138 HU_StayModeIdleTimeSetReq 1;
BA_ "Version" SG_ 138 HU_StayModeIdleTimeSetReq "24.04.06";
BA_ "Description" SG_ 138 HU_StayModeMaxTimeSetReq "Stay Mode Maximum Time Setting Request";
BA_ "GenSigSendType" SG_ 138 HU_StayModeMaxTimeSetReq 4;
BA_ "GenSigStartValue" SG_ 138 HU_StayModeMaxTimeSetReq 15;
BA_ "UserSigValidity" SG_ 138 HU_StayModeMaxTimeSetReq 1;
BA_ "Version" SG_ 138 HU_StayModeMaxTimeSetReq "24.04.06";
BA_ "Description" SG_ 138 MODE_Drift_VDC_Level_SET "VDC Level SET";
BA_ "GenSigSendType" SG_ 138 MODE_Drift_VDC_Level_SET 4;
BA_ "GenSigStartValue" SG_ 138 MODE_Drift_VDC_Level_SET 1;
BA_ "UserSigValidity" SG_ 138 MODE_Drift_VDC_Level_SET 3;
BA_ "Version" SG_ 138 MODE_Drift_VDC_Level_SET "24.05.08";
BA_ "Description" SG_ 138 MODE_Drift_RTO_Level_SET "NDS RTO level SET";
BA_ "GenSigSendType" SG_ 138 MODE_Drift_RTO_Level_SET 4;
BA_ "GenSigStartValue" SG_ 138 MODE_Drift_RTO_Level_SET 2;
BA_ "UserSigValidity" SG_ 138 MODE_Drift_RTO_Level_SET 3;
BA_ "Version" SG_ 138 MODE_Drift_RTO_Level_SET "24.05.08";
BA_ "Description" SG_ 138 HU_SafetyModeReq "Safety Mode On/Off Request";
BA_ "GenSigSendType" SG_ 138 HU_SafetyModeReq 4;
BA_ "UserSigValidity" SG_ 138 HU_SafetyModeReq 7;
BA_ "Version" SG_ 138 HU_SafetyModeReq "25.04.01";
BA_ "Description" SG_ 138 HU_DriveConfirmPopup "Drive ready confirm signal when drive ready ok button is pushed.";
BA_ "GenSigSendType" SG_ 138 HU_DriveConfirmPopup 4;
BA_ "UserSigValidity" SG_ 138 HU_DriveConfirmPopup 7;
BA_ "Version" SG_ 138 HU_DriveConfirmPopup "25.04.01";
BA_ "Description" SG_ 138 HU_LghtDnSafetyModReq "Request for the safety sate on/off (Camp mode/Interior light brightness down)";
BA_ "GenSigSendType" SG_ 138 HU_LghtDnSafetyModReq 4;
BA_ "GenSigStartValue" SG_ 138 HU_LghtDnSafetyModReq 3;
BA_ "UserSigValidity" SG_ 138 HU_LghtDnSafetyModReq 7;
BA_ "Version" SG_ 138 HU_LghtDnSafetyModReq "25.06.00";
BA_ "Description" SG_ 138 SWRC_Sensitivity_SET "This signal is for the SWRC Optical Switch Sensitivity Setting";
BA_ "GenSigSendType" SG_ 138 SWRC_Sensitivity_SET 4;
BA_ "GenSigStartValue" SG_ 138 SWRC_Sensitivity_SET 3;
BA_ "UserSigValidity" SG_ 138 SWRC_Sensitivity_SET 3;
BA_ "Version" SG_ 138 SWRC_Sensitivity_SET "19.12.00";
BA_ "Description" SG_ 138 HU_ChgInCurrModSet "Charge current set signal";
BA_ "GenSigSendType" SG_ 138 HU_ChgInCurrModSet 4;
BA_ "UserSigValidity" SG_ 138 HU_ChgInCurrModSet 7;
BA_ "Version" SG_ 138 HU_ChgInCurrModSet "19.08.06";
BA_ "GenSigSendType" SG_ 138 HU_EV_WinterMode 4;
BA_ "GenSigStartValue" SG_ 138 HU_EV_WinterMode 3;
BA_ "UserSigValidity" SG_ 138 HU_EV_WinterMode 7;
BA_ "Version" SG_ 138 HU_EV_WinterMode "18.09.04";
BA_ "GenSigSendType" SG_ 138 HU_TgSoc_ScChg_Set 4;
BA_ "GenSigStartValue" SG_ 138 HU_TgSoc_ScChg_Set 255;
BA_ "UserSigValidity" SG_ 138 HU_TgSoc_ScChg_Set 7;
BA_ "Version" SG_ 138 HU_TgSoc_ScChg_Set "18.09.04";
BA_REL_ "GenSigTimeoutTime" BU_SG_REL_ CGW_CCU SG_ 956 BLTN_CAM_Set_EV_BfrTime 1500;
BA_REL_ "GenSigTimeoutTime" BU_SG_REL_ CGW_CCU SG_ 956 BLTN_CAM_Set_EV_AftTime 1500;
BA_REL_ "GenSigTimeoutTime" BU_SG_REL_ CGW_CCU SG_ 956 BLTN_CAM_Set_Drv_TML_Int 1500;
BA_REL_ "GenSigTimeoutTime" BU_SG_REL_ CGW_CCU SG_ 956 BLTN_CAM_SenSet_DEV 1500;
BA_REL_ "GenSigTimeoutTime" BU_SG_REL_ CGW_CCU SG_ 956 BLTN_CAM_SenSet_PEV 1500;
BA_REL_ "GenSigTimeoutTime" BU_SG_REL_ CGW_CCU SG_ 956 BLTN_CAM_Set_FR_Ver_Pos 1500;
BA_REL_ "GenSigTimeoutTime" BU_SG_REL_ CGW_CCU SG_ 956 BLTN_CAM_Set_RR_Ver_Pos 1500;
BA_REL_ "GenSigTimeoutTime" BU_SG_REL_ CGW_CCU SG_ 956 BLTN_CAM_Set_PEV_AppNoti 1500;
BA_REL_ "GenSigTimeoutTime" BU_SG_REL_ CGW_CCU SG_ 956 BLTN_CAM_Set_WiFi_AutoOn 1500;
BA_REL_ "GenSigTimeoutTime" BU_SG_REL_ CGW_CCU SG_ 956 BLTN_CAM_StrgPropSet 1500;
BA_REL_ "GenSigTimeoutTime" BU_SG_REL_ CGW_CCU SG_ 956 BLTN_CAM_File_DEL_CPY_Op_State 1500;
BA_REL_ "GenSigTimeoutTime" BU_SG_REL_ CGW_CCU SG_ 956 BLTN_CAM_File_DEL_CPY_NumTot 1500;
BA_REL_ "GenSigTimeoutTime" BU_SG_REL_ CGW_CCU SG_ 956 BLTN_CAM_File_DEL_CPYed_Num 1500;
BA_REL_ "GenSigTimeoutTime" BU_SG_REL_ CGW_CCU SG_ 956 VAPI_BltnCamInsideSwEnable_Get 1500;
BA_REL_ "GenSigTimeoutTime" BU_SG_REL_ CGW_CCU SG_ 956 BLTN_CAM_Set_PMD 1500;
BA_REL_ "GenSigTimeoutTime" BU_SG_REL_ CGW_CCU SG_ 956 BLTN_CAM_Set_PMDEV 1500;
BA_REL_ "GenSigTimeoutTime" BU_SG_REL_ CGW_CCU SG_ 956 BLTN_CAM_RanSet_PMDR 1500;
BA_REL_ "GenSigTimeoutTime" BU_SG_REL_ CGW_CCU SG_ 956 BLTN_CAM_MaxRanSet_PMDR 1500;
BA_REL_ "GenSigTimeoutTime" BU_SG_REL_ CGW_CCU SG_ 956 BLTN_CAM_Set_PMDTime 1500;
BA_REL_ "GenSigTimeoutTime" BU_SG_REL_ CGW_CCU SG_ 956 BLTN_CAM_Set_BPR_TM 1500;
BA_REL_ "GenSigTimeoutTime" BU_SG_REL_ CGW_CCU SG_ 956 BLTN_CAM_Set_BPR_RE 1500;
BA_REL_ "GenSigTimeoutTime" BU_SG_REL_ CGW_CCU SG_ 956 BLTN_CAM_BPR_SndRec_Set 1500;
BA_REL_ "GenSigTimeoutTime" BU_SG_REL_ CGW_CCU SG_ 956 BLTN_CAM_BPR_AutRec_Set 1500;
BA_REL_ "GenSigTimeoutTime" BU_SG_REL_ CGW_CCU SG_ 956 BLTN_CAM_RecSet_LPE 1500;
BA_REL_ "GenSigTimeoutTime" BU_SG_REL_ CGW_CCU SG_ 956 BLTN_CAM_Set_Distort_Correct 1500;
BA_REL_ "GenSigTimeoutTime" BU_SG_REL_ CGW_CCU SG_ 956 BLTN_CAM_Set_Pollution_Warn 1500;
BA_REL_ "GenSigTimeoutTime" BU_SG_REL_ CGW_CCU SG_ 956 BLTN_CAM_Set_Crash_Pos 1500;
BA_REL_ "GenSigTimeoutTime" BU_SG_REL_ CGW_CCU SG_ 956 BLTN_CAM_Stm_all 1500;
BA_REL_ "GenSigTimeoutTime" BU_SG_REL_ CGW_CCU SG_ 956 BLTN_CAM_RecSet_OWD 1500;
BA_REL_ "GenSigTimeoutTime" BU_SG_REL_ CGW_CCU SG_ 956 BLTN_CAM_RecSet_DEV 1500;
BA_REL_ "GenSigTimeoutTime" BU_SG_REL_ CGW_CCU SG_ 956 BLTN_CAM_RecSet_OWP 1500;
BA_REL_ "GenSigTimeoutTime" BU_SG_REL_ CGW_CCU SG_ 956 BLTN_CAM_RecSet_PEV 1500;
BA_REL_ "GenSigTimeoutTime" BU_SG_REL_ CGW_CCU SG_ 956 BLTN_CAM_AudRec_Set 1500;
BA_REL_ "GenSigTimeoutTime" BU_SG_REL_ CGW_CCU SG_ 956 BLTN_CAM_Set_Tim_Stm 1500;
BA_REL_ "GenSigTimeoutTime" BU_SG_REL_ CGW_CCU SG_ 956 BLTN_CAM_Set_Spd_Stm 1500;
BA_REL_ "GenSigTimeoutTime" BU_SG_REL_ CGW_CCU SG_ 956 BLTN_CAM_Set_Locatn_Stm 1500;
BA_REL_ "GenSigTimeoutTime" BU_SG_REL_ CGW_CCU SG_ 956 BLTN_CAM_Set_TrnSig_Stm 1500;
BA_REL_ "GenSigTimeoutTime" BU_SG_REL_ CGW_CCU SG_ 956 BLTN_CAM_Set_AclBrk_Stm 1500;
BA_REL_ "GenSigTimeoutTime" BU_SG_REL_ CGW_CCU SG_ 956 BLTN_CAM_Set_GearPos_Stm 1500;
BA_REL_ "GenSigTimeoutTime" BU_SG_REL_ CGW_CCU SG_ 956 BLTN_CAM_Set_EVSen_Stm 1500;
BA_REL_ "GenSigTimeoutTime" BU_SG_REL_ CGW_CCU SG_ 956 BLTN_CAM_Set_StrAngl_Stm 1500;
BA_REL_ "GenSigTimeoutTime" BU_SG_REL_ CGW_CCU SG_ 956 BLTN_CAM_Set_EV_RecMaxTime 1500;
BA_REL_ "GenSigTimeoutTime" BU_SG_REL_ CGW_CCU SG_ 956 BLTN_CAM_RecSet_STRM 1500;
BA_REL_ "GenSigTimeoutTime" BU_SG_REL_ CGW_CCU SG_ 956 BLTN_CAM_Set_PrkTime 1500;
BA_REL_ "GenSigTimeoutTime" BU_SG_REL_ CGW_CCU SG_ 957 BLTN_CAM_Prk_Oprable_Time 1500;
BA_REL_ "GenSigTimeoutTime" BU_SG_REL_ CGW_CCU SG_ 957 BLTN_CAM_Prk_Oprable_Time_Max 1500;
BA_REL_ "GenSigTimeoutTime" BU_SG_REL_ CGW_CCU SG_ 957 BLTN_CAM_AuxBat_Conn_State 1500;
BA_REL_ "GenSigTimeoutTime" BU_SG_REL_ CGW_CCU SG_ 957 BLTN_CAM_AuxBat_CapPer 1500;
BA_REL_ "GenSigTimeoutTime" BU_SG_REL_ CGW_CCU SG_ 957 BLTN_CAM_SWVerMajor 1500;
BA_REL_ "GenSigTimeoutTime" BU_SG_REL_ CGW_CCU SG_ 957 BLTN_CAM_SWVerMinor1 1500;
BA_REL_ "GenSigTimeoutTime" BU_SG_REL_ CGW_CCU SG_ 957 BLTN_CAM_SWVerMinor2 1500;
BA_REL_ "GenSigTimeoutTime" BU_SG_REL_ CGW_CCU SG_ 957 BLTN_CAM_SWVerMinor3 1500;
BA_REL_ "GenSigTimeoutTime" BU_SG_REL_ CGW_CCU SG_ 957 BLTN_CAM_SD_Card_Manufacturer 1500;
BA_REL_ "GenSigTimeoutTime" BU_SG_REL_ CGW_CCU SG_ 957 BLTN_CAM_SD_Card_Cap_Class 1500;
BA_REL_ "GenSigTimeoutTime" BU_SG_REL_ CGW_CCU SG_ 957 BltnCamPlatformStatus 1500;
BA_REL_ "GenSigTimeoutTime" BU_SG_REL_ CGW_CCU SG_ 957 BLTN_CAM_CHInfo 1500;
BA_REL_ "GenSigTimeoutTime" BU_SG_REL_ CGW_CCU SG_ 957 BLTN_CAM_FoDInfo 1500;
BA_REL_ "GenSigTimeoutTime" BU_SG_REL_ CGW_CCU SG_ 957 BLTN_CAM_WiFi_Info_QR 1500;
BA_REL_ "GenSigTimeoutTime" BU_SG_REL_ CGW_CCU SG_ 957 BLTN_CAM_WiFi_Info_IP 1500;
BA_REL_ "GenSigTimeoutTime" BU_SG_REL_ CGW_CCU SG_ 957 BLTN_CAM_DistributeInfo1 1500;
BA_REL_ "GenSigTimeoutTime" BU_SG_REL_ CGW_CCU SG_ 957 BltnCamSTRM_ServiceStatus 1500;
BA_REL_ "GenSigTimeoutTime" BU_SG_REL_ CGW_CCU SG_ 957 BLTN_CAM_PMD_Oprable_Time 1500;
BA_REL_ "GenSigTimeoutTime" BU_SG_REL_ CGW_CCU SG_ 957 BLTN_CAM_PMD_Oprable_Time_Max 1500;
BA_REL_ "GenSigTimeoutTime" BU_SG_REL_ CGW_CCU SG_ 957 BLTN_CAM_RecSta_PMD 1500;
BA_REL_ "GenSigTimeoutTime" BU_SG_REL_ CGW_CCU SG_ 957 BLTN_CAM_RecSta_BPR 1500;
BA_REL_ "GenSigTimeoutTime" BU_SG_REL_ CGW_CCU SG_ 957 BLTN_CAM_BPR_Spprt_Info 1500;
BA_REL_ "GenSigTimeoutTime" BU_SG_REL_ CGW_CCU SG_ 957 BLTN_CAM_PDC_Reset_Opt 1500;
BA_REL_ "GenSigTimeoutTime" BU_SG_REL_ CGW_CCU SG_ 957 BLTN_CAM_RecSta_LPE 1500;
BA_REL_ "GenSigTimeoutTime" BU_SG_REL_ CGW_CCU SG_ 957 BLTN_CAM_DistributeInfo 1500;
BA_REL_ "GenSigTimeoutTime" BU_SG_REL_ CGW_CCU SG_ 957 BLTN_CAM_Sta_STRM 1500;
BA_REL_ "GenSigTimeoutTime" BU_SG_REL_ CGW_CCU SG_ 957 BLTN_CAM_LPE_Option 1500;
BA_REL_ "GenSigTimeoutTime" BU_SG_REL_ CGW_CCU SG_ 957 BLTN_CAM_State 1500;
BA_REL_ "GenSigTimeoutTime" BU_SG_REL_ CGW_CCU SG_ 957 BLTN_CAM_SD_Card_State 1500;
BA_REL_ "GenSigTimeoutTime" BU_SG_REL_ CGW_CCU SG_ 957 BLTN_CAM_RecSta_OWD 1500;
BA_REL_ "GenSigTimeoutTime" BU_SG_REL_ CGW_CCU SG_ 957 BLTN_CAM_RecSta_DEV 1500;
BA_REL_ "GenSigTimeoutTime" BU_SG_REL_ CGW_CCU SG_ 957 BLTN_CAM_RecSta_MAR 1500;
BA_REL_ "GenSigTimeoutTime" BU_SG_REL_ CGW_CCU SG_ 957 BLTN_CAM_RecSta_TML 1500;
BA_REL_ "GenSigTimeoutTime" BU_SG_REL_ CGW_CCU SG_ 957 BLTN_CAM_RecSta_OWP 1500;
BA_REL_ "GenSigTimeoutTime" BU_SG_REL_ CGW_CCU SG_ 957 BLTN_CAM_RecSta_PEV 1500;
BA_REL_ "GenSigTimeoutTime" BU_SG_REL_ CGW_CCU SG_ 957 BLTN_CAM_Prk_EV_Cnt 1500;
BA_REL_ "GenSigTimeoutTime" BU_SG_REL_ CGW_CCU SG_ 957 BLTN_CAM_Prk_Oped_Time 1500;
BA_REL_ "GenSigTimeoutTime" BU_SG_REL_ BLTN_CAM_FD SG_ 686 HU_VehiclePwr 1500;
BA_REL_ "GenSigTimeoutTime" BU_SG_REL_ SGU_FD SG_ 686 HU_VehiclePwr 1500;
BA_REL_ "GenSigTimeoutTime" BU_SG_REL_ BLTN_CAM_FD SG_ 686 HU_PwrState 1500;
BA_REL_ "GenSigTimeoutTime" BU_SG_REL_ GW_PSU_DRV_FD SG_ 274 HU_USM_Crc2Val 0;
BA_REL_ "GenSigTimeoutTime" BU_SG_REL_ ARS_FD SG_ 274 CF_AVN_CluUSMReset 0;
BA_REL_ "GenSigTimeoutTime" BU_SG_REL_ ATS_FD SG_ 274 CF_AVN_CluUSMReset 0;
BA_REL_ "GenSigTimeoutTime" BU_SG_REL_ BLTN_CAM_FD SG_ 274 CF_AVN_CluUSMReset 0;
BA_REL_ "GenSigTimeoutTime" BU_SG_REL_ GW_PSU_3RD_FD SG_ 274 CF_AVN_CluUSMReset 0;
BA_REL_ "GenSigTimeoutTime" BU_SG_REL_ GW_PSU_AST_FD SG_ 274 CF_AVN_CluUSMReset 0;
BA_REL_ "GenSigTimeoutTime" BU_SG_REL_ GW_PSU_DRV_FD SG_ 274 CF_AVN_CluUSMReset 0;
BA_REL_ "GenSigTimeoutTime" BU_SG_REL_ GW_PSU_RL_FD SG_ 274 CF_AVN_CluUSMReset 0;
BA_REL_ "GenSigTimeoutTime" BU_SG_REL_ GW_PSU_RR_FD SG_ 274 CF_AVN_CluUSMReset 0;
BA_REL_ "GenSigTimeoutTime" BU_SG_REL_ GW_SAU_DRV_FD SG_ 274 CF_AVN_CluUSMReset 0;
BA_REL_ "GenSigTimeoutTime" BU_SG_REL_ RCM_FD SG_ 274 CF_AVN_CluUSMReset 0;
BA_REL_ "GenSigTimeoutTime" BU_SG_REL_ RWPC_FD SG_ 274 CF_AVN_CluUSMReset 0;
BA_REL_ "GenSigTimeoutTime" BU_SG_REL_ SGU_FD SG_ 274 CF_AVN_CluUSMReset 0;
BA_REL_ "GenSigTimeoutTime" BU_SG_REL_ SHVU_FRNT_FD SG_ 274 CF_AVN_CluUSMReset 0;
BA_REL_ "GenSigTimeoutTime" BU_SG_REL_ SHVU_REAR_FD SG_ 274 CF_AVN_CluUSMReset 0;
BA_REL_ "GenSigTimeoutTime" BU_SG_REL_ SHVU_RL_FD SG_ 274 CF_AVN_CluUSMReset 0;
BA_REL_ "GenSigTimeoutTime" BU_SG_REL_ SHVU_RR_FD SG_ 274 CF_AVN_CluUSMReset 0;
BA_REL_ "GenSigTimeoutTime" BU_SG_REL_ WPC2_FD SG_ 274 CF_AVN_CluUSMReset 0;
BA_REL_ "GenSigTimeoutTime" BU_SG_REL_ WPC_FD SG_ 274 CF_AVN_CluUSMReset 0;
BA_REL_ "GenSigTimeoutTime" BU_SG_REL_ GW_PSU_DRV_FD SG_ 274 CF_AVN_BodySpprtSet 0;
BA_REL_ "GenSigTimeoutTime" BU_SG_REL_ GW_SAU_DRV_FD SG_ 274 CF_AVN_BodySpprtSet 0;
BA_REL_ "GenSigTimeoutTime" BU_SG_REL_ GW_PSU_DRV_FD SG_ 274 HU_USM_AlvCnt2Val 0;
BA_REL_ "GenSigTimeoutTime" BU_SG_REL_ GW_SAU_DRV_FD SG_ 274 CF_AVN_AirSptTimeNValueSet 0;
BA_REL_ "GenSigTimeoutTime" BU_SG_REL_ GW_SAU_DRV_FD SG_ 274 CF_AVN_AirSptStrNValue 0;
BA_REL_ "GenSigTimeoutTime" BU_SG_REL_ GW_PSU_DRV_FD SG_ 274 CF_AVN_SeatDrvModNValueSet 0;
BA_REL_ "GenSigTimeoutTime" BU_SG_REL_ GW_SAU_DRV_FD SG_ 274 CF_AVN_SeatDrvModNValueSet 0;
BA_REL_ "GenSigTimeoutTime" BU_SG_REL_ ATS_FD SG_ 274 C_MoodLpFadeNValue 0;
BA_REL_ "GenSigTimeoutTime" BU_SG_REL_ BLTN_CAM_FD SG_ 685 HU_WiFi_State 1500;
BA_REL_ "GenSigTimeoutTime" BU_SG_REL_ BLTN_CAM_FD SG_ 685 HU_BLTN_CAM_UI_Mode 1500;
BA_REL_ "GenSigTimeoutTime" BU_SG_REL_ BLTN_CAM_FD SG_ 685 HU_BLTN_CAM_Display 1500;
BA_REL_ "GenSigTimeoutTime" BU_SG_REL_ GW_PSU_DRV_FD SG_ 138 HU_GW_Crc1Val 0;
BA_REL_ "GenSigTimeoutTime" BU_SG_REL_ BLTN_CAM_FD SG_ 138 C_PreCrankReq 0;
BA_REL_ "GenSigTimeoutTime" BU_SG_REL_ GW_PSU_DRV_FD SG_ 138 HU_GW_AlvCnt1Val 0;
BA_REL_ "GenSigTimeoutTime" BU_SG_REL_ GW_PSU_AST_FD SG_ 138 C_TeleAstSeatOpCmdIBOX 0;
BA_REL_ "GenSigTimeoutTime" BU_SG_REL_ SHVU_FRNT_FD SG_ 138 C_TeleAstSeatOpCmdIBOX 0;
BA_REL_ "GenSigTimeoutTime" BU_SG_REL_ GW_PSU_AST_FD SG_ 138 C_TeleDrvSeatOpCmdIBOX 0;
BA_REL_ "GenSigTimeoutTime" BU_SG_REL_ GW_PSU_DRV_FD SG_ 138 C_TeleDrvSeatOpCmdIBOX 0;
BA_REL_ "GenSigTimeoutTime" BU_SG_REL_ SHVU_FRNT_FD SG_ 138 C_TeleDrvSeatOpCmdIBOX 0;
BA_REL_ "GenSigTimeoutTime" BU_SG_REL_ ATS_FD SG_ 138 C_TeleRRSeatOpCmdIBOX 0;
BA_REL_ "GenSigTimeoutTime" BU_SG_REL_ GW_PSU_RL_FD SG_ 138 C_TeleRRSeatOpCmdIBOX 0;
BA_REL_ "GenSigTimeoutTime" BU_SG_REL_ GW_PSU_RR_FD SG_ 138 C_TeleRRSeatOpCmdIBOX 0;
BA_REL_ "GenSigTimeoutTime" BU_SG_REL_ SHVU_FRNT_FD SG_ 138 C_TeleRRSeatOpCmdIBOX 0;
BA_REL_ "GenSigTimeoutTime" BU_SG_REL_ SHVU_REAR_FD SG_ 138 C_TeleRRSeatOpCmdIBOX 0;
BA_REL_ "GenSigTimeoutTime" BU_SG_REL_ SHVU_RR_FD SG_ 138 C_TeleRRSeatOpCmdIBOX 0;
BA_REL_ "GenSigTimeoutTime" BU_SG_REL_ ATS_FD SG_ 138 C_TeleRLSeatOpCmdIBOX 0;
BA_REL_ "GenSigTimeoutTime" BU_SG_REL_ GW_PSU_RL_FD SG_ 138 C_TeleRLSeatOpCmdIBOX 0;
BA_REL_ "GenSigTimeoutTime" BU_SG_REL_ GW_PSU_RR_FD SG_ 138 C_TeleRLSeatOpCmdIBOX 0;
BA_REL_ "GenSigTimeoutTime" BU_SG_REL_ SHVU_FRNT_FD SG_ 138 C_TeleRLSeatOpCmdIBOX 0;
BA_REL_ "GenSigTimeoutTime" BU_SG_REL_ SHVU_REAR_FD SG_ 138 C_TeleRLSeatOpCmdIBOX 0;
BA_REL_ "GenSigTimeoutTime" BU_SG_REL_ SHVU_RL_FD SG_ 138 C_TeleRLSeatOpCmdIBOX 0;
VAL_ 956 BLTN_CAM_FD_Crc2Val 0 "0x0~0xFFFF:CRCValue" 65535 "0x0~0xFFFF:CRCValue" ;
VAL_ 956 BLTN_CAM_Set_EV_BfrTime 0 "10~20 sec" 1 "10~20 sec" 2 "10~20 sec" 3 "10~20 sec" 4 "10~20 sec" 5 "10~20 sec" 6 "10~20 sec" 7 "10~20 sec" 8 "10~20 sec" 9 "10~20 sec" 10 "10~20 sec" 11 "Reserved" 12 "Reserved" 13 "Reserved" 14 "Reserved" 15 "Reserved" 16 "Reserved" 17 "Reserved" 18 "Reserved" 19 "Reserved" 20 "Reserved" 21 "Reserved" 22 "Reserved" 23 "Reserved" 24 "Reserved" 25 "Reserved" 26 "Reserved" 27 "Reserved" 28 "Reserved" 29 "Reserved" 30 "Reserved" 31 "Invalid" ;
VAL_ 956 BLTN_CAM_Set_EV_AftTime 0 "10~20 sec" 1 "10~20 sec" 2 "10~20 sec" 3 "10~20 sec" 4 "10~20 sec" 5 "10~20 sec" 6 "10~20 sec" 7 "10~20 sec" 8 "10~20 sec" 9 "10~20 sec" 10 "10~20 sec" 11 "Reserved" 12 "Reserved" 13 "Reserved" 14 "Reserved" 15 "Reserved" 16 "Reserved" 17 "Reserved" 18 "Reserved" 19 "Reserved" 20 "Reserved" 21 "Reserved" 22 "Reserved" 23 "Reserved" 24 "Reserved" 25 "Reserved" 26 "Reserved" 27 "Reserved" 28 "Reserved" 29 "Reserved" 30 "Reserved" 31 "Invalid" ;
VAL_ 956 BLTN_CAM_Set_Drv_TML_Int 0 "Default" 1 "1~ 10 sec" 2 "1~ 10 sec" 3 "1~ 10 sec" 4 "1~ 10 sec" 5 "1~ 10 sec" 6 "1~ 10 sec" 7 "1~ 10 sec" 8 "1~ 10 sec" 9 "1~ 10 sec" 10 "1~ 10 sec" 11 "Reserved" 12 "Reserved" 13 "Reserved" 14 "Reserved" 15 "Invalid" ;
VAL_ 956 BLTN_CAM_SenSet_DEV 0 "Default" 1 "Level 1" 2 "Level 2" 3 "Level 3" 4 "Level 4" 5 "Level 5" 6 "Reserved" 7 "Reserved" 8 "Reserved" 9 "Reserved" 10 "Reserved" 11 "Reserved" 12 "Reserved" 13 "Reserved" 14 "Reserved" 15 "Invalid" ;
VAL_ 956 BLTN_CAM_SenSet_PEV 0 "Default" 1 "Level 1" 2 "Level 2" 3 "Level 3" 4 "Level 4" 5 "Level 5" 6 "Reserved" 7 "Reserved" 8 "Reserved" 9 "Reserved" 10 "Reserved" 11 "Reserved" 12 "Reserved" 13 "Reserved" 14 "Reserved" 15 "Invalid" ;
VAL_ 956 BLTN_CAM_Set_FR_Ver_Pos 0 "Mid" 1 "Upper Level (1 ~ 10)" 2 "Upper Level (1 ~ 10)" 3 "Upper Level (1 ~ 10)" 4 "Upper Level (1 ~ 10)" 5 "Upper Level (1 ~ 10)" 6 "Upper Level (1 ~ 10)" 7 "Upper Level (1 ~ 10)" 8 "Upper Level (1 ~ 10)" 9 "Upper Level (1 ~ 10)" 10 "Upper Level (1 ~ 10)" 11 "Reserved" 12 "Reserved" 13 "Reserved" 14 "Reserved" 15 "Reserved" 16 "Reserved" 17 "Lower Level (-1 ~ -10)" 18 "Lower Level (-1 ~ -10)" 19 "Lower Level (-1 ~ -10)" 20 "Lower Level (-1 ~ -10)" 21 "Lower Level (-1 ~ -10)" 22 "Lower Level (-1 ~ -10)" 23 "Lower Level (-1 ~ -10)" 24 "Lower Level (-1 ~ -10)" 25 "Lower Level (-1 ~ -10)" 26 "Lower Level (-1 ~ -10)" 27 "Reserved" 28 "Reserved" 29 "Reserved" 30 "Reserved" 31 "Invalid" ;
VAL_ 956 BLTN_CAM_Set_RR_Ver_Pos 0 "Mid" 1 "Upper Level (1 ~ 10)" 2 "Upper Level (1 ~ 10)" 3 "Upper Level (1 ~ 10)" 4 "Upper Level (1 ~ 10)" 5 "Upper Level (1 ~ 10)" 6 "Upper Level (1 ~ 10)" 7 "Upper Level (1 ~ 10)" 8 "Upper Level (1 ~ 10)" 9 "Upper Level (1 ~ 10)" 10 "Upper Level (1 ~ 10)" 11 "Reserved" 12 "Reserved" 13 "Reserved" 14 "Reserved" 15 "Reserved" 16 "Reserved" 17 "Lower Level (-1 ~ -10)" 18 "Lower Level (-1 ~ -10)" 19 "Lower Level (-1 ~ -10)" 20 "Lower Level (-1 ~ -10)" 21 "Lower Level (-1 ~ -10)" 22 "Lower Level (-1 ~ -10)" 23 "Lower Level (-1 ~ -10)" 24 "Lower Level (-1 ~ -10)" 25 "Lower Level (-1 ~ -10)" 26 "Lower Level (-1 ~ -10)" 27 "Reserved" 28 "Reserved" 29 "Reserved" 30 "Reserved" 31 "Invalid" ;
VAL_ 956 BLTN_CAM_Set_PEV_AppNoti 0 "Default" 1 "Off" 2 "On" 3 "Invalid" ;
VAL_ 956 BLTN_CAM_Set_WiFi_AutoOn 0 "Default" 1 "Off" 2 "On" 3 "Invalid" ;
VAL_ 956 BLTN_CAM_StrgPropSet 0 "Normal" 1 "On While Recordings" 2 "On While Parked" 3 "Driving Events" 4 "Parked Events" 5 "Reserved" 6 "Reserved" 7 "Reserved" 8 "Reserved" 9 "Reserved" 10 "Reserved" 11 "Reserved" 12 "Reserved" 13 "Reserved" 14 "Reserved" 15 "Invalid" ;
VAL_ 956 BLTN_CAM_File_DEL_CPY_Op_State 0 "Default" 1 "On Deleting" 2 "On Copying" 3 "operation completed" 4 "pausing the operation" 5 "operation canceled" 6 "Reserved" 7 "Reserved" 8 "Reserved" 9 "Reserved" 10 "Delete Error, No file(s)" 11 "Copy Error, No file(s)" 12 "Copy Error, Not enough target stroage space." 13 "The space not existed(not mounted)" 14 "the commend file is wrong." 15 "Invalid" ;
VAL_ 956 BLTN_CAM_File_DEL_CPY_NumTot 0 "Default" 1 "001~0xFFFB:Number of files" 65531 "001~0xFFFB:Number of files" 65532 "not operated" 65533 "The space not existed(not mounted)" 65534 "Not enough space" 65535 "Invalid" ;
VAL_ 956 BLTN_CAM_FD_AlvCnt2Val 0 "0x0~0xFF:AlvCntValue" 255 "0x0~0xFF:AlvCntValue" ;
VAL_ 956 BLTN_CAM_File_DEL_CPYed_Num 0 "Default" 1 "001~0xFFFB:Number of files" 65531 "001~0xFFFB:Number of files" 65532 "not operated" 65533 "The space not existed(not mounted)" 65534 "Not enough space" 65535 "Invalid" ;
VAL_ 956 VAPI_BltnCamInsideSwEnable_Get 0 "Default" 1 "Enable" 2 "Disable" 3 "Error indicator" ;
VAL_ 956 BLTN_CAM_Set_PMD 0 "Default" 1 "Off" 2 "On" 3 "Invalid" ;
VAL_ 956 BLTN_CAM_Set_PMDEV 0 "Default" 1 "Off" 2 "On" 3 "Invalid" ;
VAL_ 956 BLTN_CAM_RanSet_PMDR 0 "Default" 1 "Level 1" 2 "Level 2" 3 "Level 3" 4 "Level 4" 5 "Level 5" 6 "RESERVED" 7 "RESERVED" 8 "RESERVED" 9 "RESERVED" 10 "RESERVED" 11 "RESERVED" 12 "RESERVED" 13 "RESERVED" 14 "RESERVED" 15 "Invalid" ;
VAL_ 956 BLTN_CAM_MaxRanSet_PMDR 0 "Default" 1 "RESERVED" 2 "Level 1~2" 3 "Level 1~3" 4 "Level 1~4" 5 "Level 1~5" 6 "RESERVED" 7 "RESERVED" 8 "RESERVED" 9 "RESERVED" 10 "RESERVED" 11 "RESERVED" 12 "RESERVED" 13 "RESERVED" 14 "RESERVED" 15 "Invalid" ;
VAL_ 956 BLTN_CAM_Set_PMDTime 0 "Default" 1 "1~0xFB:1 ~ 251 hr" 251 "1~0xFB:1 ~ 251 hr" 252 "RESERVED" 253 "RESERVED" 254 "Not Supported" 255 "Invalid" ;
VAL_ 956 BLTN_CAM_Set_BPR_TM 0 "Default" 1 "Track Mode 1" 2 "Track Mode 2" 3 "Track Mode 3" 4 "Track Mode 4" 5 "0x5 ~ 0x6 : Reserved" 6 "0x5 ~ 0x6 : Reserved" 7 "0x7: invalid" ;
VAL_ 956 BLTN_CAM_Set_BPR_RE 0 "Default" 1 "Resolution Mode 1" 2 "Resolution Mode 2" 3 "Resolution Mode 3" 4 "Resolution Mode 4" 5 "RESERVED" 6 "RESERVED" 7 "Invalid" ;
VAL_ 956 BLTN_CAM_BPR_SndRec_Set 0 "Default" 1 "Off" 2 "On" 3 "Invalid" ;
VAL_ 956 BLTN_CAM_BPR_AutRec_Set 0 "Default" 1 "Off" 2 "On" 3 "Invalid" ;
VAL_ 956 BLTN_CAM_RecSet_LPE 0 "Default" 1 "Off" 2 "On" 3 "Invalid" ;
VAL_ 956 BLTN_CAM_Set_Distort_Correct 0 "Default" 1 "Off" 2 "On" 3 "Invalid" ;
VAL_ 956 BLTN_CAM_Set_Pollution_Warn 0 "Default" 1 "Off" 2 "On" 3 "Invalid" ;
VAL_ 956 BLTN_CAM_Set_Crash_Pos 0 "Default" 1 "Off" 2 "On" 3 "Invalid" ;
VAL_ 956 BLTN_CAM_Stm_all 0 "Default" 1 "Off" 2 "On" 3 "Invalid" ;
VAL_ 956 BLTN_CAM_RecSet_OWD 0 "Default" 1 "Off" 2 "On" 3 "Invalid" ;
VAL_ 956 BLTN_CAM_RecSet_DEV 0 "Default" 1 "Off" 2 "On" 3 "Invalid" ;
VAL_ 956 BLTN_CAM_RecSet_OWP 0 "Default" 1 "Off" 2 "On" 3 "Invalid" ;
VAL_ 956 BLTN_CAM_RecSet_PEV 0 "Default" 1 "Off" 2 "On" 3 "Invalid" ;
VAL_ 956 BLTN_CAM_AudRec_Set 0 "Default" 1 "Off" 2 "On" 3 "Invalid" ;
VAL_ 956 BLTN_CAM_Set_Tim_Stm 0 "Default" 1 "Off" 2 "On" 3 "Invalid" ;
VAL_ 956 BLTN_CAM_Set_Spd_Stm 0 "Default" 1 "Off" 2 "On" 3 "Invalid" ;
VAL_ 956 BLTN_CAM_Set_Locatn_Stm 0 "Default" 1 "Off" 2 "On" 3 "Invalid" ;
VAL_ 956 BLTN_CAM_Set_TrnSig_Stm 0 "Default" 1 "Off" 2 "On" 3 "Invalid" ;
VAL_ 956 BLTN_CAM_Set_AclBrk_Stm 0 "Default" 1 "Off" 2 "On" 3 "Invalid" ;
VAL_ 956 BLTN_CAM_Set_GearPos_Stm 0 "Default" 1 "Off" 2 "On" 3 "Invalid" ;
VAL_ 956 BLTN_CAM_Set_EVSen_Stm 0 "Default" 1 "Off" 2 "On" 3 "Invalid" ;
VAL_ 956 BLTN_CAM_Set_StrAngl_Stm 0 "Default" 1 "Off" 2 "On" 3 "Invalid" ;
VAL_ 956 BLTN_CAM_Set_EV_RecMaxTime 0 "Default" 1 "Off" 2 "On" 3 "Default" ;
VAL_ 956 BLTN_CAM_RecSet_STRM 0 "Default" 1 "Off" 2 "On" 3 "Invalid" ;
VAL_ 956 BLTN_CAM_Set_PrkTime 0 "Default" 1 "01~0xFB: 1~ 251 hr" 251 "01~0xFB: 1~ 251 hr" 252 "Motion Detection Record Mode" 253 "RESERVED" 254 "Not Supported" 255 "Invalid" ;
VAL_ 957 BLTN_CAM_FD_STAT_Crc1Val 0 "0x0~0xFFFF:CRCValue" 65535 "0x0~0xFFFF:CRCValue" ;
VAL_ 957 BLTN_CAM_Prk_Oprable_Time 0 "0x0~0xFB:the hours of Park Mode Operatable" 251 "0x0~0xFB:the hours of Park Mode Operatable" 252 "Motion Detection Record Mode" 253 "Auxiliary Battery is not connected. - Auxiliary Battery applicable on this vehicle model" 254 "Aux. Bat. is not connected. ? Aux. Bat. not applicable  or Not provide Park Mode Operation" 255 "Invalid" ;
VAL_ 957 BLTN_CAM_Prk_Oprable_Time_Max 0 "0x0~0xFB:the hours of Park Mode Operatable" 251 "0x0~0xFB:the hours of Park Mode Operatable" 252 "RESERVED" 253 "Auxiliary Battery is not connected. - Auxiliary Battery applicable on this vehicle model" 254 "Aux. Bat. is not connected. ? Aux. Bat. not applicable  or Not provide Park Mode Operation" 255 "Invalid" ;
VAL_ 957 BLTN_CAM_AuxBat_Conn_State 0 "Default" 1 "Park Mode Operation Available (Aux. Bat. is connected(P-LBM or B-LBM) or Low Voltage battery Use.)" 2 "Auxiliary Battery is not connected. - Auxiliary Battery applicable on this vehicle model" 3 "Aux. Bat. is not connected. ? Aux. Bat. not applicable  or Not provide Park Mode Operation" ;
VAL_ 957 BLTN_CAM_AuxBat_CapPer 0 "0x0~0x64: Aux Bat Capacity Percent(0~100%)" 100 "0x0~0x64: Aux Bat Capacity Percent(0~100%)" 100 "Reserved" 101 "Reserved" 102 "Reserved" 103 "Reserved" 104 "Reserved" 105 "Reserved" 106 "Reserved" 107 "Reserved" 108 "Reserved" 109 "Reserved" 110 "Reserved" 111 "Reserved" 112 "Reserved" 113 "Reserved" 114 "Reserved" 115 "Reserved" 116 "Reserved" 117 "Reserved" 118 "Reserved" 119 "Reserved" 120 "Reserved" 121 "Reserved" 122 "Reserved" 123 "Reserved" 124 "Reserved" 125 "Reserved" 126 "Reserved" 127 "Invalid" ;
VAL_ 957 BLTN_CAM_ResetOpSta 0 "Normal" 1 "Reset Complete" 2 "Reset Fail" 3 "RESERVED" ;
VAL_ 957 BLTN_CAM_SWVerMajor 0 "ASCII Code Value (HEX)" 1 "ASCII Code Value (HEX)" 2 "ASCII Code Value (HEX)" 3 "ASCII Code Value (HEX)" 4 "ASCII Code Value (HEX)" 5 "ASCII Code Value (HEX)" 6 "ASCII Code Value (HEX)" 7 "ASCII Code Value (HEX)" 8 "ASCII Code Value (HEX)" 9 "ASCII Code Value (HEX)" 10 "ASCII Code Value (HEX)" 11 "ASCII Code Value (HEX)" 12 "ASCII Code Value (HEX)" 13 "ASCII Code Value (HEX)" 14 "ASCII Code Value (HEX)" 15 "ASCII Code Value (HEX)" ;
VAL_ 957 BLTN_CAM_SWVerMinor1 0 "Minor1 version, 0~99 dec" 1 "Minor1 version, 0~99 dec" 2 "Minor1 version, 0~99 dec" 3 "Minor1 version, 0~99 dec" 4 "Minor1 version, 0~99 dec" 5 "Minor1 version, 0~99 dec" 6 "Minor1 version, 0~99 dec" 7 "Minor1 version, 0~99 dec" 8 "Minor1 version, 0~99 dec" 9 "Minor1 version, 0~99 dec" 10 "Minor1 version, 0~99 dec" 11 "Minor1 version, 0~99 dec" 12 "Minor1 version, 0~99 dec" 13 "Minor1 version, 0~99 dec" 14 "Minor1 version, 0~99 dec" 15 "Minor1 version, 0~99 dec" 16 "Minor1 version, 0~99 dec" 17 "Minor1 version, 0~99 dec" 18 "Minor1 version, 0~99 dec" 19 "Minor1 version, 0~99 dec" 20 "Minor1 version, 0~99 dec" 21 "Minor1 version, 0~99 dec" 22 "Minor1 version, 0~99 dec" 23 "Minor1 version, 0~99 dec" 24 "Minor1 version, 0~99 dec" 25 "Minor1 version, 0~99 dec" 26 "Minor1 version, 0~99 dec" 27 "Minor1 version, 0~99 dec" 28 "Minor1 version, 0~99 dec" 29 "Minor1 version, 0~99 dec" 30 "Minor1 version, 0~99 dec" 31 "Minor1 version, 0~99 dec" 32 "Minor1 version, 0~99 dec" 33 "Minor1 version, 0~99 dec" 34 "Minor1 version, 0~99 dec" 35 "Minor1 version, 0~99 dec" 36 "Minor1 version, 0~99 dec" 37 "Minor1 version, 0~99 dec" 38 "Minor1 version, 0~99 dec" 39 "Minor1 version, 0~99 dec" 40 "Minor1 version, 0~99 dec" 41 "Minor1 version, 0~99 dec" 42 "Minor1 version, 0~99 dec" 43 "Minor1 version, 0~99 dec" 44 "Minor1 version, 0~99 dec" 45 "Minor1 version, 0~99 dec" 46 "Minor1 version, 0~99 dec" 47 "Minor1 version, 0~99 dec" 48 "Minor1 version, 0~99 dec" 49 "Minor1 version, 0~99 dec" 50 "Minor1 version, 0~99 dec" 51 "Minor1 version, 0~99 dec" 52 "Minor1 version, 0~99 dec" 53 "Minor1 version, 0~99 dec" 54 "Minor1 version, 0~99 dec" 55 "Minor1 version, 0~99 dec" 56 "Minor1 version, 0~99 dec" 57 "Minor1 version, 0~99 dec" 58 "Minor1 version, 0~99 dec" 59 "Minor1 version, 0~99 dec" 60 "Minor1 version, 0~99 dec" 61 "Minor1 version, 0~99 dec" 62 "Minor1 version, 0~99 dec" 63 "Minor1 version, 0~99 dec" 64 "Minor1 version, 0~99 dec" 65 "Minor1 version, 0~99 dec" 66 "Minor1 version, 0~99 dec" 67 "Minor1 version, 0~99 dec" 68 "Minor1 version, 0~99 dec" 69 "Minor1 version, 0~99 dec" 70 "Minor1 version, 0~99 dec" 71 "Minor1 version, 0~99 dec" 72 "Minor1 version, 0~99 dec" 73 "Minor1 version, 0~99 dec" 74 "Minor1 version, 0~99 dec" 75 "Minor1 version, 0~99 dec" 76 "Minor1 version, 0~99 dec" 77 "Minor1 version, 0~99 dec" 78 "Minor1 version, 0~99 dec" 79 "Minor1 version, 0~99 dec" 80 "Minor1 version, 0~99 dec" 81 "Minor1 version, 0~99 dec" 82 "Minor1 version, 0~99 dec" 83 "Minor1 version, 0~99 dec" 84 "Minor1 version, 0~99 dec" 85 "Minor1 version, 0~99 dec" 86 "Minor1 version, 0~99 dec" 87 "Minor1 version, 0~99 dec" 88 "Minor1 version, 0~99 dec" 89 "Minor1 version, 0~99 dec" 90 "Minor1 version, 0~99 dec" 91 "Minor1 version, 0~99 dec" 92 "Minor1 version, 0~99 dec" 93 "Minor1 version, 0~99 dec" 94 "Minor1 version, 0~99 dec" 95 "Minor1 version, 0~99 dec" 96 "Minor1 version, 0~99 dec" 97 "Minor1 version, 0~99 dec" 98 "Minor1 version, 0~99 dec" 99 "Minor1 version, 0~99 dec" 100 "Reserved" 101 "Reserved" 102 "Reserved" 103 "Reserved" 104 "Reserved" 105 "Reserved" 106 "Reserved" 107 "Reserved" 108 "Reserved" 109 "Reserved" 110 "Reserved" 111 "Reserved" 112 "Reserved" 113 "Reserved" 114 "Reserved" 115 "Reserved" 116 "Reserved" 117 "Reserved" 118 "Reserved" 119 "Reserved" 120 "Reserved" 121 "Reserved" 122 "Reserved" 123 "Reserved" 124 "Reserved" 125 "Reserved" 126 "Reserved" 127 "Invalid" ;
VAL_ 957 BLTN_CAM_SWVerMinor2 0 "Minor2 verion, 0~99 dec" 1 "Minor2 verion, 0~99 dec" 2 "Minor2 verion, 0~99 dec" 3 "Minor2 verion, 0~99 dec" 4 "Minor2 verion, 0~99 dec" 5 "Minor2 verion, 0~99 dec" 6 "Minor2 verion, 0~99 dec" 7 "Minor2 verion, 0~99 dec" 8 "Minor2 verion, 0~99 dec" 9 "Minor2 verion, 0~99 dec" 10 "Minor2 verion, 0~99 dec" 11 "Minor2 verion, 0~99 dec" 12 "Minor2 verion, 0~99 dec" 13 "Minor2 verion, 0~99 dec" 14 "Minor2 verion, 0~99 dec" 15 "Minor2 verion, 0~99 dec" 16 "Minor2 verion, 0~99 dec" 17 "Minor2 verion, 0~99 dec" 18 "Minor2 verion, 0~99 dec" 19 "Minor2 verion, 0~99 dec" 20 "Minor2 verion, 0~99 dec" 21 "Minor2 verion, 0~99 dec" 22 "Minor2 verion, 0~99 dec" 23 "Minor2 verion, 0~99 dec" 24 "Minor2 verion, 0~99 dec" 25 "Minor2 verion, 0~99 dec" 26 "Minor2 verion, 0~99 dec" 27 "Minor2 verion, 0~99 dec" 28 "Minor2 verion, 0~99 dec" 29 "Minor2 verion, 0~99 dec" 30 "Minor2 verion, 0~99 dec" 31 "Minor2 verion, 0~99 dec" 32 "Minor2 verion, 0~99 dec" 33 "Minor2 verion, 0~99 dec" 34 "Minor2 verion, 0~99 dec" 35 "Minor2 verion, 0~99 dec" 36 "Minor2 verion, 0~99 dec" 37 "Minor2 verion, 0~99 dec" 38 "Minor2 verion, 0~99 dec" 39 "Minor2 verion, 0~99 dec" 40 "Minor2 verion, 0~99 dec" 41 "Minor2 verion, 0~99 dec" 42 "Minor2 verion, 0~99 dec" 43 "Minor2 verion, 0~99 dec" 44 "Minor2 verion, 0~99 dec" 45 "Minor2 verion, 0~99 dec" 46 "Minor2 verion, 0~99 dec" 47 "Minor2 verion, 0~99 dec" 48 "Minor2 verion, 0~99 dec" 49 "Minor2 verion, 0~99 dec" 50 "Minor2 verion, 0~99 dec" 51 "Minor2 verion, 0~99 dec" 52 "Minor2 verion, 0~99 dec" 53 "Minor2 verion, 0~99 dec" 54 "Minor2 verion, 0~99 dec" 55 "Minor2 verion, 0~99 dec" 56 "Minor2 verion, 0~99 dec" 57 "Minor2 verion, 0~99 dec" 58 "Minor2 verion, 0~99 dec" 59 "Minor2 verion, 0~99 dec" 60 "Minor2 verion, 0~99 dec" 61 "Minor2 verion, 0~99 dec" 62 "Minor2 verion, 0~99 dec" 63 "Minor2 verion, 0~99 dec" 64 "Minor2 verion, 0~99 dec" 65 "Minor2 verion, 0~99 dec" 66 "Minor2 verion, 0~99 dec" 67 "Minor2 verion, 0~99 dec" 68 "Minor2 verion, 0~99 dec" 69 "Minor2 verion, 0~99 dec" 70 "Minor2 verion, 0~99 dec" 71 "Minor2 verion, 0~99 dec" 72 "Minor2 verion, 0~99 dec" 73 "Minor2 verion, 0~99 dec" 74 "Minor2 verion, 0~99 dec" 75 "Minor2 verion, 0~99 dec" 76 "Minor2 verion, 0~99 dec" 77 "Minor2 verion, 0~99 dec" 78 "Minor2 verion, 0~99 dec" 79 "Minor2 verion, 0~99 dec" 80 "Minor2 verion, 0~99 dec" 81 "Minor2 verion, 0~99 dec" 82 "Minor2 verion, 0~99 dec" 83 "Minor2 verion, 0~99 dec" 84 "Minor2 verion, 0~99 dec" 85 "Minor2 verion, 0~99 dec" 86 "Minor2 verion, 0~99 dec" 87 "Minor2 verion, 0~99 dec" 88 "Minor2 verion, 0~99 dec" 89 "Minor2 verion, 0~99 dec" 90 "Minor2 verion, 0~99 dec" 91 "Minor2 verion, 0~99 dec" 92 "Minor2 verion, 0~99 dec" 93 "Minor2 verion, 0~99 dec" 94 "Minor2 verion, 0~99 dec" 95 "Minor2 verion, 0~99 dec" 96 "Minor2 verion, 0~99 dec" 97 "Minor2 verion, 0~99 dec" 98 "Minor2 verion, 0~99 dec" 99 "Minor2 verion, 0~99 dec" 100 "Reserved" 101 "Reserved" 102 "Reserved" 103 "Reserved" 104 "Reserved" 105 "Reserved" 106 "Reserved" 107 "Reserved" 108 "Reserved" 109 "Reserved" 110 "Reserved" 111 "Reserved" 112 "Reserved" 113 "Reserved" 114 "Reserved" 115 "Reserved" 116 "Reserved" 117 "Reserved" 118 "Reserved" 119 "Reserved" 120 "Reserved" 121 "Reserved" 122 "Reserved" 123 "Reserved" 124 "Reserved" 125 "Reserved" 126 "Reserved" 127 "Invalid" ;
VAL_ 957 BLTN_CAM_SWVerMinor3 0 "Minor3 version, 0~99 dec" 1 "Minor3 version, 0~99 dec" 2 "Minor3 version, 0~99 dec" 3 "Minor3 version, 0~99 dec" 4 "Minor3 version, 0~99 dec" 5 "Minor3 version, 0~99 dec" 6 "Minor3 version, 0~99 dec" 7 "Minor3 version, 0~99 dec" 8 "Minor3 version, 0~99 dec" 9 "Minor3 version, 0~99 dec" 10 "Minor3 version, 0~99 dec" 11 "Minor3 version, 0~99 dec" 12 "Minor3 version, 0~99 dec" 13 "Minor3 version, 0~99 dec" 14 "Minor3 version, 0~99 dec" 15 "Minor3 version, 0~99 dec" 16 "Minor3 version, 0~99 dec" 17 "Minor3 version, 0~99 dec" 18 "Minor3 version, 0~99 dec" 19 "Minor3 version, 0~99 dec" 20 "Minor3 version, 0~99 dec" 21 "Minor3 version, 0~99 dec" 22 "Minor3 version, 0~99 dec" 23 "Minor3 version, 0~99 dec" 24 "Minor3 version, 0~99 dec" 25 "Minor3 version, 0~99 dec" 26 "Minor3 version, 0~99 dec" 27 "Minor3 version, 0~99 dec" 28 "Minor3 version, 0~99 dec" 29 "Minor3 version, 0~99 dec" 30 "Minor3 version, 0~99 dec" 31 "Minor3 version, 0~99 dec" 32 "Minor3 version, 0~99 dec" 33 "Minor3 version, 0~99 dec" 34 "Minor3 version, 0~99 dec" 35 "Minor3 version, 0~99 dec" 36 "Minor3 version, 0~99 dec" 37 "Minor3 version, 0~99 dec" 38 "Minor3 version, 0~99 dec" 39 "Minor3 version, 0~99 dec" 40 "Minor3 version, 0~99 dec" 41 "Minor3 version, 0~99 dec" 42 "Minor3 version, 0~99 dec" 43 "Minor3 version, 0~99 dec" 44 "Minor3 version, 0~99 dec" 45 "Minor3 version, 0~99 dec" 46 "Minor3 version, 0~99 dec" 47 "Minor3 version, 0~99 dec" 48 "Minor3 version, 0~99 dec" 49 "Minor3 version, 0~99 dec" 50 "Minor3 version, 0~99 dec" 51 "Minor3 version, 0~99 dec" 52 "Minor3 version, 0~99 dec" 53 "Minor3 version, 0~99 dec" 54 "Minor3 version, 0~99 dec" 55 "Minor3 version, 0~99 dec" 56 "Minor3 version, 0~99 dec" 57 "Minor3 version, 0~99 dec" 58 "Minor3 version, 0~99 dec" 59 "Minor3 version, 0~99 dec" 60 "Minor3 version, 0~99 dec" 61 "Minor3 version, 0~99 dec" 62 "Minor3 version, 0~99 dec" 63 "Minor3 version, 0~99 dec" 64 "Minor3 version, 0~99 dec" 65 "Minor3 version, 0~99 dec" 66 "Minor3 version, 0~99 dec" 67 "Minor3 version, 0~99 dec" 68 "Minor3 version, 0~99 dec" 69 "Minor3 version, 0~99 dec" 70 "Minor3 version, 0~99 dec" 71 "Minor3 version, 0~99 dec" 72 "Minor3 version, 0~99 dec" 73 "Minor3 version, 0~99 dec" 74 "Minor3 version, 0~99 dec" 75 "Minor3 version, 0~99 dec" 76 "Minor3 version, 0~99 dec" 77 "Minor3 version, 0~99 dec" 78 "Minor3 version, 0~99 dec" 79 "Minor3 version, 0~99 dec" 80 "Minor3 version, 0~99 dec" 81 "Minor3 version, 0~99 dec" 82 "Minor3 version, 0~99 dec" 83 "Minor3 version, 0~99 dec" 84 "Minor3 version, 0~99 dec" 85 "Minor3 version, 0~99 dec" 86 "Minor3 version, 0~99 dec" 87 "Minor3 version, 0~99 dec" 88 "Minor3 version, 0~99 dec" 89 "Minor3 version, 0~99 dec" 90 "Minor3 version, 0~99 dec" 91 "Minor3 version, 0~99 dec" 92 "Minor3 version, 0~99 dec" 93 "Minor3 version, 0~99 dec" 94 "Minor3 version, 0~99 dec" 95 "Minor3 version, 0~99 dec" 96 "Minor3 version, 0~99 dec" 97 "Minor3 version, 0~99 dec" 98 "Minor3 version, 0~99 dec" 99 "Minor3 version, 0~99 dec" 100 "Reserved" 101 "Reserved" 102 "Reserved" 103 "Reserved" 104 "Reserved" 105 "Reserved" 106 "Reserved" 107 "Reserved" 108 "Reserved" 109 "Reserved" 110 "Reserved" 111 "Reserved" 112 "Reserved" 113 "Reserved" 114 "Reserved" 115 "Reserved" 116 "Reserved" 117 "Reserved" 118 "Reserved" 119 "Reserved" 120 "Reserved" 121 "Reserved" 122 "Reserved" 123 "Reserved" 124 "Reserved" 125 "Reserved" 126 "Reserved" 127 "Invalid" ;
VAL_ 957 BLTN_CAM_FD_STAT_AlvCnt1Val 0 "0x0~0xFF:AlvCntValue" 255 "0x0~0xFF:AlvCntValue" ;
VAL_ 957 BLTN_CAM_SD_Card_Manufacturer 0 "SD Card not found" 1 "Micron-Genuine part" 2 "RESERVED" 3 "RESERVED" 4 "RESERVED" 5 "RESERVED" 6 "Unknown" 7 "Invalid" ;
VAL_ 957 BLTN_CAM_SD_Card_Cap_Class 0 "SD Card not found" 1 "64Gbyte Class" 2 "128Gbyte Class" 3 "256Gbyte Class" 4 "512Gbyte Class" 5 "1Tbyte Class" 6 "2Tbyte Class" 7 "Invalid" ;
VAL_ 957 BltnCamPlatformStatus 0 "DEFAULT // UNKNOWN status for initialization" 1 "AVAILABLE - BLTN_CAM 2 or BLTN_CAM 2 Plus available" 2 "VAILABLE - BLTN_CAM 2 or BLTN_CAM 2 Plus available - Optional" 3 "AVAILABLE _BLTN_CAM 3 available" 4 "RESERVED" 5 "RESERVED" 6 "RESERVED" 7 "RESERVED" 8 "RESERVED" 9 "RESERVED" 10 "RESERVED" 11 "RESERVED" 12 "RESERVED" 13 "RESERVED" 14 "RESERVED" 15 "Inavalid" ;
VAL_ 957 BLTN_CAM_CHInfo 0 "Default" 1 "2CH Front_Rear" 2 "4CH Fron_Rear,_Left_Right" 3 "RESERVED" 4 "RESERVED" 5 "RESERVED" 6 "RESERVED" 7 "RESERVED" 8 "RESERVED" 9 "RESERVED" 10 "RESERVED" 11 "RESERVED" 12 "RESERVED" 13 "RESERVED" 14 "RESERVED" 15 "Invalid" ;
VAL_ 957 BLTN_CAM_FoDInfo 0 "Default" 1 "FoD Cloud Activated(Applied)" 2 "FoD Deactivated(Not Applied)" 3 "RESERVED" 4 "RESERVED" 5 "RESERVED" 6 "RESERVED" 7 "RESERVED" 8 "RESERVED" 9 "RESERVED" 10 "RESERVED" 11 "RESERVED" 12 "RESERVED" 13 "RESERVED" 14 "RESERVED" 15 "Invalid" ;
VAL_ 957 BLTN_CAM_WiFi_Info_QR 0 "Default" 1 "No_QR" 2 "QR_Support" 3 "Invalid" ;
VAL_ 957 BLTN_CAM_WiFi_Info_IP 0 "Default" 1 "IP 192.168.x.1 (x : 1 or 2 or 3)" 2 "IP 192.168.128.200" 3 "RESERVED" 4 "RESERVED" 5 "RESERVED" 6 "RESERVED" 7 "Invalid" ;
VAL_ 957 BLTN_CAM_DistributeInfo1 0 "Default (Korea)" 1 "Korea (KOR) Type" 2 "General Type" 3 "Middle East (MES) Type" 4 "Europe (EUR) Type" 5 "Australia (AUS) Type" 6 "Canada Type(CAN)" 7 "North America?(NA) Type" 8 "China?(CHN) Type" 9 "Japan (JAP) Type" 10 "Russia?(RUS) Type" 11 "RESERVED" 12 "RESERVED" 13 "RESERVED" 14 "RESERVED" 15 "RESERVED" 16 "RESERVED" 17 "RESERVED" 18 "RESERVED" 19 "RESERVED" 20 "RESERVED" 21 "RESERVED" 22 "RESERVED" 23 "RESERVED" 24 "RESERVED" 25 "RESERVED" 26 "RESERVED" 27 "RESERVED" 28 "RESERVED" 29 "RESERVED" 30 "RESERVED" 31 "Inavlid" ;
VAL_ 957 BltnCamSTRM_ServiceStatus 0 "Default, UNKNOWN status for initialization or NONE" 1 "Standard Quality" 2 "Premium Quility" 3 "RESERVED" 4 "RESERVED" 5 "RESERVED" 6 "RESERVED" 7 "Invalid" ;
VAL_ 957 BLTN_CAM_PMD_Oprable_Time 0 "0x0~0xFB:the hours of Parked Motion Detection Mode Operatable" 251 "0x0~0xFB:the hours of Parked Motion Detection Mode Operatable" 252 "RESERVED" 253 "Auxiliary Battery is not connected. - Auxiliary Battery applicable on this vehicle model" 254 "Auxiliary Battery Is not connected. ? Auxiliary Battery not applicable on this vehicle model" 255 "Invalid" ;
VAL_ 957 BLTN_CAM_PMD_Oprable_Time_Max 0 "0x0~0xFB:the hours of Parked Motion Detection Mode Operatable Max" 251 "0x0~0xFB:the hours of Parked Motion Detection Mode Operatable Max" 252 "RESERVED" 253 "Auxiliary Battery is not connected. - Auxiliary Battery applicable on this vehicle model" 254 "Auxiliary Battery is not connected. ? Auxiliary Battery not applicable on this vehicle model" 255 "Invalid" ;
VAL_ 957 BLTN_CAM_RecSta_PMD 0 "Off" 1 "Recording" 2 "Radar only operating(no recording)" 3 "Invalid" ;
VAL_ 957 BLTN_CAM_RecSta_BPR 0 "Off" 1 "Recording" 2 "RESERVED" 3 "Inavlid" ;
VAL_ 957 BLTN_CAM_BPR_Spprt_Info 0 "None" 1 "Support" 2 "RESERVED" 3 "invalid" ;
VAL_ 957 BLTN_CAM_PDC_Reset_Opt 0 "NotApplied" 1 "Applied" 2 "RESERVED" 3 "Invalid" ;
VAL_ 957 BLTN_CAM_RecSta_LPE 0 "Off" 1 "Recording" 2 "Low Power only operating(no recording)" 3 "Invalid" ;
VAL_ 957 BLTN_CAM_DistributeInfo 1 "Korea (KOR) Type" 2 "General Type" 3 "Middle East (MES) Type" 4 "Europe (EUR) Type" 5 "Australia (AUS) Type" 6 "Canada Type" 7 "North America?(NA) Type" 8 "China?(CHN) Type" 9 "Japan (JAP) Type" 10 "Russia?(RUS) Type" 11 "RESERVED" 12 "RESERVED" 13 "RESERVED" 14 "RESERVED" 15 "RESERVED" 16 "RESERVED" 17 "RESERVED" 18 "RESERVED" 19 "RESERVED" 20 "RESERVED" 21 "RESERVED" 22 "RESERVED" 23 "RESERVED" 24 "RESERVED" 25 "RESERVED" 26 "RESERVED" 27 "RESERVED" 28 "RESERVED" 29 "RESERVED" 30 "RESERVED" 31 "RESERVED" 32 "RESERVED" 33 "RESERVED" 34 "RESERVED" 35 "RESERVED" 36 "RESERVED" 37 "RESERVED" 38 "RESERVED" 39 "RESERVED" 40 "RESERVED" 41 "RESERVED" 42 "RESERVED" 43 "RESERVED" 44 "RESERVED" 45 "RESERVED" 46 "RESERVED" 47 "RESERVED" 48 "RESERVED" 49 "RESERVED" 50 "RESERVED" 51 "RESERVED" 52 "RESERVED" 53 "RESERVED" 54 "RESERVED" 55 "RESERVED" 56 "RESERVED" 57 "RESERVED" 58 "RESERVED" 59 "RESERVED" 60 "RESERVED" 61 "RESERVED" 62 "RESERVED" 63 "Invalid" 0 "Default (Korea) Type" ;
VAL_ 957 BLTN_CAM_Sta_STRM 0 "Not Support" 1 "Available" 2 "Sessioning" 3 "Streaming" 4 "RESERVED" 5 "RESERVED" 6 "RESERVED" 7 "RESERVED" 8 "RESERVED" 9 "RESERVED" 10 "Not Available - DashCam Error" 11 "Not Available - Daily time of use exceeded" 12 "Not Available - Daily Number of uses exceeded" 13 "Not Available - Monthly time of use exceeded" 14 "Not Available - Monthly Number of uses exceeded" 15 "Invalid" ;
VAL_ 957 BLTN_CAM_LPE_Option 0 "Default" 1 "Applied(ICE/HEV)" 2 "Not Applied(EV or No LPE Function)" 3 "Invalid" ;
VAL_ 957 BLTN_CAM_State 0 "BLTN_CAM Valid" 1 "BLTN_CAM Front Camera Invalid" 2 "BLTN_CAM Rear Camera Invalid" 3 "BLTN_CAM Front/Rear Camera Inavlid" 4 "BLTN_CAM Record Invalid" 5 "Reserved" 6 "Reserved" 7 "Reserved" 8 "Reserved" 9 "Reserved" 10 "Reserved" 11 "Reserved" 12 "Reserved" 13 "Reserved" 14 "Reserved" 15 "Invalid" ;
VAL_ 957 BLTN_CAM_SD_Card_State 0 "Good, SD card is OK.(Green State)" 1 "SD card replacement recommend.(Yallow State)" 2 "SD card replacement required.(Red State)" 3 "SD card unrecognizable or No SD card found." 4 "Insufficient SD card capacity spec (BLTN_CAM 2/2.5 : 64GB or Higher, BLTN_CAM3 : 128GB or Higher)" 5 "SD card file system is not for Built-in Cam(Built-in CAM only support exFAT filesystem)" 6 "SD card not enough free space, need more free space for built-in Cam(less than 32GByte, must be 32GB" 7 "SD card recognized but Health State is not available (Gray State)" 8 "SD card Unmounted" 9 "RESERVED" 10 "RESERVED" 11 "RESERVED" 12 "RESERVED" 13 "RESERVED" 14 "RESERVED" 15 "Invalid(Red State)" ;
VAL_ 957 BLTN_CAM_RecSta_OWD 0 "Off" 1 "Recording" 2 "Reserved" 3 "invalid" ;
VAL_ 957 BLTN_CAM_RecSta_DEV 0 "Off" 1 "Recording" 2 "Reserved" 3 "invalid" ;
VAL_ 957 BLTN_CAM_RecSta_MAR 0 "Off" 1 "Recording" 2 "Reserved" 3 "invalid" ;
VAL_ 957 BLTN_CAM_RecSta_TML 0 "Off" 1 "Recording" 2 "Reserved" 3 "invalid" ;
VAL_ 957 BLTN_CAM_RecSta_OWP 0 "Off" 1 "Recording" 2 "Reserved" 3 "invalid" ;
VAL_ 957 BLTN_CAM_RecSta_PEV 0 "Off" 1 "Recording" 2 "Reserved" 3 "invalid" ;
VAL_ 957 BLTN_CAM_Prk_EV_Cnt 0 "0x0~0xC8:the number of the Park Event Record(0~200)" 200 "0x0~0xC8:the number of the Park Event Record(0~200)" 201 "Reserved" 202 "Reserved" 203 "Reserved" 204 "Reserved" 205 "Reserved" 206 "Reserved" 207 "Reserved" 208 "Reserved" 209 "Reserved" 210 "Reserved" 211 "Reserved" 212 "Reserved" 213 "Reserved" 214 "Reserved" 215 "Reserved" 216 "Reserved" 217 "Reserved" 218 "Reserved" 219 "Reserved" 220 "Reserved" 221 "Reserved" 222 "Reserved" 223 "Reserved" 224 "Reserved" 225 "Reserved" 226 "Reserved" 227 "Reserved" 228 "Reserved" 229 "Reserved" 230 "Reserved" 231 "Reserved" 232 "Reserved" 233 "Reserved" 234 "Reserved" 235 "Reserved" 236 "Reserved" 237 "Reserved" 238 "Reserved" 239 "Reserved" 240 "Reserved" 241 "Reserved" 242 "Reserved" 243 "Reserved" 244 "Reserved" 245 "Reserved" 246 "Reserved" 247 "Reserved" 248 "Reserved" 249 "Reserved" 250 "Reserved" 251 "Reserved" 252 "Over than 200 count" 253 "Park Mode was not Excuted" 254 "Park Mode was not Supported" 255 "invalid" ;
VAL_ 957 BLTN_CAM_Prk_Oped_Time 0 "Park Mode was not Excuted" 1 "1~0xFB:the hours of Park Mode Operated" 251 "1~0xFB:the hours of Park Mode Operated" 252 "RESERVED" 253 "RESERVED" 254 "RESERVED" 255 "invalid" ;
VAL_ 686 HU_Car_Crc1Val 0 "0x0~0xFFFF:CRCValue" 65535 "0x0~0xFFFF:CRCValue" ;
VAL_ 686 HU_Car_AlvCnt1Val 0 "0x0~0xFF:AlvCntValue" 255 "0x0~0xFF:AlvCntValue" ;
VAL_ 686 HU_IncomingCallState 0 "Default" 1 "Call is Incoming" 2 "Incoming call connected/disconcetced" 3 "RESERVED" 4 "RESERVED" 5 "RESERVED" 6 "RESERVED" 7 "Invalid" ;
VAL_ 686 HU_HardReset_Available 0 "Not Available" 1 "Available" ;
VAL_ 686 HU_MKBD_ModeSwitch 0 "Key off" 1 "AVNT mode on" 2 "DATC mode on" 3 "Invalid" ;
VAL_ 686 HU_VehiclePwr 0 "Key out or Audio OFF" 1 "Not used" 2 "ACC or Audio ON" 3 "KBD Wake-up" 4 "Waiting for Good-Bye (Key out or Audio OFF)" 5 "Not used" 6 "Not used" 7 "Not used" 8 "Not used" 9 "Not used" 10 "Not used" 11 "Not used" 12 "Not used" 13 "Not used" 14 "Not used" 15 "Invalid" ;
VAL_ 686 HU_BtnShowReq 0 "default" 1 "on" 2 "off" 3 "reserved" 4 "reserved" 5 "reserved" 6 "reserved" 7 "invalid" ;
VAL_ 686 HU_ADMSettingState 0 "ADM On (Setting Vaule in HU)" 1 "ADM Off" 2 "Reserved" 3 "Reserved" 4 "Reserved" 5 "Reserved" 6 "Reserved" 7 "Invalid" ;
VAL_ 686 HU_PwrState 0 "Default" 1 "Normal On" 2 "ADM" 3 "Wait for door open" 4 "Logic Off" 5 "Remote Engine On" 6 "Reserved" 7 "Reserved" 8 "Reserved" 9 "Reserved" 10 "Reserved" 11 "Reserved" 12 "Reserved" 13 "Reserved" 14 "Reserved" 15 "Invalid" ;
VAL_ 686 HU_LCDState 0 "Default" 1 "On" 2 "Off" 3 "RESERVED" 4 "RESERVED" 5 "RESERVED" 6 "RESERVED" 7 "Invalid" ;
VAL_ 274 HU_USM_Crc2Val 0 "0x0~0xFFFF:CRCValue" 65535 "0x0~0xFFFF:CRCValue" ;
VAL_ 274 CF_AVN_CluRheostatLvl 0 "Reserved" 1 "Step 1" 2 "Step 2" 3 "Step 3" 4 "Step 4" 5 "Step 5" 6 "Step 6" 7 "Step 7" 8 "Step 8" 9 "Step 9" 10 "Step 10" 11 "Step 11" 12 "Step 12" 13 "Step 13" 14 "Step 14" 15 "Step 15" 16 "Step 16" 17 "Step 17" 18 "Step 18" 19 "Step 19" 20 "Step 20(Reset Value)" 21 "Step 21(Detent)" 22 "Reserved" 23 "Reserved" 24 "Reserved" 25 "Reserved" 26 "Reserved" 27 "Reserved" 28 "Reserved" 29 "Reserved" 30 "Reserved" 31 "Invalid" ;
VAL_ 274 CF_AVN_EVReset 0 "Default" 1 "USM Reset" 2 "Reserved" 3 "Invalid" ;
VAL_ 274 CF_AVN_UnitReset 0 "Default" 1 "Unit Reset" 2 "Reserved" 3 "Invalid" ;
VAL_ 274 CF_AVN_IcyRoadWarn 0 "Default" 1 "Off" 2 "On" 3 "Invalid" ;
VAL_ 274 CF_AVN_CluServiceReminderReset 0 "Default" 1 "Service Reminder Reset" 2 "Reserved" 3 "Invalid" ;
VAL_ 274 CF_AVN_CluUSMReset 0 "Default" 1 "USM Reset" 2 "RESERVED" 3 "Invalid" ;
VAL_ 274 C_HCIMSWeightNValueSet 0 "Default" 1 "Under 49.4kg" 2 "49.5~59.4kg" 3 "59.5~69.4kg" 4 "69.5~79.4kg" 5 "79.5~89.4kg" 6 "89.5~99.4kg" 7 "99.5~109.4kg" 8 "109.5~119.4kg" 9 "More than 119.5kg" 10 "Reserved" 11 "Reserved" 12 "Reserved" 13 "Reserved" 14 "Reserved" 15 "Invalid" ;
VAL_ 274 C_HCIMSHeightNvalueSet 0 "Default" 1 "Less than 147.5cm" 2 "147.5~152.4cm" 3 "152.5~157.4cm" 4 "157.5~162.4cm" 5 "162.5~167.4cm" 6 "167.5~172.4cm" 7 "172.5~177.4cm" 8 "177.5~182.4cm" 9 "182.5~187.4cm" 10 "187.5~192.4cm" 11 "192.5~197.4cm" 12 "more than 197.5cm" 13 "Reserved" 14 "Reserved" 15 "Invalid" ;
VAL_ 274 CF_AVN_HCIMSButtonCommand 0 "Default" 1 "Health Care IMS Exit" 2 "Detail View" 3 "Move to recommend position" 4 "Current position Analysis" 5 "Move to setting page" 6 "Save view" 7 "IMS1 saved" 8 "IMS2 saved" 9 "Summary view" 10 "Smart IMS On" 11 "Reserved" 12 "Reserved" 13 "Reserved" 14 "Reserved" 15 "Invalid" ;
VAL_ 274 C_HCIMSSitHeightNValueSet 0 "Default" 1 "Tall" 2 "Middle" 3 "Short" 4 "Reserved" 5 "Reserved" 6 "Reserved" 7 "Reserved" 8 "Reserved" 9 "Reserved" 10 "Reserved" 11 "Reserved" 12 "Reserved" 13 "Reserved" 14 "Reserved" 15 "Invalid" ;
VAL_ 274 CF_AVN_BodySpprtSet 0 "Default" 1 "Off" 2 "On" 3 "Invalid" ;
VAL_ 274 HU_USM_AlvCnt2Val 0 "0x0~0xFF:AlvCntValue" 255 "0x0~0xFF:AlvCntValue" ;
VAL_ 274 CF_AVN_AirSptTimeNValueSet 0 "Default" 1 "Short" 2 "Normal" 3 "Long" 4 "Reserved" 5 "Reserved" 6 "Reserved" 7 "Invalid" ;
VAL_ 274 CF_AVN_AirSptStrNValue 0 "Default" 1 "Normal" 2 "Intense" 3 "Invalid" ;
VAL_ 274 CF_AVN_SeatDrvModNValueSet 0 "Default" 1 "Off" 2 "On" 3 "Invalid" ;
VAL_ 274 C_SmrtSldngDrNValueSet 0 "Default" 1 "Off" 2 "On" 3 "Reserved" 4 "Reserved" 5 "Reserved" 6 "Reserved" 7 "Invalid" ;
VAL_ 274 CF_AVN_TurboPressureUnit 0 "Default" 1 "Psi" 2 "kPa" 3 "bar" 4 "Reserved" 5 "Reserved" 6 "Reserved" 7 "Invalid" ;
VAL_ 274 CF_AVN_CluTorqueUnit 0 "Default" 1 "Nm" 2 "lb_ft" 3 "Invalid" ;
VAL_ 274 CF_AVN_MoodLpRedNValueSet 0 "0x000~0x0FF:Red Color 0~255 (User Selection)" 255 "0x000~0x0FF:Red Color 0~255 (User Selection)" 256 "100~0x1FF:Red Color 0~255 (Expert Recommendation)" 511 "100~0x1FF:Red Color 0~255 (Expert Recommendation)" 512 "Default" 1023 "Invalid" ;
VAL_ 274 CF_AVN_MoodLpGreenNValueSet 0 "0x000~0x0FF:Green Color 0~255 (User Selection)" 255 "0x000~0x0FF:Green Color 0~255 (User Selection)" 256 "100~0x1FF:Green Color 0~255 (Expert Recommendation)" 511 "100~0x1FF:Green Color 0~255 (Expert Recommendation)" 512 "Default" 1023 "Invalid" ;
VAL_ 274 CF_AVN_MoodLpBlueNValueSet 0 "0x000~0x0FF:Blue Color 0~255 (User Selection)" 255 "0x000~0x0FF:Blue Color 0~255 (User Selection)" 256 "100~0x1FF:Blue Color 0~255 (Expert Recommendation)" 511 "100~0x1FF:Blue Color 0~255 (Expert Recommendation)" 512 "Default" 1023 "Invalid" ;
VAL_ 274 CF_AVN_MoodLpBrightNValueSet 0 "Default" 1 "Off" 2 "Level 1" 3 "Level 2" 4 "Level 3" 5 "Level 4" 6 "Level 5" 7 "Level 6" 8 "Level 7" 9 "Level 8" 10 "Level 9" 11 "Level 10" 12 "Reserved" 13 "Reserved" 14 "Reserved" 15 "Invalid" ;
VAL_ 274 CF_AVN_HBANValueSet 0 "Default" 1 "Off" 2 "On" 3 "Invalid" ;
VAL_ 274 CF_AVN_IFSActVehSpd_Set 0 "Default" 1 "Vehicle Speed Function Off" 2 "10km_h" 3 "20km_h" 4 "30km_h" 5 "40km_h" 6 "50km_h" 7 "60km_h" 8 "70km_h" 9 "80km_h" 10 "90km_h" 11 "100km_h" 12 "Reserved" 13 "Reserved" 14 "Reserved" 15 "Invalid" ;
VAL_ 274 C_MoodLpDrivingNValue 0 "Default" 1 "OFF" 2 "ON" 3 "Invalid" ;
VAL_ 274 HU_DrivingPostureAssistUSMSet 0 "Default" 1 "Off" 2 "10min" 3 "20min" 4 "30min" 5 "40min" 6 "50min" 7 "60min" 8 "RESERVED" 9 "RESERVED" 10 "RESERVED" 11 "RESERVED" 12 "RESERVED" 13 "RESERVED" 14 "RESERVED" 15 "Invalid" ;
VAL_ 274 C_MoodLPDrivemodeNValue 0 "Default" 1 "Off" 2 "On" 3 "Invalid" ;
VAL_ 274 CF_AVN_SVMAutoOnNvalueSet 0 "Default" 1 "Off" 2 "On" 3 "Invalid" ;
VAL_ 274 CF_AVN_DAW_LVDANValueSet 0 "Default" 1 "Off" 2 "On" 3 "Invalid" ;
VAL_ 274 CF_AVN_Clu3dDepthSet 0 "Default" 1 "Off" 2 "Weak" 3 "Mid" 4 "Strong" 5 "Reserved" 6 "Reserved" 7 "Invalid" ;
VAL_ 274 C_MoodLpFadeNValue 0 "Default" 1 "Off" 2 "On" 3 "Invalid" ;
VAL_ 274 HU_DrvCushAirSprtUSMSet 0 "Default" 1 "Off" 2 "Low" 3 "Mid" 4 "High" 5 "RESERVED" 6 "RESERVED" 7 "Invalid" ;
VAL_ 274 HU_AstCushAirSprtUSMSet 0 "Default" 1 "Off" 2 "Low" 3 "Mid" 4 "High" 5 "RESERVED" 6 "RESERVED" 7 "Invalid" ;
VAL_ 274 HU_DrvStrchMassageSwSet 0 "Default" 1 "Off" 2 "On" 3 "Invalid" ;
VAL_ 274 HU_DrvStrchMassageModeUSMSet 0 "Default" 1 "Mode 1" 2 "Mode 2" 3 "Mode 3" 4 "Mode 4" 5 "Mode 5" 6 "RESERVED" 7 "Invalid" ;
VAL_ 274 HU_DrvStrchMassageStrengthUSMSet 0 "Default" 1 "Weak" 2 "Normal" 3 "Strong" 4 "RESERVED" 5 "RESERVED" 6 "RESERVED" 7 "Invalid" ;
VAL_ 274 HU_DrvStrchMassageTimeUSMSet 0 "Default" 1 "Short" 2 "Normal" 3 "Long" 4 "RESERVED" 5 "RESERVED" 6 "RESERVED" 7 "Invalid" ;
VAL_ 274 HU_AstStrchMassageSwSet 0 "Default" 1 "Off" 2 "On" 3 "Invalid" ;
VAL_ 274 HU_AstStrchMassageModeUSMSet 0 "Default" 1 "Mode 1" 2 "Mode 2" 3 "Mode 3" 4 "Mode 4" 5 "Mode 5" 6 "RESERVED" 7 "Invalid" ;
VAL_ 274 HU_AstStrchMassageStrengthUSMSet 0 "Default" 1 "Weak" 2 "Normal" 3 "Strong" 4 "RESERVED" 5 "RESERVED" 6 "RESERVED" 7 "Invalid" ;
VAL_ 274 HU_AstStrchMassageTimeUSMSet 0 "Default" 1 "Short" 2 "Normal" 3 "Long" 4 "RESERVED" 5 "RESERVED" 6 "RESERVED" 7 "Invalid" ;
VAL_ 274 HU_DrvMsgPulseUSMSet 0 "Default" 1 "Off" 2 "On" 3 "Invalid" ;
VAL_ 274 HU_AstMsgPulseUSMSet 0 "Default" 1 "Off" 2 "On" 3 "Invalid" ;
VAL_ 274 HU_RLMsgPulseUSMSet 0 "Default" 1 "Off" 2 "On" 3 "Invalid" ;
VAL_ 274 HU_RRMsgPulseUSMSet 0 "Default" 1 "Off" 2 "On" 3 "Invalid" ;
VAL_ 274 CF_AVN_CluWelcomeSnd 0 "Default" 1 "Off" 2 "On" 3 "Invalid" ;
VAL_ 274 CF_AVN_CluServiceReminderSet 0 "Default" 1 "Off" 2 "On" 3 "Invalid" ;
VAL_ 274 CF_AVN_CluTransmissionDisp 0 "Default" 1 "Off" 2 "On" 3 "Invalid" ;
VAL_ 274 CF_AVN_CluWiperLight 0 "Default" 1 "Off" 2 "On" 3 "Invalid" ;
VAL_ 274 CF_AVN_CluRoadInfoGuide 0 "Default" 1 "Off" 2 "On" 3 "Invalid" ;
VAL_ 274 CF_AVN_CluUserSettingPeriod 0 "0~99month" 1 "0~99month" 2 "0~99month" 3 "0~99month" 4 "0~99month" 5 "0~99month" 6 "0~99month" 7 "0~99month" 8 "0~99month" 9 "0~99month" 10 "0~99month" 11 "0~99month" 12 "0~99month" 13 "0~99month" 14 "0~99month" 15 "0~99month" 16 "0~99month" 17 "0~99month" 18 "0~99month" 19 "0~99month" 20 "0~99month" 21 "0~99month" 22 "0~99month" 23 "0~99month" 24 "0~99month" 25 "0~99month" 26 "0~99month" 27 "0~99month" 28 "0~99month" 29 "0~99month" 30 "0~99month" 31 "0~99month" 32 "0~99month" 33 "0~99month" 34 "0~99month" 35 "0~99month" 36 "0~99month" 37 "0~99month" 38 "0~99month" 39 "0~99month" 40 "0~99month" 41 "0~99month" 42 "0~99month" 43 "0~99month" 44 "0~99month" 45 "0~99month" 46 "0~99month" 47 "0~99month" 48 "0~99month" 49 "0~99month" 50 "0~99month" 51 "0~99month" 52 "0~99month" 53 "0~99month" 54 "0~99month" 55 "0~99month" 56 "0~99month" 57 "0~99month" 58 "0~99month" 59 "0~99month" 60 "0~99month" 61 "0~99month" 62 "0~99month" 63 "0~99month" 64 "0~99month" 65 "0~99month" 66 "0~99month" 67 "0~99month" 68 "0~99month" 69 "0~99month" 70 "0~99month" 71 "0~99month" 72 "0~99month" 73 "0~99month" 74 "0~99month" 75 "0~99month" 76 "0~99month" 77 "0~99month" 78 "0~99month" 79 "0~99month" 80 "0~99month" 81 "0~99month" 82 "0~99month" 83 "0~99month" 84 "0~99month" 85 "0~99month" 86 "0~99month" 87 "0~99month" 88 "0~99month" 89 "0~99month" 90 "0~99month" 91 "0~99month" 92 "0~99month" 93 "0~99month" 94 "0~99month" 95 "0~99month" 96 "0~99month" 97 "0~99month" 98 "0~99month" 99 "0~99month" 100 "Reserved" 101 "Reserved" 102 "Reserved" 103 "Reserved" 104 "Reserved" 105 "Reserved" 106 "Reserved" 107 "Reserved" 108 "Reserved" 109 "Reserved" 110 "Reserved" 111 "Reserved" 112 "Reserved" 113 "Reserved" 114 "Reserved" 115 "Reserved" 116 "Reserved" 117 "Reserved" 118 "Reserved" 119 "Reserved" 120 "Reserved" 121 "Reserved" 122 "Reserved" 123 "Reserved" 124 "Reserved" 125 "Reserved" 126 "Reserved" 127 "Invalid" ;
VAL_ 274 CF_AVN_CluFuelEconUnit_mi 0 "Default" 1 "US gallon" 2 "UK gallon" 3 "Reserved" ;
VAL_ 274 CF_AVN_CluFuelEconUnit_km 0 "Default" 1 "km/L, km/kg, km/kWh" 2 "L/100km, kg/100km, kWh/100km" 3 "Reserved" ;
VAL_ 274 CF_AVN_CluUserSettingDistance 0 "0x0~0x1869F:0~9999km_mi" 99999 "0x0~0x1869F:0~9999km_mi" 131071 "Invalid" ;
VAL_ 685 HU_BLTN_CAM_Crc2Val 0 "0x0~0xFFFF:CRCValue" 65535 "0x0~0xFFFF:CRCValue" ;
VAL_ 685 HU_BLTN_CAM_AlvCnt2Val 0 "0x0~0xFF:AlvCntValue" 255 "0x0~0xFF:AlvCntValue" ;
VAL_ 685 HU_WiFi_State 0 "Off" 1 "WiFi On - AP Not Connected" 2 "AP Connected" 3 "Station connected" 4 "0x4~0xE:RESERVED" 5 "0x4~0xE:RESERVED" 6 "0x4~0xE:RESERVED" 7 "0x4~0xE:RESERVED" 8 "0x4~0xE:RESERVED" 9 "0x4~0xE:RESERVED" 10 "0x4~0xE:RESERVED" 11 "0x4~0xE:RESERVED" 12 "0x4~0xE:RESERVED" 13 "0x4~0xE:RESERVED" 14 "0x4~0xE:RESERVED" 15 "0xF:invalid" ;
VAL_ 685 HU_BLTN_CAM_UI_Mode 0 "HU UI mode" 1 "Built-In Cam Mode(GUI or HU File Access)" 2 "Built-In Cam Setting Mode" 3 "BLTN_CAM Performance Recorder Mode" 4 "RESERVED" 5 "RESERVED" 6 "RESERVED" 7 "RESERVED" 8 "RESERVED" 9 "RESERVED" 10 "RESERVED" 11 "RESERVED" 12 "RESERVED" 13 "RESERVED" 14 "RESERVED" 15 "Invalid" ;
VAL_ 685 HU_BLTN_CAM_Display 0 "AVN Mode" 1 "DVRS Mode" 2 "Popup Mode" 3 "RESERVED" 4 "RESERVED" 5 "Built-in Cam update mode" 6 "RESERVED" 7 "Invalid" ;
VAL_ 138 HU_GW_Crc1Val 0 "0x0~0xFFFF:CRCValue" 65535 "0x0~0xFFFF:CRCValue" ;
VAL_ 138 HU_TgSoc_QcChg_Set 0 "0x0~0xC8:PHY = HEX * 0.5" 200 "0x0~0xC8:PHY = HEX * 0.5" 201 "Reserved" 202 "Reserved" 203 "Reserved" 204 "Reserved" 205 "Reserved" 206 "Reserved" 207 "Reserved" 208 "Reserved" 209 "Reserved" 210 "Reserved" 211 "Reserved" 212 "Reserved" 213 "Reserved" 214 "Reserved" 215 "Reserved" 216 "Reserved" 217 "Reserved" 218 "Reserved" 219 "Reserved" 220 "Reserved" 221 "Reserved" 222 "Reserved" 223 "Reserved" 224 "Reserved" 225 "Reserved" 226 "Reserved" 227 "Reserved" 228 "Reserved" 229 "Reserved" 230 "Reserved" 231 "Reserved" 232 "Reserved" 233 "Reserved" 234 "Reserved" 235 "Reserved" 236 "Reserved" 237 "Reserved" 238 "Reserved" 239 "Reserved" 240 "Reserved" 241 "Reserved" 242 "Reserved" 243 "Reserved" 244 "Reserved" 245 "Reserved" 246 "Reserved" 247 "Reserved" 248 "Reserved" 249 "Reserved" 250 "Reserved" 251 "Reserved" 252 "Reserved" 253 "Reserved" 254 "Reserved" 255 "Invalid" ;
VAL_ 138 HU_UserApproval 0 "Initial Value" 1 "Approve" 2 "Reject" 3 "Start Trigger" 4 "Unrecognized Reject" 5 "RESERVED" 6 "RESERVED" 7 "RESERVED" 8 "RESERVED" 9 "RESERVED" 10 "RESERVED" 11 "RESERVED" 12 "RESERVED" 13 "RESERVED" 14 "Implement Check" 15 "Invalid" ;
VAL_ 138 HU_OtaInfomationReq 0 "Initial" 1 "Vehicle S/W Version" 2 "What's New (Text Only)" 3 "Download progress" 4 "Update progress" 5 "Reserved" 6 "Reserved" 7 "Reserved" 8 "Reserved" 9 "Reserved" 10 "Reserved" 11 "Reserved" 12 "Reserved" 13 "Reserved" 14 "Reserved" 15 "Invalid" ;
VAL_ 138 HU_ICU_RearDefSet 0 "Defog Off" 1 "Defog On" 2 "reserved" 3 "Invalid" ;
VAL_ 138 HU_CDMOpenCmd 0 "Default" 1 "CDM Open" 2 "CDM Close" 3 "Invalid" ;
VAL_ 138 C_PreCrankReq 0 "Default" 1 "Req On" 2 "Not Support" 3 "Invalid" ;
VAL_ 138 HU_GW_AlvCnt1Val 0 "0x0~0xFF:AlvCntValue" 255 "0x0~0xFF:AlvCntValue" ;
VAL_ 138 C_TeleAstSeatOpCmdIBOX 0 "Init" 1 "Unused" 2 "Seat Heat&Vent OFF" 3 "Seat_Vent_Low" 4 "Seat_Vent_Mid" 5 "Seat_Vent_High" 6 "Seat_Heat_Low" 7 "Seat_Heat_Mid" 8 "Seat_Heat_High" 9 "Unused" 10 "Unused" 11 "Unused" 12 "Unused" 13 "Unused" 14 "Unused" 15 "Invalid" ;
VAL_ 138 C_TeleDrvSeatOpCmdIBOX 0 "Init" 1 "Unused" 2 "Seat Heat&Vent OFF" 3 "Seat_Vent_Low" 4 "Seat_Vent_Mid" 5 "Seat_Vent_High" 6 "Seat_Heat_Low" 7 "Seat_Heat_Mid" 8 "Seat_Heat_High" 9 "Unused" 10 "Unused" 11 "Unused" 12 "Unused" 13 "Unused" 14 "Unused" 15 "Invalid" ;
VAL_ 138 C_TeleRRSeatOpCmdIBOX 0 "Init" 1 "Unused" 2 "Seat Heat&Vent OFF" 3 "Seat_Vent_Low" 4 "Seat_Vent_Mid" 5 "Seat_Vent_High" 6 "Seat_Heat_Low" 7 "Seat_Heat_Mid" 8 "Seat_Heat_High" 9 "Unused" 10 "Unused" 11 "Unused" 12 "Unused" 13 "Unused" 14 "Unused" 15 "Invalid" ;
VAL_ 138 C_TeleRLSeatOpCmdIBOX 0 "Init" 1 "Unused" 2 "Seat Heat&Vent OFF" 3 "Seat_Vent_Low" 4 "Seat_Vent_Mid" 5 "Seat_Vent_High" 6 "Seat_Heat_Low" 7 "Seat_Heat_Mid" 8 "Seat_Heat_High" 9 "Unused" 10 "Unused" 11 "Unused" 12 "Unused" 13 "Unused" 14 "Unused" 15 "Invalid" ;
VAL_ 138 C_DrvPSDCloseRlyIBOX 0 "OFF" 1 "ON" 2 "Panic stop" 3 "Invalid" ;
VAL_ 138 C_DrvPSDOpenRlyIBOX 0 "OFF" 1 "ON" 2 "Panic stop" 3 "Invalid" ;
VAL_ 138 C_AstPSDCloseRlyIBOX 0 "OFF" 1 "ON" 2 "Panic stop" 3 "Invalid" ;
VAL_ 138 C_AstPSDOpenRlyIBOX 0 "OFF" 1 "ON" 2 "Panic stop" 3 "Invalid" ;
VAL_ 138 HU_StrgWhlHeatingSet_VR 0 "Default" 1 "Step1 On" 2 "Step2 On" 3 "Off" 4 "Reserved" 5 "Reserved" 6 "Reserved" 7 "Invalid" ;
VAL_ 138 AVN_VGS_SET 0 "Default" 1 "Off" 2 "On" 3 "Invalid" ;
VAL_ 138 MODE_VCU_SET2 0 "Normal" 1 "Sport" 2 "Eco" 3 "Sport+" 4 "Smart" 5 "Snow" 6 "RESERVED" 7 "Invalid" ;
VAL_ 138 AVN_DriftMode_SET 0 "Default" 1 "Off" 2 "On" 3 "RESERVED" 4 "RESERVED" 5 "RESERVED" 6 "RESERVED" 7 "Invalid" ;
VAL_ 138 AVN_NduranceRace_SET 0 "Default" 1 "Off" 2 "On" 3 "RESERVED" 4 "RESERVED" 5 "RESERVED" 6 "RESERVED" 7 "Invalid" ;
VAL_ 138 AVN_MaxRange_SET 0 "Default" 1 "Off" 2 "On" 3 "RESERVED" 4 "RESERVED" 5 "RESERVED" 6 "RESERVED" 7 "Invalid" ;
VAL_ 138 HU_MKBD_TouchSensSet 0 "Default" 1 "Low" 2 "Mid" 3 "High" 4 "RESERVED" 5 "RESERVED" 6 "RESERVED" 7 "Invalid" ;
VAL_ 138 AVN_NTDBalance_SET 0 "Default" 1 "0%" 2 "10%" 3 "20%" 4 "30%" 5 "40%" 6 "50%" 7 "60%" 8 "70%" 9 "80%" 10 "90%" 11 "100%" 12 "RESERVED" 13 "RESERVED" 14 "RESERVED" 15 "Invalid" ;
VAL_ 138 LaunchControl_Activate_EV 0 "Default" 1 "Launch Control Off" 2 "Launch Control On" 3 "Invalid" ;
VAL_ 138 LaunchControl_GripLevel_Reset 0 "Default" 1 "Normal state" 2 "Reset" 3 "Invalid" ;
VAL_ 138 LaunchControl_GripLevel_Set 0 "Default" 1 "Grip level 1" 2 "Grip level 2" 3 "Grip level 3" 4 "Grip level 4" 5 "Grip level 5" 6 "Grip level 6" 7 "Invalid" ;
VAL_ 138 MODE_Drift_TCS_SET 0 "Default" 1 "Slip leve 01" 2 "Slip leve 02" 3 "Slip leve 03" 4 "Slip leve 04" 5 "Slip leve 05" 6 "Slip leve 06" 7 "Slip leve 07" 8 "Slip leve 08" 9 "Slip leve 09" 10 "Slip leve 10" 11 "RESERVED" 12 "RESERVED" 13 "RESERVED" 14 "RESERVED" 15 "Invalid" ;
VAL_ 138 MODE_Drift_VDC_SET 0 "Default" 1 "Beginner" 2 "Intermediate" 3 "Expert" 4 "RESERVED" 5 "RESERVED" 6 "RESERVED" 7 "Invalid" ;
VAL_ 138 HU_Popupdown_Req 0 "Default" 1 "Popup_request" 2 "Popdown_request" 3 "Invalid" ;
VAL_ 138 MODE_Drift_MDPS_SET 0 "Default" 1 "N-Mode" 2 "Drift Mode" 3 "Invalid" ;
VAL_ 138 MODE_Drift_ECS_SET 0 "Default" 1 "N-Mode" 2 "Drift Mode" 3 "Invalid" ;
VAL_ 138 MODE_Drift_ELSD_SET 0 "Default" 1 "Drift 1.5 way" 2 "Drift 2.0 way" 3 "Invalid" ;
VAL_ 138 HU_NCond_DragSet 0 "Default" 1 "N conditioning Drag Off" 2 "N conditioning Drag On" 3 "Invalid" ;
VAL_ 138 HU_NCond_TrackSet 0 "Default" 1 "N Conditioning Track Off" 2 "N Conditioning Track On" 3 "Invalid" ;
VAL_ 138 AVN_Npedal_SET 0 "Default" 1 "Off" 2 "On" 3 "RESERVED" 4 "RESERVED" 5 "RESERVED" 6 "RESERVED" 7 "Invalid" ;
VAL_ 138 AVN_NTD_SET 0 "Default" 1 "Off" 2 "On" 3 "RESERVED" 4 "RESERVED" 5 "RESERVED" 6 "RESERVED" 7 "Invalid" ;
VAL_ 138 HU_PopupAgreement_Push 0 "Normal(Off)" 1 "Popup_Yes" 2 "RESERVED" 3 "Invalid" ;
VAL_ 138 HU_StayModeStartReq 0 "Default" 1 "Off" 2 "On" 3 "RESERVED" 4 "RESERVED" 5 "RESERVED" 6 "RESERVED" 7 "Invalid" ;
VAL_ 138 HU_StayModeReservationReq 0 "Default" 1 "Off" 2 "On" 3 "RESERVED" 4 "RESERVED" 5 "RESERVED" 6 "RESERVED" 7 "Invalid" ;
VAL_ 138 HU_StayModeExtensionReq 0 "Default" 1 "Off" 2 "On" 3 "RESERVED" 4 "RESERVED" 5 "RESERVED" 6 "RESERVED" 7 "Invalid" ;
VAL_ 138 HU_StayModeSetReq 0 "Default" 1 "Off" 2 "On" 3 "RESERVED" 4 "RESERVED" 5 "RESERVED" 6 "RESERVED" 7 "Invalid" ;
VAL_ 138 HU_StayModeIdleTimeSetReq 0 "Default" 1 "0min" 2 "2min" 3 "3min" 4 "5min" 5 "10min" 6 "Unlimited" 7 "RESERVED" 8 "RESERVED" 9 "RESERVED" 10 "RESERVED" 11 "RESERVED" 12 "RESERVED" 13 "RESERVED" 14 "RESERVED" 15 "Invalid" ;
VAL_ 138 HU_StayModeMaxTimeSetReq 0 "Default" 1 "1st Option" 2 "2nd Option" 3 "3rd Option" 4 "4th Option" 5 "5th Option" 6 "6th Option" 7 "7th Option" 8 "8th Option" 9 "9th Option" 10 "10th Option" 11 "RESERVED" 12 "RESERVED" 13 "RESERVED" 14 "RESERVED" 15 "Invalid" ;
VAL_ 138 MODE_Drift_VDC_Level_SET 0 "default" 1 "VDC level_01" 2 "VDC level_02" 3 "VDC level_03" 4 "VDC level_04" 5 "VDC level_05" 6 "VDC level_06" 7 "VDC level_07" 8 "VDC level_08" 9 "VDC level_09" 10 "VDC level_10" 11 "RESERVED" 12 "RESERVED" 13 "RESERVED" 14 "RESERVED" 15 "RESERVED" ;
VAL_ 138 MODE_Drift_RTO_Level_SET 0 "Default" 1 "RTO leve 0" 2 "RTO leve 1" 3 "RTO leve 2" 4 "RTO leve 3" 5 "RESERVED" 6 "RESERVED" 7 "RESERVED" ;
VAL_ 138 HU_SafetyModeReq 0 "Default" 1 "Off" 2 "On" 3 "Invalid" ;
VAL_ 138 HU_DriveConfirmPopup 0 "Default" 1 "No" 2 "Yes" 3 "Invalid" ;
VAL_ 138 HU_LghtDnSafetyModReq 0 "Default" 1 "Off" 2 "On" 3 "Invalid" ;
VAL_ 138 SWRC_Sensitivity_SET 0 "Medium(default)" 1 "Low" 2 "High" 3 "Invalid" ;
VAL_ 138 HU_ChgInCurrModSet 0 "Default" 1 "Maximum" 2 "Decreasing" 3 "Minimum" 4 "Reserved" 5 "Reserved" 6 "Reserved" 7 "Invalid" ;
VAL_ 138 HU_EV_WinterMode 0 "Winter mode Off" 1 "Winter mode On" 2 "Reserved" 3 "Invalid" ;
VAL_ 138 HU_TgSoc_ScChg_Set 0 "0x0~0xC8:PHY = HEX * 0.5" 200 "0x0~0xC8:PHY = HEX * 0.5" 201 "Reserved" 202 "Reserved" 203 "Reserved" 204 "Reserved" 205 "Reserved" 206 "Reserved" 207 "Reserved" 208 "Reserved" 209 "Reserved" 210 "Reserved" 211 "Reserved" 212 "Reserved" 213 "Reserved" 214 "Reserved" 215 "Reserved" 216 "Reserved" 217 "Reserved" 218 "Reserved" 219 "Reserved" 220 "Reserved" 221 "Reserved" 222 "Reserved" 223 "Reserved" 224 "Reserved" 225 "Reserved" 226 "Reserved" 227 "Reserved" 228 "Reserved" 229 "Reserved" 230 "Reserved" 231 "Reserved" 232 "Reserved" 233 "Reserved" 234 "Reserved" 235 "Reserved" 236 "Reserved" 237 "Reserved" 238 "Reserved" 239 "Reserved" 240 "Reserved" 241 "Reserved" 242 "Reserved" 243 "Reserved" 244 "Reserved" 245 "Reserved" 246 "Reserved" 247 "Reserved" 248 "Reserved" 249 "Reserved" 250 "Reserved" 251 "Reserved" 252 "Reserved" 253 "Reserved" 254 "Reserved" 255 "Invalid" ;
